VERSION "June 2, 2025"

NS_ :

BS_:

BU_: VEH CH Receiver Receiver ChassisBus VehicleBus PartyBus

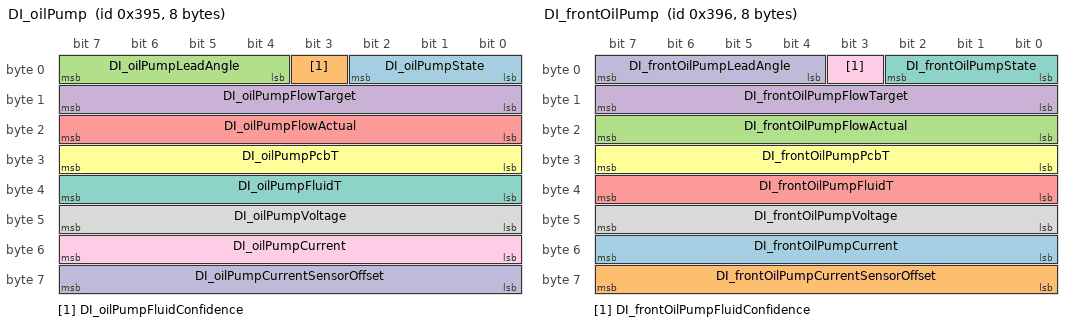
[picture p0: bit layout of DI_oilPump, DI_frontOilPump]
BO_ 917 DI_oilPump: 8 VEH
 SG_ DI_oilPumpState : 0|3@1+ (1,0) [0|0] "" Vector__XXX
 SG_ DI_oilPumpFluidConfidence : 3|1@1+ (1,0) [0|0] "" Vector__XXX
 SG_ DI_oilPumpLeadAngle : 4|4@1+ (1.875,0) [0|28.125] "deg" Vector__XXX
 SG_ DI_oilPumpFlowTarget : 8|8@1+ (0.06,0) [0|0] "LPM" Vector__XXX
 SG_ DI_oilPumpFlowActual : 16|8@1+ (0.06,0) [0|0] "LPM" Vector__XXX
 SG_ DI_oilPumpPcbT : 24|8@1+ (1,-40) [0|0] "DegC" Vector__XXX
 SG_ DI_oilPumpFluidT : 32|8@1+ (1,-40) [0|0] "DegC" Vector__XXX
 SG_ DI_oilPumpVoltage : 40|8@1+ (0.1,0) [0|0] "V" Vector__XXX
 SG_ DI_oilPumpCurrent : 48|8@1+ (0.1,0) [0|0] "A" Vector__XXX
 SG_ DI_oilPumpCurrentSensorOffset : 56|8@1+ (0.005,0) [0|0] "A" Vector__XXX

BO_ 918 DI_frontOilPump: 8 VEH
 SG_ DI_frontOilPumpCurrent : 48|8@1+ (0.1,0) [0|0] "A" Vector__XXX
 SG_ DI_frontOilPumpCurrentSensorOffset : 56|8@1+ (0.005,0) [0|0] "A" Vector__XXX
 SG_ DI_frontOilPumpFlowActual : 16|8@1+ (0.06,0) [0|0] "LPM" Vector__XXX
 SG_ DI_frontOilPumpFlowTarget : 8|8@1+ (0.06,0) [0|0] "LPM" Vector__XXX
 SG_ DI_frontOilPumpFluidT : 32|8@1+ (1,-40) [0|0] "DegC" Vector__XXX
 SG_ DI_frontOilPumpPcbT : 24|8@1+ (1,-40) [0|0] "DegC" Vector__XXX
 SG_ DI_frontOilPumpState : 0|3@1+ (1,0) [0|0] "" Vector__XXX
 SG_ DI_frontOilPumpVoltage : 40|8@1+ (0.1,0) [0|0] "V" Vector__XXX
 SG_ DI_frontOilPumpFluidConfidence : 3|1@1+ (1,0) [0|0] "" Vector__XXX
 SG_ DI_frontOilPumpLeadAngle : 4|4@1+ (1.875,0) [0|28.125] "deg" Vector__XXX

BO_ 921 DAS_status: 8 CH
 SG_ DAS_autoLaneChangeState : 46|5@1+ (1,0) [0|0] "" Vector__XXX
 SG_ DAS_autoParked : 25|1@1+ (1,0) [0|0] "" Vector__XXX
 SG_ DAS_autoparkReady : 24|1@1+ (1,0) [0|0] "" Vector__XXX
 SG_ DAS_autoparkWaitingForBrake : 26|1@1+ (1,0) [0|0] "" Vector__XXX
 SG_ DAS_autopilotHandsOnState : 42|4@1+ (1,0) [0|0] "" Vector__XXX
 SG_ DAS_autopilotState : 0|4@1+ (1,0) [0|0] "" Vector__XXX
 SG_ DAS_blindSpotRearLeft : 4|2@1+ (1,0) [0|0] "" Vector__XXX
 SG_ DAS_blindSpotRearRight : 6|2@1+ (1,0) [0|0] "" Vector__XXX
 SG_ DAS_csaState : 35|2@1+ (1,0) [0|0] "" Vector__XXX
 SG_ DAS_fleetSpeedState : 40|2@1+ (1,0) [0|0] "" Vector__XXX
 SG_ DAS_forwardCollisionWarning : 22|2@1+ (1,0) [0|0] "" Vector__XXX
 SG_ DAS_fusedSpeedLimit : 8|5@1+ (5,0) [0|0] "kph/mph" Vector__XXX
 SG_ DAS_heaterState : 21|1@1+ (1,0) [0|0] "" Vector__XXX
 SG_ DAS_laneDepartureWarning : 37|3@1+ (1,0) [0|0] "" Vector__XXX
 SG_ DAS_sideCollisionAvoid : 30|2@1+ (1,0) [0|0] "" Vector__XXX
 SG_ DAS_sideCollisionInhibit : 34|1@1+ (1,0) [0|0] "" Vector__XXX
 SG_ DAS_sideCollisionWarning : 32|2@1+ (1,0) [0|0] "" Vector__XXX
 SG_ DAS_statusChecksum : 56|8@1+ (1,0) [0|0] "" Vector__XXX
 SG_ DAS_statusCounter : 52|4@1+ (1,0) [0|0] "" Vector__XXX
 SG_ DAS_summonAvailable : 51|1@1+ (1,0) [0|0] "" Vector__XXX
 SG_ DAS_summonClearedGate : 15|1@1+ (1,0) [0|0] "" Vector__XXX
 SG_ DAS_summonFwdLeashReached : 28|1@1+ (1,0) [0|0] "" Vector__XXX
 SG_ DAS_summonObstacle : 14|1@1+ (1,0) [0|0] "" Vector__XXX
 SG_ DAS_summonRvsLeashReached : 29|1@1+ (1,0) [0|0] "" Vector__XXX
 SG_ DAS_suppressSpeedWarning : 13|1@1+ (1,0) [0|0] "" Vector__XXX
 SG_ DAS_visionOnlySpeedLimit : 16|5@1+ (5,0) [0|0] "kph/mph" Vector__XXX

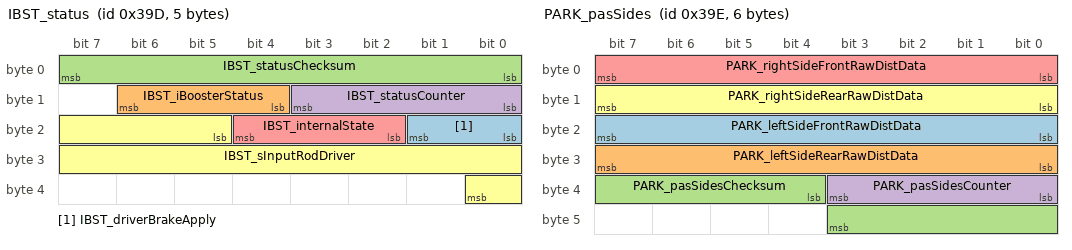
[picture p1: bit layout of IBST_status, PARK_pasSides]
BO_ 925 IBST_status: 5 CH
 SG_ IBST_driverBrakeApply : 16|2@1+ (1,0) [0|0] "" Vector__XXX
 SG_ IBST_iBoosterStatus : 12|3@1+ (1,0) [0|0] "" Vector__XXX
 SG_ IBST_statusChecksum : 0|8@1+ (1,0) [0|0] "" Vector__XXX
 SG_ IBST_statusCounter : 8|4@1+ (1,0) [0|0] "" Vector__XXX
 SG_ IBST_internalState : 18|3@1+ (1,0) [0|6] ""   X
 SG_ IBST_sInputRodDriver : 21|12@1+ (0.015625,-5) [-5|47] "mm"   X

BO_ 926 PARK_pasSides: 6 CH
 SG_ PARK_leftSideFrontRawDistData : 16|8@1+ (1,0) [0|0] "cm" Vector__XXX
 SG_ PARK_leftSideRearRawDistData : 24|8@1+ (1,0) [0|0] "cm" Vector__XXX
 SG_ PARK_pasSidesChecksum : 36|8@1+ (1,0) [0|0] "" Vector__XXX
 SG_ PARK_pasSidesCounter : 32|4@1+ (1,0) [0|0] "" Vector__XXX
 SG_ PARK_rightSideFrontRawDistData : 0|8@1+ (1,0) [0|0] "cm" Vector__XXX
 SG_ PARK_rightSideRearRawDistData : 8|8@1+ (1,0) [0|0] "cm" Vector__XXX

BO_ 927 FC_alertMatrix4: 8 VEH
 SG_ FC_a193_FCAlertPlaceholder : 0|1@1+ (1,0) [0|0] "" Vector__XXX

BO_ 929 VCFRONT_vehicleStatus: 8 VEH
 SG_ VCFRONT_12vStatusForDrive : 14|2@1+ (1,0) [0|0] "" Vector__XXX
 SG_ VCFRONT_2RowCenterUnbuckled : 38|2@1+ (1,0) [0|0] "" Vector__XXX
 SG_ VCFRONT_2RowLeftUnbuckled : 36|2@1+ (1,0) [0|0] "" Vector__XXX
 SG_ VCFRONT_2RowRightUnbuckled : 40|2@1+ (1,0) [0|0] "" Vector__XXX
 SG_ VCFRONT_APGlassHeaterState : 2|3@1+ (1,0) [0|0] "" Vector__XXX
 SG_ VCFRONT_LVLoadRequest : 9|1@1+ (1,0) [0|0] "" Vector__XXX
 SG_ VCFRONT_batterySupportRequest : 27|1@1+ (1,0) [0|0] "" Vector__XXX
 SG_ VCFRONT_bmsHvChargeEnable : 0|1@1+ (1,0) [0|0] "" Vector__XXX
 SG_ VCFRONT_diPowerOnState : 10|3@1+ (1,0) [0|0] "" Vector__XXX
 SG_ VCFRONT_driverBuckleStatus : 30|1@1+ (1,0) [0|0] "" Vector__XXX
 SG_ VCFRONT_driverDoorStatus : 31|1@1+ (1,0) [0|0] "" Vector__XXX
 SG_ VCFRONT_driverIsLeaving : 28|1@1+ (1,0) [0|0] "" Vector__XXX
 SG_ VCFRONT_driverIsLeavingAnySpeed : 13|1@1+ (1,0) [0|0] "" Vector__XXX
 SG_ VCFRONT_driverUnbuckled : 32|2@1+ (1,0) [0|0] "" Vector__XXX
 SG_ VCFRONT_is12VBatterySupported : 5|1@1+ (1,0) [0|0] "" Vector__XXX
 SG_ VCFRONT_ota12VSupportRequest : 29|1@1+ (1,0) [0|0] "" Vector__XXX
 SG_ VCFRONT_passengerUnbuckled : 34|2@1+ (1,0) [0|0] "" Vector__XXX
 SG_ VCFRONT_pcs12vVoltageTarget : 16|11@1+ (0.01,0) [0|0] "V" Vector__XXX
 SG_ VCFRONT_pcsEFuseVoltage : 42|10@1+ (0.1,0) [0|0] "V" Vector__XXX
 SG_ VCFRONT_preconditionRequest : 1|1@1+ (1,0) [0|0] "" Vector__XXX
 SG_ VCFRONT_standbySupplySupported : 6|1@1+ (1,0) [0|1] "" Vector__XXX
 SG_ VCFRONT_thermalSystemType : 5|1@1+ (1,0) [0|1] "" Vector__XXX
 SG_ VCFRONT_vehicleStatusChecksum : 56|8@1+ (1,0) [0|0] "" Vector__XXX
 SG_ VCFRONT_vehicleStatusCounter : 52|4@1+ (1,0) [0|0] "" Vector__XXX

BO_ 930 VCLEFT_status: 8 VEH
 SG_ VCLEFT_statusIndex M : 0|1@1+ (1,0) [0|0] "" Vector__XXX
 SG_ VCLEFT_loadShedPriority m0 : 1|8@1+ (1,0) [0|0] "" Vector__XXX
 SG_ VCLEFT_vehiclePowerStateDBG m0 : 9|2@1+ (1,0) [0|0] "" Vector__XXX
 SG_ VCLEFT_consoleDoorAssist m0 : 11|1@1+ (1,0) [0|0] "" Vector__XXX
 SG_ VCLEFT_OTAState m0 : 12|1@1+ (1,0) [0|0] "" Vector__XXX
 SG_ VCLEFT_5AVoltage m0 : 13|10@1+ (0.00544368,0) [0|0] "V" Vector__XXX
 SG_ VCLEFT_vbatProt m0 : 23|12@1+ (0.00544368,0) [0|0] "V" Vector__XXX
 SG_ VCLEFT_footwellLightCurrent m0 : 35|12@1- (0.1,0) [0|0] "mA" Vector__XXX
 SG_ VCLEFT_swcInputVoltage m0 : 47|8@1+ (0.1,0) [0|0] "V" Vector__XXX
 SG_ VCLEFT_swcPCBATemperature m0 : 55|8@1- (1,-40) [0|0] "degC" Vector__XXX
 SG_ VCLEFT_pcbaTemperature m1 : 1|11@1+ (0.125,-40) [0|0] "degC" Vector__XXX
 SG_ VCLEFT_DIeFuseCurrent m1 : 12|12@1- (0.1,0) [0|0] "A" Vector__XXX
 SG_ VCLEFT_DIeFuseFault m1 : 24|1@1+ (1,0) [0|0] "" Vector__XXX
 SG_ VCLEFT_tlcPCBATemperature m1 : 32|8@1- (1,-40) [0|0] "degC" Vector__XXX

BO_ 932 PCS_alertMatrix: 8 VEH
 SG_ PCS_matrixIndex M : 0|4@1+ (1,0) [0|0] "" Vector__XXX
 SG_ PCS_a001_chgHwInputOc m0 : 4|1@1+ (1,0) [0|0] "" Vector__XXX
 SG_ PCS_a002_chgHwOutputOc m0 : 5|1@1+ (1,0) [0|0] "" Vector__XXX
 SG_ PCS_a003_chgHwInputOv m0 : 6|1@1+ (1,0) [0|0] "" Vector__XXX
 SG_ PCS_a004_chgHwIntBusOv m0 : 7|1@1+ (1,0) [0|0] "" Vector__XXX
 SG_ PCS_a005_chgOutputOv m0 : 8|1@1+ (1,0) [0|0] "" Vector__XXX
 SG_ PCS_a006_chgPrechargeFailedScr m0 : 9|1@1+ (1,0) [0|0] "" Vector__XXX
 SG_ PCS_a007_chgPhaseTempHot m0 : 10|1@1+ (1,0) [0|0] "" Vector__XXX
 SG_ PCS_a008_chgPhaseOverTemp m0 : 11|1@1+ (1,0) [0|0] "" Vector__XXX
 SG_ PCS_a009_chgPfcCurrentRegulation m0 : 12|1@1+ (1,0) [0|0] "" Vector__XXX
 SG_ PCS_a010_chgIntBusVRegulation m0 : 13|1@1+ (1,0) [0|0] "" Vector__XXX
 SG_ PCS_a011_chgLlcCurrentRegulation m0 : 14|1@1+ (1,0) [0|0] "" Vector__XXX
 SG_ PCS_a012_chgPfcIBandTracerFault m0 : 15|1@1+ (1,0) [0|0] "" Vector__XXX
 SG_ PCS_a013_chgPrechargeFailedBoost m0 : 16|1@1+ (1,0) [0|0] "" Vector__XXX
 SG_ PCS_a014_chgTempRationality m0 : 17|1@1+ (1,0) [0|0] "" Vector__XXX
 SG_ PCS_a015_chg12vUv m0 : 18|1@1+ (1,0) [0|0] "" Vector__XXX
 SG_ PCS_a016_chgAllPhasesFaulted m0 : 19|1@1+ (1,0) [0|0] "" Vector__XXX
 SG_ PCS_a017_chgWallPowerRemoval m0 : 20|1@1+ (1,0) [0|0] "" Vector__XXX
 SG_ PCS_a018_chgUnknownGridConfig m0 : 21|1@1+ (1,0) [0|0] "" Vector__XXX
 SG_ PCS_a019_acChargePowerLimited m0 : 22|1@1+ (1,0) [0|0] "" Vector__XXX
 SG_ PCS_a020_chgEnableLineMismatch m0 : 23|1@1+ (1,0) [0|0] "" Vector__XXX
 SG_ PCS_a021_hvpMia m0 : 24|1@1+ (1,0) [0|0] "" Vector__XXX
 SG_ PCS_a022_bmsMia m0 : 25|1@1+ (1,0) [0|0] "" Vector__XXX
 SG_ PCS_a023_cpMia m0 : 26|1@1+ (1,0) [0|0] "" Vector__XXX
 SG_ PCS_a024_vcfrontMia m0 : 27|1@1+ (1,0) [0|0] "" Vector__XXX
 SG_ PCS_a025_cpu2Malfunction m0 : 28|1@1+ (1,0) [0|0] "" Vector__XXX
 SG_ PCS_a026_watchdogAlarmed m0 : 29|1@1+ (1,0) [0|0] "" Vector__XXX
 SG_ PCS_a027_chgInsufficientCooling m0 : 30|1@1+ (1,0) [0|0] "" Vector__XXX
 SG_ PCS_a028_chgOutputUv m0 : 31|1@1+ (1,0) [0|0] "" Vector__XXX
 SG_ PCS_a029_chgPowerRationality m0 : 32|1@1+ (1,0) [0|0] "" Vector__XXX
 SG_ PCS_a030_canRationality m0 : 33|1@1+ (1,0) [0|0] "" Vector__XXX
 SG_ PCS_a031_uiMia m0 : 34|1@1+ (1,0) [0|0] "" Vector__XXX
 SG_ PCS_a032_gtwMia m0 : 35|1@1+ (1,0) [0|0] "" Vector__XXX
 SG_ PCS_a033_hvBusUv m0 : 36|1@1+ (1,0) [0|0] "" Vector__XXX
 SG_ PCS_a034_hvBusOv m0 : 37|1@1+ (1,0) [0|0] "" Vector__XXX
 SG_ PCS_a035_lvBusUv m0 : 38|1@1+ (1,0) [0|0] "" Vector__XXX
 SG_ PCS_a036_lvBusOv m0 : 39|1@1+ (1,0) [0|0] "" Vector__XXX
 SG_ PCS_a037_resonantTankOc m0 : 40|1@1+ (1,0) [0|0] "" Vector__XXX
 SG_ PCS_a038_claFaulted m0 : 41|1@1+ (1,0) [0|0] "" Vector__XXX
 SG_ PCS_a039_sdModuleClkFault m0 : 42|1@1+ (1,0) [0|0] "" Vector__XXX
 SG_ PCS_a040_dcdcMaxPowerReached m0 : 43|1@1+ (1,0) [0|0] "" Vector__XXX
 SG_ PCS_a041_dcdcOverTemp m0 : 44|1@1+ (1,0) [0|0] "" Vector__XXX
 SG_ PCS_a042_dcdcEnableLineMismatch m0 : 45|1@1+ (1,0) [0|0] "" Vector__XXX
 SG_ PCS_a043_hvBusPrechargeFailure m0 : 46|1@1+ (1,0) [0|0] "" Vector__XXX
 SG_ PCS_a044_12vSupportRegulation m0 : 47|1@1+ (1,0) [0|0] "" Vector__XXX
 SG_ PCS_a045_hvBusLowImpedance m0 : 48|1@1+ (1,0) [0|0] "" Vector__XXX
 SG_ PCS_a046_hvBusHighImpedence m0 : 49|1@1+ (1,0) [0|0] "" Vector__XXX
 SG_ PCS_a047_lvBusLowImpedance m0 : 50|1@1+ (1,0) [0|0] "" Vector__XXX
 SG_ PCS_a048_lvBusHighImpedance m0 : 51|1@1+ (1,0) [0|0] "" Vector__XXX
 SG_ PCS_a049_dcdcTempRationality m0 : 52|1@1+ (1,0) [0|0] "" Vector__XXX
 SG_ PCS_a050_dcdc12VsupportFaulted m0 : 53|1@1+ (1,0) [0|0] "" Vector__XXX
 SG_ PCS_a051_chgIntBusUv m0 : 54|1@1+ (1,0) [0|0] "" Vector__XXX
 SG_ PCS_a052_acVoltageNotPresent m0 : 55|1@1+ (1,0) [0|0] "" Vector__XXX
 SG_ PCS_a053_chgInputVDropHigh m0 : 56|1@1+ (1,0) [0|0] "" Vector__XXX
 SG_ PCS_a054_chgInputVDropTooHigh m0 : 57|1@1+ (1,0) [0|0] "" Vector__XXX
 SG_ PCS_a055_chgLineImedanceHigh m0 : 58|1@1+ (1,0) [0|0] "" Vector__XXX
 SG_ PCS_a056_chgLineImedanceTooHigh m0 : 59|1@1+ (1,0) [0|0] "" Vector__XXX
 SG_ PCS_a057_chgInputOverFreq m0 : 60|1@1+ (1,0) [0|0] "" Vector__XXX
 SG_ PCS_a058_chgInputUnderFreq m0 : 61|1@1+ (1,0) [0|0] "" Vector__XXX
 SG_ PCS_a059_chgInputOvRms m0 : 62|1@1+ (1,0) [0|0] "" Vector__XXX
 SG_ PCS_a060_chgInputOvPeak m0 : 63|1@1+ (1,0) [0|0] "" Vector__XXX
 SG_ PCS_a061_chgVLineRationality m1 : 4|1@1+ (1,0) [0|0] "" Vector__XXX
 SG_ PCS_a062_chgILineRationality m1 : 5|1@1+ (1,0) [0|0] "" Vector__XXX
 SG_ PCS_a063_chgVOutRationality m1 : 6|1@1+ (1,0) [0|0] "" Vector__XXX
 SG_ PCS_a064_chgIOutRationality m1 : 7|1@1+ (1,0) [0|0] "" Vector__XXX
 SG_ PCS_a065_chgPllNotLocked m1 : 8|1@1+ (1,0) [0|0] "" Vector__XXX
 SG_ PCS_a066_dcdcHvRationality m1 : 9|1@1+ (1,0) [0|0] "" Vector__XXX
 SG_ PCS_a067_dcdcLvRationality m1 : 10|1@1+ (1,0) [0|0] "" Vector__XXX
 SG_ PCS_a068_dcdcTankvRationality m1 : 11|1@1+ (1,0) [0|0] "" Vector__XXX
 SG_ PCS_a069_chgPfcLineDidt m1 : 12|1@1+ (1,0) [0|0] "" Vector__XXX
 SG_ PCS_a070_chgPfcLineDvdt m1 : 13|1@1+ (1,0) [0|0] "" Vector__XXX
 SG_ PCS_a071_chgPfcILoopRationality m1 : 14|1@1+ (1,0) [0|0] "" Vector__XXX
 SG_ PCS_a072_cpu2ClaStopped m1 : 15|1@1+ (1,0) [0|0] "" Vector__XXX
 SG_ PCS_a073_unexpectedAcInputVoltage m1 : 16|1@1+ (1,0) [0|0] "" Vector__XXX
 SG_ PCS_a074_hvBusDischargeFailure m1 : 17|1@1+ (1,0) [0|0] "" Vector__XXX
 SG_ PCS_a075_hvBusDischargeTimeout m1 : 18|1@1+ (1,0) [0|0] "" Vector__XXX
 SG_ PCS_a076_dcdcEnDeassertedErr m1 : 19|1@1+ (1,0) [0|0] "" Vector__XXX
 SG_ PCS_a077_microGridEnergyLow m1 : 20|1@1+ (1,0) [0|0] "" Vector__XXX
 SG_ PCS_a078_chgStopDcdcTooHot m1 : 21|1@1+ (1,0) [0|0] "" Vector__XXX
 SG_ PCS_a079_eepromOperationError m1 : 22|1@1+ (1,0) [0|0] "" Vector__XXX
 SG_ PCS_a080_damagedPhaseDetected m1 : 23|1@1+ (1,0) [0|0] "" Vector__XXX
 SG_ PCS_a081_dcdcPchgTimeout m1 : 24|1@1+ (1,0) [0|0] "" Vector__XXX
 SG_ PCS_a082_dcdcPchgUnsafeDiVoltage m1 : 25|1@1+ (1,0) [0|0] "" Vector__XXX
 SG_ PCS_a083_triggerOdin m1 : 26|1@1+ (1,0) [0|0] "" Vector__XXX
 SG_ PCS_a084_dcdcPchgStartVoltages m1 : 27|1@1+ (1,0) [0|0] "" Vector__XXX
 SG_ PCS_a085_dcdcFetsNotSwitching m1 : 28|1@1+ (1,0) [0|0] "" Vector__XXX
 SG_ PCS_a086_dcdcInsufficientCooling m1 : 29|1@1+ (1,0) [0|0] "" Vector__XXX
 SG_ PCS_a087_nvramRecordStatusError m1 : 30|1@1+ (1,0) [0|0] "" Vector__XXX
 SG_ PCS_a088_pchgParameters m1 : 31|1@1+ (1,0) [0|0] "" Vector__XXX
 SG_ PCS_a089_hvBusDischargeIrrational m1 : 32|1@1+ (1,0) [0|0] "" Vector__XXX

BO_ 933 DIS_alertMatrix1: 8 VEH
 SG_ DIS_a001_hwPhaseAgateDrive : 0|1@1+ (1,0) [0|0] "" Vector__XXX
 SG_ DIS_a002_hwPhaseBgateDrive : 1|1@1+ (1,0) [0|0] "" Vector__XXX
 SG_ DIS_a003_hwPhaseCgateDrive : 2|1@1+ (1,0) [0|0] "" Vector__XXX
 SG_ DIS_a004_hwPhaseApeak : 3|1@1+ (1,0) [0|0] "" Vector__XXX
 SG_ DIS_a005_hwPhaseBpeak : 4|1@1+ (1,0) [0|0] "" Vector__XXX
 SG_ DIS_a006_hwPhaseCpeak : 5|1@1+ (1,0) [0|0] "" Vector__XXX
 SG_ DIS_a007_hwHvilNotPresent : 6|1@1+ (1,0) [0|0] "" Vector__XXX
 SG_ DIS_a008_hwEncoderA : 7|1@1+ (1,0) [0|0] "" Vector__XXX
 SG_ DIS_a009_hwEncoderB : 8|1@1+ (1,0) [0|0] "" Vector__XXX
 SG_ DIS_a011_swPowerStageNotReady : 10|1@1+ (1,0) [0|0] "" Vector__XXX
 SG_ DIS_a014_activeDamping : 13|1@1+ (1,0) [0|0] "" Vector__XXX
 SG_ DIS_a016_safeStateApplied : 15|1@1+ (1,0) [0|0] "" Vector__XXX
 SG_ DIS_a017_hwPedalMonitor : 16|1@1+ (1,0) [0|0] "" Vector__XXX
 SG_ DIS_a018_hw12vSupplyUV : 17|1@1+ (1,0) [0|0] "" Vector__XXX
 SG_ DIS_a019_hwAccelPedalPower : 18|1@1+ (1,0) [0|0] "" Vector__XXX
 SG_ DIS_a020_hwMotorEncoder : 19|1@1+ (1,0) [0|0] "" Vector__XXX
 SG_ DIS_a021_hwBusOV : 20|1@1+ (1,0) [0|0] "" Vector__XXX
 SG_ DIS_a022_hw5vSupplyUV : 21|1@1+ (1,0) [0|0] "" Vector__XXX
 SG_ DIS_a024_selfTest : 23|1@1+ (1,0) [0|0] "" Vector__XXX
 SG_ DIS_a025_phaseApeak : 24|1@1+ (1,0) [0|0] "" Vector__XXX
 SG_ DIS_a026_phaseBpeak : 25|1@1+ (1,0) [0|0] "" Vector__XXX
 SG_ DIS_a027_phaseCpeak : 26|1@1+ (1,0) [0|0] "" Vector__XXX
 SG_ DIS_a028_phaseArms : 27|1@1+ (1,0) [0|0] "" Vector__XXX
 SG_ DIS_a029_phaseBrms : 28|1@1+ (1,0) [0|0] "" Vector__XXX
 SG_ DIS_a030_phaseCrms : 29|1@1+ (1,0) [0|0] "" Vector__XXX
 SG_ DIS_a031_phaseAcurrentOffset : 30|1@1+ (1,0) [0|0] "" Vector__XXX
 SG_ DIS_a032_phaseBcurrentOffset : 31|1@1+ (1,0) [0|0] "" Vector__XXX
 SG_ DIS_a033_phaseAcurrentSensor : 32|1@1+ (1,0) [0|0] "" Vector__XXX
 SG_ DIS_a034_phaseBcurrentSensor : 33|1@1+ (1,0) [0|0] "" Vector__XXX
 SG_ DIS_a035_phaseCurrentBalance : 34|1@1+ (1,0) [0|0] "" Vector__XXX
 SG_ DIS_a036_busOV : 35|1@1+ (1,0) [0|0] "" Vector__XXX
 SG_ DIS_a037_busUV : 36|1@1+ (1,0) [0|0] "" Vector__XXX
 SG_ DIS_a038_busVsensor : 37|1@1+ (1,0) [0|0] "" Vector__XXX
 SG_ DIS_a040_disMIA : 39|1@1+ (1,0) [0|0] "" Vector__XXX
 SG_ DIS_a042_inletSensor : 41|1@1+ (1,0) [0|0] "" Vector__XXX
 SG_ DIS_a043_outletOT : 42|1@1+ (1,0) [0|0] "" Vector__XXX
 SG_ DIS_a044_outletUT : 43|1@1+ (1,0) [0|0] "" Vector__XXX
 SG_ DIS_a045_outletSensor : 44|1@1+ (1,0) [0|0] "" Vector__XXX
 SG_ DIS_a046_statorOT : 45|1@1+ (1,0) [0|0] "" Vector__XXX
 SG_ DIS_a047_statorSensor1 : 46|1@1+ (1,0) [0|0] "" Vector__XXX
 SG_ DIS_a050_noStatorSensor : 49|1@1+ (1,0) [0|0] "" Vector__XXX
 SG_ DIS_a054_driveInverterOT : 53|1@1+ (1,0) [0|0] "" Vector__XXX
 SG_ DIS_a055_trqCrossCheck : 54|1@1+ (1,0) [0|0] "" Vector__XXX
 SG_ DIS_a056_ambientOT : 55|1@1+ (1,0) [0|0] "" Vector__XXX
 SG_ DIS_a057_ambientUT : 56|1@1+ (1,0) [0|0] "" Vector__XXX
 SG_ DIS_a058_ambientSensor : 57|1@1+ (1,0) [0|0] "" Vector__XXX
 SG_ DIS_a059_heatsinkOT : 58|1@1+ (1,0) [0|0] "" Vector__XXX
 SG_ DIS_a060_heatsinkUT : 59|1@1+ (1,0) [0|0] "" Vector__XXX
 SG_ DIS_a061_heatsinkSensor : 60|1@1+ (1,0) [0|0] "" Vector__XXX
 SG_ DIS_a062_systemLimpMode : 61|1@1+ (1,0) [0|0] "" Vector__XXX
 SG_ DIS_a064_torqueIntervention : 63|1@1+ (1,0) [0|0] "" Vector__XXX

BO_ 937 DAS_telemetry: 8 VEH
 SG_ DAS_telemetryMultiplexer M : 0|8@1+ (1,0) [0|0] "" Vector__XXX
 SG_ DAS_telLeftLaneType m0 : 8|3@1+ (1,0) [0|0] "" Vector__XXX
 SG_ DAS_telRightLaneType m0 : 11|3@1+ (1,0) [0|0] "" Vector__XXX
 SG_ DAS_telLeftMarkerQuality m0 : 14|2@1+ (1,0) [0|0] "" Vector__XXX
 SG_ DAS_telRightMarkerQuality m0 : 16|2@1+ (1,0) [0|0] "" Vector__XXX
 SG_ DAS_telLeftMarkerColor m0 : 18|2@1+ (1,0) [0|0] "" Vector__XXX
 SG_ DAS_telRightMarkerColor m0 : 20|2@1+ (1,0) [0|0] "" Vector__XXX
 SG_ DAS_telLeftLaneCrossing m0 : 22|1@1+ (1,0) [0|0] "" Vector__XXX
 SG_ DAS_telRightLaneCrossing m0 : 23|1@1+ (1,0) [0|0] "" Vector__XXX
 SG_ DAS_MCPObserved m1 : 8|1@1+ (1,0) [0|0] "" Vector__XXX
 SG_ DAS_accReengaged m1 : 9|1@1+ (1,0) [0|0] "" Vector__XXX
 SG_ DAS_pedestrianInFOVBeforeIntr m1 : 10|1@1+ (1,0) [0|0] "" Vector__XXX
 SG_ DAS_pedestrianInFOVAfterIntr m1 : 11|1@1+ (1,0) [0|0] "" Vector__XXX
 SG_ DAS_camFreeSpaceBeforeIntr m1 : 12|1@1+ (1,0) [0|0] "" Vector__XXX
 SG_ DAS_camFreeSpaceAfterIntr m1 : 13|1@1+ (1,0) [0|0] "" Vector__XXX
 SG_ DAS_timeOfIntervention m1 : 14|6@1+ (0.25,0) [0|0] "s" Vector__XXX
 SG_ DAS_timeOfFirstPedestrian m1 : 20|6@1+ (0.25,0) [0|0] "s" Vector__XXX
 SG_ DAS_timeOfACCReengaging m1 : 26|6@1+ (0.25,0) [0|0] "s" Vector__XXX
 SG_ DAS_durationOfPrevACCStandstill m1 : 32|6@1+ (0.5,0) [0|0] "s" Vector__XXX
 SG_ DAS_maxAbsSteeringWheelAngle m1 : 38|7@1+ (2,0) [0|0] "degrees" Vector__XXX
 SG_ DAS_targetRelvelAtIntervention m1 : 45|6@1+ (0.25,-2) [0|0] "m/s" Vector__XXX
 SG_ DAS_targetDistAtIntervention m1 : 51|6@1+ (0.5,0) [0|0] "m" Vector__XXX
 SG_ DAS_egoSpeedAtIntervention m1 : 57|6@1+ (0.5,0) [0|0] "m/s" Vector__XXX
 SG_ DAS_stopSignLongitudinalDist m2 : 8|10@1+ (0.1,0) [0|0] "m" Vector__XXX
 SG_ DAS_stopSignLateralDist m2 : 18|8@1+ (0.25,-32) [0|0] "m" Vector__XXX
 SG_ DAS_stopSignHeight m2 : 26|6@1+ (0.1,0) [0|0] "m" Vector__XXX
 SG_ DAS_stopSignStopLineDistance m2 : 32|10@1+ (0.1,-20) [0|0] "m" Vector__XXX
 SG_ DAS_stopSignCIPVDistance m2 : 42|6@1+ (0.5,0) [0|0] "m" Vector__XXX
 SG_ DAS_stopSignHostAccel m2 : 48|10@1+ (0.01,-5) [0|0] "m/s^2" Vector__XXX
 SG_ DAS_stopSignCrossingWarning m2 : 58|1@1+ (1,0) [0|0] "" Vector__XXX
 SG_ DAS_stopSignIndex m2 : 59|4@1+ (1,0) [0|0] "" Vector__XXX
 SG_ DAS_csaOverride m7 : 10|1@1+ (1,0) [0|0] "" Vector__XXX
 SG_ DAS_csaIntState m7 : 11|3@1+ (1,0) [0|0] "" Vector__XXX
 SG_ DAS_csaEnableSpeed m7 : 14|12@1+ (0.05,-25) [0|0] "MPH" Vector__XXX
 SG_ DAS_csaDisableSpeed m7 : 26|12@1+ (0.05,-25) [0|0] "MPH" Vector__XXX
 SG_ DAS_csaFiltCurv m7 : 40|16@1- (1e-06,0) [0|0] "1/m" Vector__XXX
 SG_ DAS_csaMeasLatAccel m7 : 56|8@1+ (0.08,-10.24) [0|0] "m/s^2" Vector__XXX
 SG_ DAS_soCamCipvStatus m8 : 8|2@1+ (1,0) [0|0] "" Vector__XXX
 SG_ DAS_soRad5Status m8 : 10|2@1+ (1,0) [0|0] "" Vector__XXX
 SG_ DAS_soRad1Status m8 : 12|2@1+ (1,0) [0|0] "" Vector__XXX
 SG_ DAS_soCamCipvDx m8 : 14|6@1+ (2,0) [0|0] "m" Vector__XXX
 SG_ DAS_soRad1Dx m8 : 20|6@1+ (2,0) [0|0] "m" Vector__XXX
 SG_ DAS_soRad5Dx m8 : 26|6@1+ (2,0) [0|0] "m" Vector__XXX
 SG_ DAS_soCamCipvDy m8 : 32|5@1+ (0.4,-6.4) [0|0] "m" Vector__XXX
 SG_ DAS_soRad5Dy m8 : 37|5@1+ (0.4,-6.4) [0|0] "m" Vector__XXX
 SG_ DAS_soCamCipvVx m8 : 42|5@1+ (1,0) [0|0] "m/s" Vector__XXX
 SG_ DAS_soRad5ObstProb m8 : 47|4@1+ (0.0625,0) [0|0] "probability" Vector__XXX
 SG_ DAS_soRad5Dz m8 : 51|6@1+ (0.25,-5) [0|0] "m" Vector__XXX
 SG_ DAS_soRad5powerdB m8 : 57|7@1+ (2,0) [0|0] "dB" Vector__XXX
 SG_ DAS_assPrevSetSpeed m9 : 8|8@1+ (0.25,0) [0|0] "m/s" Vector__XXX
 SG_ DAS_assNewSetSpeed m9 : 16|8@1+ (0.25,0) [0|0] "m/s" Vector__XXX
 SG_ DAS_assFusedSpeedLimit m9 : 24|6@1+ (1,0) [0|0] "m/s" Vector__XXX
 SG_ DAS_assAutosteerActive m9 : 30|1@1+ (1,0) [0|0] "" Vector__XXX
 SG_ DAS_assSmartSpeedActive m9 : 31|1@1+ (1,0) [0|0] "" Vector__XXX

BO_ 938 HVP_alertMatrix1: 8 VEH
 SG_ HVP_w001_WatchdogReset : 0|1@1+ (1,0) [0|0] "" Vector__XXX
 SG_ HVP_w002_UnusedAlert2 : 1|1@1+ (1,0) [0|0] "" Vector__XXX
 SG_ HVP_w003_SwAssertion : 2|1@1+ (1,0) [0|0] "" Vector__XXX
 SG_ HVP_w004_CrashEvent : 3|1@1+ (1,0) [0|0] "" Vector__XXX
 SG_ HVP_w005_OverDchgCurrentFault : 4|1@1+ (1,0) [0|0] "" Vector__XXX
 SG_ HVP_w006_OverChargeCurrentFault : 5|1@1+ (1,0) [0|0] "" Vector__XXX
 SG_ HVP_w007_OverCurrentFault : 6|1@1+ (1,0) [0|0] "" Vector__XXX
 SG_ HVP_w008_OverTemperatureFault : 7|1@1+ (1,0) [0|0] "" Vector__XXX
 SG_ HVP_w009_OverVoltageFault : 8|1@1+ (1,0) [0|0] "" Vector__XXX
 SG_ HVP_w010_UnderVoltageFault : 9|1@1+ (1,0) [0|0] "" Vector__XXX
 SG_ HVP_w011_PrimaryBmbMiaFault : 10|1@1+ (1,0) [0|0] "" Vector__XXX
 SG_ HVP_w012_SecondaryBmbMiaFault : 11|1@1+ (1,0) [0|0] "" Vector__XXX
 SG_ HVP_w013_BmbMismatchFault : 12|1@1+ (1,0) [0|0] "" Vector__XXX
 SG_ HVP_w014_BmsHviMiaFault : 13|1@1+ (1,0) [0|0] "" Vector__XXX
 SG_ HVP_w015_CpMiaFault : 14|1@1+ (1,0) [0|0] "" Vector__XXX
 SG_ HVP_w016_PcsMiaFault : 15|1@1+ (1,0) [0|0] "" Vector__XXX
 SG_ HVP_w017_BmsFault : 16|1@1+ (1,0) [0|0] "" Vector__XXX
 SG_ HVP_w018_PcsFault : 17|1@1+ (1,0) [0|0] "" Vector__XXX
 SG_ HVP_w019_CpFault : 18|1@1+ (1,0) [0|0] "" Vector__XXX
 SG_ HVP_w020_ShuntHwMiaFault : 19|1@1+ (1,0) [0|0] "" Vector__XXX
 SG_ HVP_w021_PyroMiaFault : 20|1@1+ (1,0) [0|0] "" Vector__XXX
 SG_ HVP_w022_hvsMiaFault : 21|1@1+ (1,0) [0|0] "" Vector__XXX
 SG_ HVP_w024_Supply12vFault : 23|1@1+ (1,0) [0|0] "" Vector__XXX
 SG_ HVP_w025_VerSupplyFault : 24|1@1+ (1,0) [0|0] "" Vector__XXX
 SG_ HVP_w026_HvilFault : 25|1@1+ (1,0) [0|0] "" Vector__XXX
 SG_ HVP_w027_BmsHvsMiaFault : 26|1@1+ (1,0) [0|0] "" Vector__XXX
 SG_ HVP_w028_PackVoltMismatchFault : 27|1@1+ (1,0) [0|0] "" Vector__XXX
 SG_ HVP_w029_EnsMiaFault : 28|1@1+ (1,0) [0|0] "" Vector__XXX
 SG_ HVP_w030_PackPosCtrArcFault : 29|1@1+ (1,0) [0|0] "" Vector__XXX
 SG_ HVP_w031_packNegCtrArcFault : 30|1@1+ (1,0) [0|0] "" Vector__XXX
 SG_ HVP_w032_ShuntHwAndBmsMiaFault : 31|1@1+ (1,0) [0|0] "" Vector__XXX
 SG_ HVP_w033_fcContHwFault : 32|1@1+ (1,0) [0|0] "" Vector__XXX
 SG_ HVP_w034_robinOverVoltageFault : 33|1@1+ (1,0) [0|0] "" Vector__XXX
 SG_ HVP_w035_packContHwFault : 34|1@1+ (1,0) [0|0] "" Vector__XXX
 SG_ HVP_w036_pyroFuseBlown : 35|1@1+ (1,0) [0|0] "" Vector__XXX
 SG_ HVP_w037_pyroFuseFailedToBlow : 36|1@1+ (1,0) [0|0] "" Vector__XXX
 SG_ HVP_w038_CpilFault : 37|1@1+ (1,0) [0|0] "" Vector__XXX
 SG_ HVP_w039_PackContactorFellOpen : 38|1@1+ (1,0) [0|0] "" Vector__XXX
 SG_ HVP_w040_FcContactorFellOpen : 39|1@1+ (1,0) [0|0] "" Vector__XXX
 SG_ HVP_w041_packCtrCloseBlocked : 40|1@1+ (1,0) [0|0] "" Vector__XXX
 SG_ HVP_w042_fcCtrCloseBlocked : 41|1@1+ (1,0) [0|0] "" Vector__XXX
 SG_ HVP_w043_packContactorForceOpen : 42|1@1+ (1,0) [0|0] "" Vector__XXX
 SG_ HVP_w044_fcContactorForceOpen : 43|1@1+ (1,0) [0|0] "" Vector__XXX
 SG_ HVP_w045_dcLinkOverVoltage : 44|1@1+ (1,0) [0|0] "" Vector__XXX
 SG_ HVP_w046_shuntOverTemperature : 45|1@1+ (1,0) [0|0] "" Vector__XXX
 SG_ HVP_w047_passivePyroDeploy : 46|1@1+ (1,0) [0|0] "" Vector__XXX
 SG_ HVP_w048_logUploadRequest : 47|1@1+ (1,0) [0|0] "" Vector__XXX
 SG_ HVP_w049_packCtrCloseFailed : 48|1@1+ (1,0) [0|0] "" Vector__XXX
 SG_ HVP_w050_fcCtrCloseFailed : 49|1@1+ (1,0) [0|0] "" Vector__XXX
 SG_ HVP_w051_shuntThermistorMia : 50|1@1+ (1,0) [0|0] "" Vector__XXX

BO_ 941 TAS_warningMatrix4: 8 VEH
 SG_ TAS_w200_jackModeActive : 7|1@1+ (1,0) [0|0] "" Vector__XXX
 SG_ TAS_w201_lowHVBattery : 8|1@1+ (1,0) [0|0] "" Vector__XXX
 SG_ TAS_w210_outOfRangeCalibration : 17|1@1+ (1,0) [0|0] "" Vector__XXX
 SG_ TAS_w211_noRideHeightCalib : 18|1@1+ (1,0) [0|0] "" Vector__XXX
 SG_ TAS_w212_noCurrentSenseCalib : 19|1@1+ (1,0) [0|0] "" Vector__XXX
 SG_ TAS_w213_yellowWarningLamp : 20|1@1+ (1,0) [0|0] "" Vector__XXX
 SG_ TAS_w214_redWarningLamp : 21|1@1+ (1,0) [0|0] "" Vector__XXX
 SG_ TAS_w215_limpHomeMode10 : 22|1@1+ (1,0) [0|0] "" Vector__XXX
 SG_ TAS_w216_limpHomeMode20 : 23|1@1+ (1,0) [0|0] "" Vector__XXX
 SG_ TAS_w217_limpHomeMode30 : 24|1@1+ (1,0) [0|0] "" Vector__XXX
 SG_ TAS_w218_limpHomeMode40 : 25|1@1+ (1,0) [0|0] "" Vector__XXX
 SG_ TAS_w220_exhaustGalleryFault : 27|1@1+ (1,0) [0|0] "" Vector__XXX
 SG_ TAS_w221_valveLeakDetected : 28|1@1+ (1,0) [0|0] "" Vector__XXX
 SG_ TAS_w222_compressorPrefillFault : 29|1@1+ (1,0) [0|0] "" Vector__XXX
 SG_ TAS_w223_blockedAirline : 30|1@1+ (1,0) [0|0] "" Vector__XXX
 SG_ TAS_w224_openAirline : 31|1@1+ (1,0) [0|0] "" Vector__XXX
 SG_ TAS_w225_galleryPressureTooHigh : 32|1@1+ (1,0) [0|0] "" Vector__XXX
 SG_ TAS_w226_PWMfastDetectFL : 33|1@1+ (1,0) [0|0] "" Vector__XXX
 SG_ TAS_w227_PWMfastDetectFR : 34|1@1+ (1,0) [0|0] "" Vector__XXX
 SG_ TAS_w228_PWMfastDetectRL : 35|1@1+ (1,0) [0|0] "" Vector__XXX
 SG_ TAS_w229_PWMfastDetectRR : 36|1@1+ (1,0) [0|0] "" Vector__XXX

BO_ 945 DAS_telemetryFurniture: 8 VEH
 SG_ DAS_TF_multiplexer M : 0|5@1+ (1,0) [0|0] "" Vector__XXX
 SG_ DAS_TF_furnitureIndex0 m0 : 5|8@1+ (1,0) [0|0] "" Vector__XXX
 SG_ DAS_TF_distTraveled m0 : 13|11@1+ (0.1,0) [0|0] "m" Vector__XXX
 SG_ DAS_TF_llType m0 : 24|3@1+ (1,0) [0|0] "" Vector__XXX
 SG_ DAS_TF_rlType m0 : 27|3@1+ (1,0) [0|0] "" Vector__XXX
 SG_ DAS_TF_cipvDist m0 : 30|9@1+ (0.1,0) [0|0] "m" Vector__XXX
 SG_ DAS_TF_timeOfDay m0 : 39|3@1+ (1,0) [0|0] "" Vector__XXX
 SG_ DAS_TF_furnitureType m0 : 42|3@1+ (1,0) [0|0] "" Vector__XXX
 SG_ DAS_TF_furnitureIndex1 m1 : 5|8@1+ (1,0) [0|0] "" Vector__XXX
 SG_ DAS_TF_longitudinalDist m1 : 13|12@1+ (0.1,0) [0|0] "m" Vector__XXX
 SG_ DAS_TF_lateralDist m1 : 25|12@1+ (0.1,-204.8) [0|0] "m" Vector__XXX
 SG_ DAS_TF_height m1 : 37|12@1+ (0.05,0) [0|0] "m" Vector__XXX
 SG_ DAS_TF_color m1 : 49|3@1+ (1,0) [0|0] "" Vector__XXX
 SG_ DAS_TF_shape m1 : 52|3@1+ (1,0) [0|0] "" Vector__XXX
 SG_ DAS_TF_orientation m1 : 55|2@1+ (1,0) [0|0] "" Vector__XXX
 SG_ DAS_TF_transmissionStatus m1 : 57|2@1+ (1,0) [0|0] "" Vector__XXX
 SG_ DAS_TF_isMain m1 : 59|1@1+ (1,0) [0|0] "" Vector__XXX
 SG_ DAS_TF_isTeslaMain m1 : 60|1@1+ (1,0) [0|0] "" Vector__XXX
 SG_ DAS_TF_furnitureIndex2 m2 : 5|8@1+ (1,0) [0|0] "" Vector__XXX
 SG_ DAS_TF_juncStatus m2 : 13|4@1+ (1,0) [0|0] "" Vector__XXX
 SG_ DAS_TF_juncDist m2 : 17|11@1+ (0.2,-20) [0|0] "m" Vector__XXX
 SG_ DAS_TF_stopLineDist m2 : 28|11@1+ (0.1,-10) [0|0] "m" Vector__XXX
 SG_ DAS_TF_ttc m2 : 39|7@1+ (0.1,0) [0|0] "s" Vector__XXX

BO_ 947 UI_vehicleControl2: 4 VEH
 SG_ UI_PINToDriveEnabled : 6|1@1+ (1,0) [0|1] "" Vector__XXX
 SG_ UI_PINToDrivePassed : 7|1@1+ (1,0) [0|1] "" Vector__XXX
 SG_ UI_UMCUpdateInhibit : 2|1@1+ (1,0) [0|1] "" Vector__XXX
 SG_ UI_VCLEFTFeature1 : 15|1@1+ (1,0) [0|1] "" Vector__XXX
 SG_ UI_VCSECFeature1 : 14|1@1+ (1,0) [0|1] "" Vector__XXX
 SG_ UI_WCUpdateInhibit : 3|1@1+ (1,0) [0|1] "" Vector__XXX
 SG_ UI_alarmTriggerRequest : 13|1@1+ (1,0) [0|1] "" Vector__XXX
 SG_ UI_autoRollWindowsOnLockEnable : 29|1@1+ (1,0) [0|1] "" Vector__XXX
 SG_ UI_autopilotPowerStateRequest : 25|2@1+ (1,0) [0|2] "" Vector__XXX
 SG_ UI_batteryPreconditioningRequest : 23|1@1+ (1,0) [0|1] "" Vector__XXX
 SG_ UI_coastDownMode : 24|1@1+ (1,0) [0|1] "" Vector__XXX
 SG_ UI_efuseMXResistanceEstArmed : 30|1@1+ (1,0) [0|1] "" Vector__XXX
 SG_ UI_freeRollModeRequest : 19|1@1+ (1,0) [0|1] "" Vector__XXX
 SG_ UI_gloveboxRequest : 0|1@1+ (1,0) [0|1] "" Vector__XXX
 SG_ UI_lightSwitch : 9|3@1+ (1,0) [0|4] "" Vector__XXX
 SG_ UI_locksPanelActive : 5|1@1+ (1,0) [0|1] "" Vector__XXX
 SG_ UI_readyToAddKey : 12|1@1+ (1,0) [0|1] "" Vector__XXX
 SG_ UI_shorted12VCellTestMode : 27|2@1+ (1,0) [0|2] "" Vector__XXX
 SG_ UI_soundHornOnLock : 4|1@1+ (1,0) [0|1] "" Vector__XXX
 SG_ UI_summonState : 16|2@1+ (1,0) [0|3] "" Vector__XXX
 SG_ UI_trunkRequest : 1|1@1+ (1,0) [0|1] "" Vector__XXX
 SG_ UI_userPresent : 18|1@1+ (1,0) [0|1] "" Vector__XXX
 SG_ UI_windowRequest : 20|3@1+ (1,0) [0|4] "" Vector__XXX

BO_ 949 DIS_alertMatrix2: 8 VEH
 SG_ DIS_a065_canHardwareBusB : 0|1@1+ (1,0) [0|0] "" Vector__XXX
 SG_ DIS_a066_canDataBusB : 1|1@1+ (1,0) [0|0] "" Vector__XXX
 SG_ DIS_a067_canOverrunBusB : 2|1@1+ (1,0) [0|0] "" Vector__XXX
 SG_ DIS_a070_12vSupplySensor : 5|1@1+ (1,0) [0|0] "" Vector__XXX
 SG_ DIS_a071_busDisconnected : 6|1@1+ (1,0) [0|0] "" Vector__XXX
 SG_ DIS_a072_gateDriveFaultCounter : 7|1@1+ (1,0) [0|0] "" Vector__XXX
 SG_ DIS_a073_motorSpeed : 8|1@1+ (1,0) [0|0] "" Vector__XXX
 SG_ DIS_a074_motorEncoder : 9|1@1+ (1,0) [0|0] "" Vector__XXX
 SG_ DIS_a075_motorSpeedMismatch : 10|1@1+ (1,0) [0|0] "" Vector__XXX
 SG_ DIS_a076_12vSupplyOV : 11|1@1+ (1,0) [0|0] "" Vector__XXX
 SG_ DIS_a077_12vSupplyUV : 12|1@1+ (1,0) [0|0] "" Vector__XXX
 SG_ DIS_a078_adcRefLow : 13|1@1+ (1,0) [0|0] "" Vector__XXX
 SG_ DIS_a079_adcRefHigh : 14|1@1+ (1,0) [0|0] "" Vector__XXX
 SG_ DIS_a086_hvilNotPresent : 21|1@1+ (1,0) [0|0] "" Vector__XXX
 SG_ DIS_a087_gtwMIA : 22|1@1+ (1,0) [0|0] "" Vector__XXX
 SG_ DIS_a088_uiMIA : 23|1@1+ (1,0) [0|0] "" Vector__XXX
 SG_ DIS_a090_pmMIA : 25|1@1+ (1,0) [0|0] "" Vector__XXX
 SG_ DIS_a091_espMIA : 26|1@1+ (1,0) [0|0] "" Vector__XXX
 SG_ DIS_a092_bmsMIA : 27|1@1+ (1,0) [0|0] "" Vector__XXX
 SG_ DIS_a093_canHardwareBusA : 28|1@1+ (1,0) [0|0] "" Vector__XXX
 SG_ DIS_a094_canDataBusA : 29|1@1+ (1,0) [0|0] "" Vector__XXX
 SG_ DIS_a095_canOverrunBusA : 30|1@1+ (1,0) [0|0] "" Vector__XXX
 SG_ DIS_a096_memoryError : 31|1@1+ (1,0) [0|0] "" Vector__XXX
 SG_ DIS_a097_eepromError : 32|1@1+ (1,0) [0|0] "" Vector__XXX
 SG_ DIS_a098_intTimeTooLong : 33|1@1+ (1,0) [0|0] "" Vector__XXX
 SG_ DIS_a099_threadOverrun : 34|1@1+ (1,0) [0|0] "" Vector__XXX
 SG_ DIS_a100_assertion : 35|1@1+ (1,0) [0|0] "" Vector__XXX
 SG_ DIS_a103_lowFlow : 38|1@1+ (1,0) [0|0] "" Vector__XXX
 SG_ DIS_a106_absMIA : 41|1@1+ (1,0) [0|0] "" Vector__XXX
 SG_ DIS_a108_stateTrans : 43|1@1+ (1,0) [0|0] "" Vector__XXX
 SG_ DIS_a110_brakeMIA : 45|1@1+ (1,0) [0|0] "" Vector__XXX
 SG_ DIS_a112_noPhaseCurrent : 47|1@1+ (1,0) [0|0] "" Vector__XXX
 SG_ DIS_a113_noFuncHeatsinkSensor : 48|1@1+ (1,0) [0|0] "" Vector__XXX
 SG_ DIS_a114_noMotorSpeed : 49|1@1+ (1,0) [0|0] "" Vector__XXX
 SG_ DIS_a115_heatsinkTempImbalance : 50|1@1+ (1,0) [0|0] "" Vector__XXX
 SG_ DIS_a116_powerConvIrrational : 51|1@1+ (1,0) [0|0] "" Vector__XXX
 SG_ DIS_a117_diMIA : 52|1@1+ (1,0) [0|0] "" Vector__XXX
 SG_ DIS_a121_motorControlRegulation : 56|1@1+ (1,0) [0|0] "" Vector__XXX
 SG_ DIS_a122_highStackUsage : 57|1@1+ (1,0) [0|0] "" Vector__XXX
 SG_ DIS_a123_lossMotorControl : 58|1@1+ (1,0) [0|0] "" Vector__XXX
 SG_ DIS_a126_limpMode : 61|1@1+ (1,0) [0|0] "" Vector__XXX
 SG_ DIS_a127_gracefulPowerOff : 62|1@1+ (1,0) [0|0] "" Vector__XXX

BO_ 950 DI_odometerStatus: 4 VEH
 SG_ DI_odometer : 0|32@1+ (0.001,0) [0|0] "km" Vector__XXX

BO_ 952 UI_tpmsRCPsetting: 8 CH
 SG_ UI_setRCPFront : 16|8@1+ (0.025,0) [0|0] "bar" Vector__XXX
 SG_ UI_setRCPRear : 24|8@1+ (0.025,0) [0|0] "bar" Vector__XXX

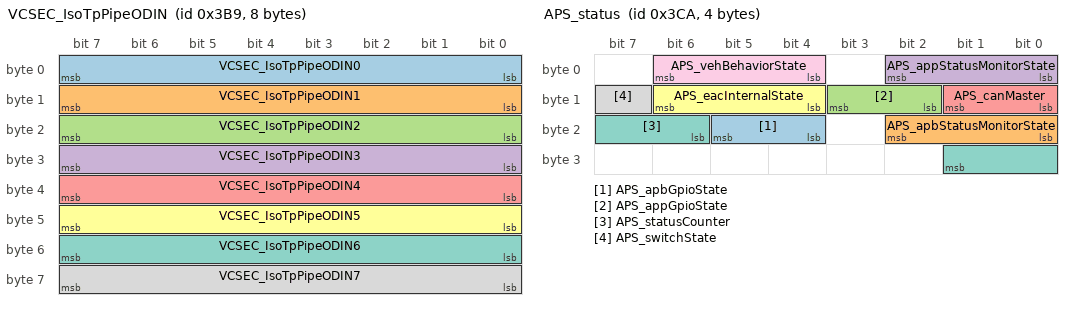
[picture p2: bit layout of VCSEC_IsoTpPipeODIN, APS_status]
BO_ 953 VCSEC_IsoTpPipeODIN: 8 VEH
 SG_ VCSEC_IsoTpPipeODIN0 : 0|8@1+ (1,0) [0|0] "" Vector__XXX
 SG_ VCSEC_IsoTpPipeODIN1 : 8|8@1+ (1,0) [0|0] "" Vector__XXX
 SG_ VCSEC_IsoTpPipeODIN2 : 16|8@1+ (1,0) [0|0] "" Vector__XXX
 SG_ VCSEC_IsoTpPipeODIN3 : 24|8@1+ (1,0) [0|0] "" Vector__XXX
 SG_ VCSEC_IsoTpPipeODIN4 : 32|8@1+ (1,0) [0|0] "" Vector__XXX
 SG_ VCSEC_IsoTpPipeODIN5 : 40|8@1+ (1,0) [0|0] "" Vector__XXX
 SG_ VCSEC_IsoTpPipeODIN6 : 48|8@1+ (1,0) [0|0] "" Vector__XXX
 SG_ VCSEC_IsoTpPipeODIN7 : 56|8@1+ (1,0) [0|0] "" Vector__XXX

BO_ 955 ID3BBUI_power: 2 VehicleBus
 SG_ UI_powerExpected : 0|8@1+ (1,0) [0|100] "kW"   X
 SG_ UI_powerIdeal : 8|8@1+ (1,0) [0|100] "kW"   X

BO_ 958 FC_alertMatrix5: 8 VEH
 SG_ FC_a257_GB_bmsMia : 0|1@1+ (1,0) [0|0] "" Vector__XXX
 SG_ FC_a258_GB_evseMia : 1|1@1+ (1,0) [0|0] "" Vector__XXX
 SG_ FC_a259_GB_vehTxBufOvf : 2|1@1+ (1,0) [0|0] "" Vector__XXX
 SG_ FC_a260_GB_vehRxBufOvf : 3|1@1+ (1,0) [0|0] "" Vector__XXX
 SG_ FC_a261_GB_evseTxBufOvf : 4|1@1+ (1,0) [0|0] "" Vector__XXX
 SG_ FC_a262_GB_evseRxBufOvf : 5|1@1+ (1,0) [0|0] "" Vector__XXX
 SG_ FC_a263_GB_hwProxTrip : 6|1@1+ (1,0) [0|0] "" Vector__XXX
 SG_ FC_a264_GB_ss2NotLow : 7|1@1+ (1,0) [0|0] "" Vector__XXX
 SG_ FC_a265_GB_bmsIncompatible : 8|1@1+ (1,0) [0|0] "" Vector__XXX
 SG_ FC_a266_GB_negPin_OT : 9|1@1+ (1,0) [0|0] "" Vector__XXX
 SG_ FC_a267_GB_posPin_OT : 10|1@1+ (1,0) [0|0] "" Vector__XXX
 SG_ FC_a268_GB_pcb_OT : 11|1@1+ (1,0) [0|0] "" Vector__XXX
 SG_ FC_a269_GB_unused : 12|1@1+ (1,0) [0|0] "" Vector__XXX
 SG_ FC_a270_GB_unused : 13|1@1+ (1,0) [0|0] "" Vector__XXX
 SG_ FC_a271_GB_unused : 14|1@1+ (1,0) [0|0] "" Vector__XXX
 SG_ FC_a272_GB_negToPosDeltaHi : 15|1@1+ (1,0) [0|0] "" Vector__XXX
 SG_ FC_a273_GB_negToPosDeltaLo : 16|1@1+ (1,0) [0|0] "" Vector__XXX
 SG_ FC_a274_GB_negToPcbDeltaHi : 17|1@1+ (1,0) [0|0] "" Vector__XXX
 SG_ FC_a275_GB_posToPcbDeltaHi : 18|1@1+ (1,0) [0|0] "" Vector__XXX
 SG_ FC_a276_GB_negToPcbDeltaLo : 19|1@1+ (1,0) [0|0] "" Vector__XXX
 SG_ FC_a277_GB_posToPcbDeltaLo : 20|1@1+ (1,0) [0|0] "" Vector__XXX
 SG_ FC_a278_GB_unused : 21|1@1+ (1,0) [0|0] "" Vector__XXX
 SG_ FC_a279_GB_evseOverCurrent : 22|1@1+ (1,0) [0|0] "" Vector__XXX
 SG_ FC_a280_GB_unused : 23|1@1+ (1,0) [0|0] "" Vector__XXX
 SG_ FC_a281_GB_ss2Deasserted : 24|1@1+ (1,0) [0|0] "" Vector__XXX
 SG_ FC_a282_GB_negTempHiFoldBk : 25|1@1+ (1,0) [0|0] "" Vector__XXX
 SG_ FC_a283_GB_posTempHiFoldBk : 26|1@1+ (1,0) [0|0] "" Vector__XXX
 SG_ FC_a284_GB_pcbTempHiFoldBk : 27|1@1+ (1,0) [0|0] "" Vector__XXX
 SG_ FC_a285_GB_proxDisconnected : 28|1@1+ (1,0) [0|0] "" Vector__XXX
 SG_ FC_a286_GB_evseConnUnlocked : 29|1@1+ (1,0) [0|0] "" Vector__XXX
 SG_ FC_a287_GB_vehConnUnlocked : 30|1@1+ (1,0) [0|0] "" Vector__XXX
 SG_ FC_a288_GB_isoVoltageLow : 31|1@1+ (1,0) [0|0] "" Vector__XXX
 SG_ FC_a289_GB_proxTimeout : 32|1@1+ (1,0) [0|0] "" Vector__XXX
 SG_ FC_a290_GB_pilotAcceptTimeout : 33|1@1+ (1,0) [0|0] "" Vector__XXX
 SG_ FC_a291_GB_vehDataTimeout : 34|1@1+ (1,0) [0|0] "" Vector__XXX
 SG_ FC_a292_GB_vehConLockTimeout : 35|1@1+ (1,0) [0|0] "" Vector__XXX
 SG_ FC_a293_GB_ss2LowTimeout : 36|1@1+ (1,0) [0|0] "" Vector__XXX
 SG_ FC_a294_GB_evseDataTimeout : 37|1@1+ (1,0) [0|0] "" Vector__XXX
 SG_ FC_a295_GB_vehReadyTimeout : 38|1@1+ (1,0) [0|0] "" Vector__XXX
 SG_ FC_a296_GB_evseIsoTestTimeout : 39|1@1+ (1,0) [0|0] "" Vector__XXX
 SG_ FC_a297_GB_chargingBusTimeout : 40|1@1+ (1,0) [0|0] "" Vector__XXX
 SG_ FC_a298_GB_bmsCtrCloseTimeout : 41|1@1+ (1,0) [0|0] "" Vector__XXX
 SG_ FC_a299_GB_evseReadyTimeout : 42|1@1+ (1,0) [0|0] "" Vector__XXX
 SG_ FC_a300_GB_startupProblem : 43|1@1+ (1,0) [0|0] "" Vector__XXX
 SG_ FC_a301_GB_chargingProblem : 44|1@1+ (1,0) [0|0] "" Vector__XXX
 SG_ FC_a302_GB_vRegBrownout : 45|1@1+ (1,0) [0|0] "" Vector__XXX
 SG_ FC_a303_GB_negRecogTimeout : 46|1@1+ (1,0) [0|0] "" Vector__XXX
 SG_ FC_a304_GB_evseIncompatible : 47|1@1+ (1,0) [0|0] "" Vector__XXX
 SG_ FC_a305_GB_posRecogTimeout : 48|1@1+ (1,0) [0|0] "" Vector__XXX
 SG_ FC_a306_GB_vehReadyDeasserted : 49|1@1+ (1,0) [0|0] "" Vector__XXX
 SG_ FC_a307_GB_fcContOpenTimeout : 50|1@1+ (1,0) [0|0] "" Vector__XXX
 SG_ FC_a308_GB_evseConLockTimeout : 51|1@1+ (1,0) [0|0] "" Vector__XXX
 SG_ FC_a309_GB_unused : 52|1@1+ (1,0) [0|0] "" Vector__XXX
 SG_ FC_a310_GB_vehicleIdTimeout : 53|1@1+ (1,0) [0|0] "" Vector__XXX
 SG_ FC_a311_GB_battParamsTimeout : 54|1@1+ (1,0) [0|0] "" Vector__XXX
 SG_ FC_a312_GB_evseLimitsTimeout : 55|1@1+ (1,0) [0|0] "" Vector__XXX

BO_ 960 VCRIGHT_alertMatrix: 8 VEH
 SG_ VCRIGHT_matrixIndex M : 0|4@1+ (1,0) [0|0] "" Vector__XXX
 SG_ VCRIGHT_a001_WatchdogReset m0 : 4|1@1+ (1,0) [0|0] "" Vector__XXX
 SG_ VCRIGHT_a002_PowerLossReset m0 : 5|1@1+ (1,0) [0|0] "" Vector__XXX
 SG_ VCRIGHT_a003_SWAssertion m0 : 6|1@1+ (1,0) [0|0] "" Vector__XXX
 SG_ VCRIGHT_a010_ExtSupplyVoltError m0 : 13|1@1+ (1,0) [0|0] "" Vector__XXX
 SG_ VCRIGHT_a012_CPUReset m0 : 15|1@1+ (1,0) [0|0] "" Vector__XXX
 SG_ VCRIGHT_a013_AlertManagerFault m0 : 16|1@1+ (1,0) [0|0] "" Vector__XXX
 SG_ VCRIGHT_a015_NVMMAlert m0 : 18|1@1+ (1,0) [0|0] "" Vector__XXX
 SG_ VCRIGHT_a021_TaskSchedulerError m0 : 24|1@1+ (1,0) [0|0] "" Vector__XXX
 SG_ VCRIGHT_a022_TaskInitError m0 : 25|1@1+ (1,0) [0|0] "" Vector__XXX
 SG_ VCRIGHT_a031_UDSActive m0 : 34|1@1+ (1,0) [0|0] "" Vector__XXX
 SG_ VCRIGHT_a041_HighCPULoad m0 : 44|1@1+ (1,0) [0|0] "" Vector__XXX
 SG_ VCRIGHT_a042_HighStackUsage m0 : 45|1@1+ (1,0) [0|0] "" Vector__XXX
 SG_ VCRIGHT_a043_Task1msError m0 : 46|1@1+ (1,0) [0|0] "" Vector__XXX
 SG_ VCRIGHT_a044_Task10msError m0 : 47|1@1+ (1,0) [0|0] "" Vector__XXX
 SG_ VCRIGHT_a045_Task100msError m0 : 48|1@1+ (1,0) [0|0] "" Vector__XXX
 SG_ VCRIGHT_a046_Task1000msError m0 : 49|1@1+ (1,0) [0|0] "" Vector__XXX
 SG_ VCRIGHT_a059_inputResistanceHigh m0 : 62|1@1+ (1,0) [0|0] "" Vector__XXX
 SG_ VCRIGHT_a060_engineeringBuild m0 : 63|1@1+ (1,0) [0|0] "" Vector__XXX
 SG_ VCRIGHT_a061_XCPConnected m1 : 4|1@1+ (1,0) [0|0] "" Vector__XXX
 SG_ VCRIGHT_a062_XCPWasConnected m1 : 5|1@1+ (1,0) [0|0] "" Vector__XXX
 SG_ VCRIGHT_a063_SwitchFault m1 : 6|1@1+ (1,0) [0|0] "" Vector__XXX
 SG_ VCRIGHT_a064_busSleepReqTimeout m1 : 7|1@1+ (1,0) [0|0] "" Vector__XXX
 SG_ VCRIGHT_a097_CMP_MIA m1 : 40|1@1+ (1,0) [0|0] "" Vector__XXX
 SG_ VCRIGHT_a098_DI_THERMAL_MIA m1 : 41|1@1+ (1,0) [0|0] "" Vector__XXX
 SG_ VCRIGHT_a099_PARK_MIA m1 : 42|1@1+ (1,0) [0|0] "" Vector__XXX
 SG_ VCRIGHT_a100_CANbus_MIA m1 : 43|1@1+ (1,0) [0|0] "" Vector__XXX
 SG_ VCRIGHT_a101_PM_MIA m1 : 44|1@1+ (1,0) [0|0] "" Vector__XXX
 SG_ VCRIGHT_a102_PTC_MIA m1 : 45|1@1+ (1,0) [0|0] "" Vector__XXX
 SG_ VCRIGHT_a103_CP_MIA m1 : 46|1@1+ (1,0) [0|0] "" Vector__XXX
 SG_ VCRIGHT_a104_DAS_MIA m1 : 47|1@1+ (1,0) [0|0] "" Vector__XXX
 SG_ VCRIGHT_a105_TAS_MIA m1 : 48|1@1+ (1,0) [0|0] "" Vector__XXX
 SG_ VCRIGHT_a106_PCS_MIA m1 : 49|1@1+ (1,0) [0|0] "" Vector__XXX
 SG_ VCRIGHT_a107_BMS_MIA m1 : 50|1@1+ (1,0) [0|0] "" Vector__XXX
 SG_ VCRIGHT_a108_DIS_MIA m1 : 51|1@1+ (1,0) [0|0] "" Vector__XXX
 SG_ VCRIGHT_a109_RCM_MIA m1 : 52|1@1+ (1,0) [0|0] "" Vector__XXX
 SG_ VCRIGHT_a110_GTW_MIA m1 : 53|1@1+ (1,0) [0|0] "" Vector__XXX
 SG_ VCRIGHT_a111_EPBR_MIA m1 : 54|1@1+ (1,0) [0|0] "" Vector__XXX
 SG_ VCRIGHT_a112_EPBL_MIA m1 : 55|1@1+ (1,0) [0|0] "" Vector__XXX
 SG_ VCRIGHT_a113_UI_MIA m1 : 56|1@1+ (1,0) [0|0] "" Vector__XXX
 SG_ VCRIGHT_a114_ESP_MIA m1 : 57|1@1+ (1,0) [0|0] "" Vector__XXX
 SG_ VCRIGHT_a115_VCSEC_MIA m1 : 58|1@1+ (1,0) [0|0] "" Vector__XXX
 SG_ VCRIGHT_a116_VCRIGHT_MIA m1 : 59|1@1+ (1,0) [0|0] "" Vector__XXX
 SG_ VCRIGHT_a117_VCLEFT_MIA m1 : 60|1@1+ (1,0) [0|0] "" Vector__XXX
 SG_ VCRIGHT_a118_VCFRONT_MIA m1 : 61|1@1+ (1,0) [0|0] "" Vector__XXX
 SG_ VCRIGHT_a119_SCCM_MIA m1 : 62|1@1+ (1,0) [0|0] "" Vector__XXX
 SG_ VCRIGHT_a120_DI_DRIVE_MIA m1 : 63|1@1+ (1,0) [0|0] "" Vector__XXX
 SG_ VCRIGHT_a129_hvacIntakeUncalib m2 : 12|1@1+ (1,0) [0|0] "" Vector__XXX
 SG_ VCRIGHT_a130_hvacLHBleedUncalib m2 : 13|1@1+ (1,0) [0|0] "" Vector__XXX
 SG_ VCRIGHT_a131_hvacRHBleedUncalib m2 : 14|1@1+ (1,0) [0|0] "" Vector__XXX
 SG_ VCRIGHT_a132_hvacLHVaneUncalib m2 : 15|1@1+ (1,0) [0|0] "" Vector__XXX
 SG_ VCRIGHT_a133_hvacRHVaneUncalib m2 : 16|1@1+ (1,0) [0|0] "" Vector__XXX
 SG_ VCRIGHT_a134_hvacUpprModeUncalib m2 : 17|1@1+ (1,0) [0|0] "" Vector__XXX
 SG_ VCRIGHT_a135_hvacLowrModeUncalib m2 : 18|1@1+ (1,0) [0|0] "" Vector__XXX
 SG_ VCRIGHT_a136_hvacIntakeFault m2 : 19|1@1+ (1,0) [0|0] "" Vector__XXX
 SG_ VCRIGHT_a137_hvacLHBleedFault m2 : 20|1@1+ (1,0) [0|0] "" Vector__XXX
 SG_ VCRIGHT_a138_hvacRHBleedFault m2 : 21|1@1+ (1,0) [0|0] "" Vector__XXX
 SG_ VCRIGHT_a139_hvacLHVaneFault m2 : 22|1@1+ (1,0) [0|0] "" Vector__XXX
 SG_ VCRIGHT_a140_hvacRHVaneFault m2 : 23|1@1+ (1,0) [0|0] "" Vector__XXX
 SG_ VCRIGHT_a141_hvacUpperModeFault m2 : 24|1@1+ (1,0) [0|0] "" Vector__XXX
 SG_ VCRIGHT_a142_hvacLowerModeFault m2 : 25|1@1+ (1,0) [0|0] "" Vector__XXX
 SG_ VCRIGHT_a144_evaporatorTempSns m2 : 27|1@1+ (1,0) [0|0] "" Vector__XXX
 SG_ VCRIGHT_a145_ductLeftTempSns m2 : 28|1@1+ (1,0) [0|0] "" Vector__XXX
 SG_ VCRIGHT_a146_ductRightTempSns m2 : 29|1@1+ (1,0) [0|0] "" Vector__XXX
 SG_ VCRIGHT_a147_incarProbeTempSns m2 : 30|1@1+ (1,0) [0|0] "" Vector__XXX
 SG_ VCRIGHT_a148_incarMidTempSns m2 : 31|1@1+ (1,0) [0|0] "" Vector__XXX
 SG_ VCRIGHT_a149_incarDeepTempSns m2 : 32|1@1+ (1,0) [0|0] "" Vector__XXX
 SG_ VCRIGHT_a150_windowPinchFront m2 : 33|1@1+ (1,0) [0|0] "" Vector__XXX
 SG_ VCRIGHT_a151_windowPinchRear m2 : 34|1@1+ (1,0) [0|0] "" Vector__XXX
 SG_ VCRIGHT_a152_windowUncalFront m2 : 35|1@1+ (1,0) [0|0] "" Vector__XXX
 SG_ VCRIGHT_a153_windowUncalRear m2 : 36|1@1+ (1,0) [0|0] "" Vector__XXX
 SG_ VCRIGHT_a154_windowThermalFront m2 : 37|1@1+ (1,0) [0|0] "" Vector__XXX
 SG_ VCRIGHT_a155_windowThermalRear m2 : 38|1@1+ (1,0) [0|0] "" Vector__XXX
 SG_ VCRIGHT_a156_windowNoInputFront m2 : 39|1@1+ (1,0) [0|0] "" Vector__XXX
 SG_ VCRIGHT_a157_windowNoInputRear m2 : 40|1@1+ (1,0) [0|0] "" Vector__XXX
 SG_ VCRIGHT_a158_windowPinchOverideF m2 : 41|1@1+ (1,0) [0|0] "" Vector__XXX
 SG_ VCRIGHT_a159_windowPinchOverideR m2 : 42|1@1+ (1,0) [0|0] "" Vector__XXX
 SG_ VCRIGHT_a160_windowUndercurrentF m2 : 43|1@1+ (1,0) [0|0] "" Vector__XXX
 SG_ VCRIGHT_a161_windowUndercurrentR m2 : 44|1@1+ (1,0) [0|0] "" Vector__XXX
 SG_ VCRIGHT_a162_windowEncoderStallF m2 : 45|1@1+ (1,0) [0|0] "" Vector__XXX
 SG_ VCRIGHT_a163_windowEncoderStallR m2 : 46|1@1+ (1,0) [0|0] "" Vector__XXX
 SG_ VCRIGHT_a164_windowFactoryTest m2 : 47|1@1+ (1,0) [0|0] "" Vector__XXX
 SG_ VCRIGHT_a165_windowFactoryTest2 m2 : 48|1@1+ (1,0) [0|0] "" Vector__XXX
 SG_ VCRIGHT_a166_windowDebug m2 : 49|1@1+ (1,0) [0|0] "" Vector__XXX
 SG_ VCRIGHT_a167_windowDebugPinchF m2 : 50|1@1+ (1,0) [0|0] "" Vector__XXX
 SG_ VCRIGHT_a168_windowDebugPinchR m2 : 51|1@1+ (1,0) [0|0] "" Vector__XXX
 SG_ VCRIGHT_a169_windowCurrentPeakF m2 : 52|1@1+ (1,0) [0|0] "" Vector__XXX
 SG_ VCRIGHT_a170_windowCurrentPeakR m2 : 53|1@1+ (1,0) [0|0] "" Vector__XXX
 SG_ VCRIGHT_a172_SPI_MIA m2 : 55|1@1+ (1,0) [0|0] "" Vector__XXX
 SG_ VCRIGHT_a174_BLERightPowerCycled m2 : 57|1@1+ (1,0) [0|0] "" Vector__XXX
 SG_ VCRIGHT_a180_frontDoorLatchRehome m2 : 63|1@1+ (1,0) [0|0] "" Vector__XXX
 SG_ VCRIGHT_a181_rearDoorLatchRehome m3 : 4|1@1+ (1,0) [0|0] "" Vector__XXX
 SG_ VCRIGHT_a182_emergencyLatchRel m3 : 5|1@1+ (1,0) [0|0] "" Vector__XXX
 SG_ VCRIGHT_a183_doorStateFactoryTest m3 : 6|1@1+ (1,0) [0|0] "" Vector__XXX
 SG_ VCRIGHT_a184_trunkFailedOpening m3 : 7|1@1+ (1,0) [0|0] "" Vector__XXX
 SG_ VCRIGHT_a185_summonAborted m3 : 8|1@1+ (1,0) [0|0] "" Vector__XXX
 SG_ VCRIGHT_a186_latchReleaseFailedF m3 : 9|1@1+ (1,0) [0|0] "" Vector__XXX
 SG_ VCRIGHT_a187_latchReleaseFailedR m3 : 10|1@1+ (1,0) [0|0] "" Vector__XXX
 SG_ VCRIGHT_a188_latchUnableToRearmF m3 : 11|1@1+ (1,0) [0|0] "" Vector__XXX
 SG_ VCRIGHT_a189_latchUnableToRearmR m3 : 12|1@1+ (1,0) [0|0] "" Vector__XXX
 SG_ VCRIGHT_a190_eFuseMgmtVbatFused m3 : 13|1@1+ (1,0) [0|0] "" Vector__XXX
 SG_ VCRIGHT_a191_gloveboxPower m3 : 14|1@1+ (1,0) [0|0] "" Vector__XXX
 SG_ VCRIGHT_a192_gloveboxLatchRel m3 : 15|1@1+ (1,0) [0|0] "" Vector__XXX
 SG_ VCRIGHT_a193_amplifierEFuseFault m3 : 16|1@1+ (1,0) [0|0] "" Vector__XXX
 SG_ VCRIGHT_a194_cntctrPwrEFuseFault m3 : 17|1@1+ (1,0) [0|0] "" Vector__XXX
 SG_ VCRIGHT_a195_hvcEFuseFault m3 : 18|1@1+ (1,0) [0|0] "" Vector__XXX
 SG_ VCRIGHT_a196_VEHCANOverterminate m3 : 19|1@1+ (1,0) [0|0] "" Vector__XXX
 SG_ VCRIGHT_a197_VEHCANUndertrminate m3 : 20|1@1+ (1,0) [0|0] "" Vector__XXX
 SG_ VCRIGHT_a198_PRVCANOverterminate m3 : 21|1@1+ (1,0) [0|0] "" Vector__XXX
 SG_ VCRIGHT_a199_PRVCANUndertrminate m3 : 22|1@1+ (1,0) [0|0] "" Vector__XXX
 SG_ VCRIGHT_a200_motorPhantomEncoder m3 : 23|1@1+ (1,0) [0|0] "" Vector__XXX
 SG_ VCRIGHT_a201_motorDutyEncDisabl m3 : 24|1@1+ (1,0) [0|0] "" Vector__XXX
 SG_ VCRIGHT_a202_epbmUnderIStatic m3 : 25|1@1+ (1,0) [0|0] "" Vector__XXX
 SG_ VCRIGHT_a203_epbmOverIStatic m3 : 26|1@1+ (1,0) [0|0] "" Vector__XXX
 SG_ VCRIGHT_a204_epbmUnderIDyn m3 : 27|1@1+ (1,0) [0|0] "" Vector__XXX
 SG_ VCRIGHT_a205_epbmOverIDyn m3 : 28|1@1+ (1,0) [0|0] "" Vector__XXX
 SG_ VCRIGHT_a206_epbWrongDirection m3 : 29|1@1+ (1,0) [0|0] "" Vector__XXX
 SG_ VCRIGHT_a207_epbmEnableWrong m3 : 30|1@1+ (1,0) [0|0] "" Vector__XXX
 SG_ VCRIGHT_a208_epbFaulted m3 : 31|1@1+ (1,0) [0|0] "" Vector__XXX
 SG_ VCRIGHT_a209_epbStateMisTime m3 : 32|1@1+ (1,0) [0|0] "" Vector__XXX
 SG_ VCRIGHT_a210_epbStateTime m3 : 33|1@1+ (1,0) [0|0] "" Vector__XXX
 SG_ VCRIGHT_a211_epbmUnderIStaticNew m3 : 34|1@1+ (1,0) [0|0] "" Vector__XXX
 SG_ VCRIGHT_a212_epbmOverIStaticNew m3 : 35|1@1+ (1,0) [0|0] "" Vector__XXX
 SG_ VCRIGHT_a213_epbmUnderIDynNew m3 : 36|1@1+ (1,0) [0|0] "" Vector__XXX
 SG_ VCRIGHT_a214_epbmOverIDynNew m3 : 37|1@1+ (1,0) [0|0] "" Vector__XXX
 SG_ VCRIGHT_a215_currentDesyncWarning m3 : 38|1@1+ (1,0) [0|0] "" Vector__XXX
 SG_ VCRIGHT_a216_SPI_MIA_debugData1 m3 : 39|1@1+ (1,0) [0|0] "" Vector__XXX
 SG_ VCRIGHT_a217_SPI_MIA_debugData2 m3 : 40|1@1+ (1,0) [0|0] "" Vector__XXX
 SG_ VCRIGHT_a218_motorDriverFault m3 : 41|1@1+ (1,0) [0|0] "" Vector__XXX
 SG_ VCRIGHT_a219_motorCurrentDropout m3 : 42|1@1+ (1,0) [0|0] "" Vector__XXX
 SG_ VCRIGHT_a220_seatCurrStallTrack m3 : 43|1@1+ (1,0) [0|0] "" Vector__XXX
 SG_ VCRIGHT_a221_seatCurrStallBack m3 : 44|1@1+ (1,0) [0|0] "" Vector__XXX
 SG_ VCRIGHT_a222_seatCurrStallTilt m3 : 45|1@1+ (1,0) [0|0] "" Vector__XXX
 SG_ VCRIGHT_a223_seatCurrStallLift m3 : 46|1@1+ (1,0) [0|0] "" Vector__XXX
 SG_ VCRIGHT_a224_seatEncStallTrack m3 : 47|1@1+ (1,0) [0|0] "" Vector__XXX
 SG_ VCRIGHT_a225_seatEncStallBack m3 : 48|1@1+ (1,0) [0|0] "" Vector__XXX
 SG_ VCRIGHT_a226_seatEncStallTilt m3 : 49|1@1+ (1,0) [0|0] "" Vector__XXX
 SG_ VCRIGHT_a227_seatEncStallLift m3 : 50|1@1+ (1,0) [0|0] "" Vector__XXX
 SG_ VCRIGHT_a228_seatEncOverTrack m3 : 51|1@1+ (1,0) [0|0] "" Vector__XXX
 SG_ VCRIGHT_a229_seatEncOverBack m3 : 52|1@1+ (1,0) [0|0] "" Vector__XXX
 SG_ VCRIGHT_a230_seatEncOverTilt m3 : 53|1@1+ (1,0) [0|0] "" Vector__XXX
 SG_ VCRIGHT_a231_seatEncOverLift m3 : 54|1@1+ (1,0) [0|0] "" Vector__XXX
 SG_ VCRIGHT_a232_seatCurrUnderTrack m3 : 55|1@1+ (1,0) [0|0] "" Vector__XXX
 SG_ VCRIGHT_a233_seatCurrUnderBack m3 : 56|1@1+ (1,0) [0|0] "" Vector__XXX
 SG_ VCRIGHT_a234_seatCurrUnderTilt m3 : 57|1@1+ (1,0) [0|0] "" Vector__XXX
 SG_ VCRIGHT_a235_seatCurrUnderLift m3 : 58|1@1+ (1,0) [0|0] "" Vector__XXX
 SG_ VCRIGHT_a236_lumbarOverPresA m3 : 59|1@1+ (1,0) [0|0] "" Vector__XXX
 SG_ VCRIGHT_a237_lumbarOverPresB m3 : 60|1@1+ (1,0) [0|0] "" Vector__XXX
 SG_ VCRIGHT_a238_lumbarValveMIA m3 : 61|1@1+ (1,0) [0|0] "" Vector__XXX
 SG_ VCRIGHT_a239_seatHeatIFront m3 : 62|1@1+ (1,0) [0|0] "" Vector__XXX
 SG_ VCRIGHT_a240_seatHeatShortFront m3 : 63|1@1+ (1,0) [0|0] "" Vector__XXX
 SG_ VCRIGHT_a241_seatHeatMIAFront m4 : 4|1@1+ (1,0) [0|0] "" Vector__XXX
 SG_ VCRIGHT_a242_seatHeatIRearL m4 : 5|1@1+ (1,0) [0|0] "" Vector__XXX
 SG_ VCRIGHT_a243_seatHeatShortRearL m4 : 6|1@1+ (1,0) [0|0] "" Vector__XXX
 SG_ VCRIGHT_a244_seatHeatMIARearL m4 : 7|1@1+ (1,0) [0|0] "" Vector__XXX
 SG_ VCRIGHT_a245_seatHeatIRearC m4 : 8|1@1+ (1,0) [0|0] "" Vector__XXX
 SG_ VCRIGHT_a246_seatHeatShortRearC m4 : 9|1@1+ (1,0) [0|0] "" Vector__XXX
 SG_ VCRIGHT_a247_seatHeatMIARearC m4 : 10|1@1+ (1,0) [0|0] "" Vector__XXX
 SG_ VCRIGHT_a248_seatHeatIRearR m4 : 11|1@1+ (1,0) [0|0] "" Vector__XXX
 SG_ VCRIGHT_a249_seatHeatShortRearR m4 : 12|1@1+ (1,0) [0|0] "" Vector__XXX
 SG_ VCRIGHT_a250_seatHeatMIARearR m4 : 13|1@1+ (1,0) [0|0] "" Vector__XXX
 SG_ VCRIGHT_a251_seatUncalTrack m4 : 14|1@1+ (1,0) [0|0] "" Vector__XXX
 SG_ VCRIGHT_a252_seatUncalBack m4 : 15|1@1+ (1,0) [0|0] "" Vector__XXX
 SG_ VCRIGHT_a253_seatUncalTilt m4 : 16|1@1+ (1,0) [0|0] "" Vector__XXX
 SG_ VCRIGHT_a254_seatUncalLift m4 : 17|1@1+ (1,0) [0|0] "" Vector__XXX
 SG_ VCRIGHT_a255_PTCOverTemp m4 : 18|1@1+ (1,0) [0|0] "" Vector__XXX
 SG_ VCRIGHT_a256_PTCCurrentDrawNoReq m4 : 19|1@1+ (1,0) [0|0] "" Vector__XXX
 SG_ VCRIGHT_a257_THSMIA m4 : 20|1@1+ (1,0) [0|0] "" Vector__XXX
 SG_ VCRIGHT_a258_PTCStuckInBoot m4 : 21|1@1+ (1,0) [0|0] "" Vector__XXX
 SG_ VCRIGHT_a259_latchDisarmDelayF m4 : 22|1@1+ (1,0) [0|0] "" Vector__XXX
 SG_ VCRIGHT_a260_latchDisarmDelayR m4 : 23|1@1+ (1,0) [0|0] "" Vector__XXX
 SG_ VCRIGHT_a262_PTCFaulted m4 : 25|1@1+ (1,0) [0|0] "" Vector__XXX
 SG_ VCRIGHT_a263_seatTrackStallDebug m4 : 26|1@1+ (1,0) [0|0] "" Vector__XXX
 SG_ VCRIGHT_a264_seatBackStallDebug m4 : 27|1@1+ (1,0) [0|0] "" Vector__XXX
 SG_ VCRIGHT_a265_seatTiltStallDebug m4 : 28|1@1+ (1,0) [0|0] "" Vector__XXX
 SG_ VCRIGHT_a266_seatLiftStallDebug m4 : 29|1@1+ (1,0) [0|0] "" Vector__XXX
 SG_ VCRIGHT_a267_seatTrackHCEncStlDbg m4 : 30|1@1+ (1,0) [0|0] "" Vector__XXX
 SG_ VCRIGHT_a268_seatBackHCEncStlDbg m4 : 31|1@1+ (1,0) [0|0] "" Vector__XXX
 SG_ VCRIGHT_a269_seatTiltHCEncStlDbg m4 : 32|1@1+ (1,0) [0|0] "" Vector__XXX
 SG_ VCRIGHT_a270_seatLiftHCEncStlDbg m4 : 33|1@1+ (1,0) [0|0] "" Vector__XXX
 SG_ VCRIGHT_a271_THSSensorFault m4 : 34|1@1+ (1,0) [0|0] "" Vector__XXX
 SG_ VCRIGHT_a272_vhclPwrStateMsmtch m4 : 35|1@1+ (1,0) [0|0] "" Vector__XXX
 SG_ VCRIGHT_a273_handleStuckActiveF m4 : 36|1@1+ (1,0) [0|0] "" Vector__XXX
 SG_ VCRIGHT_a274_handleStuckActiveR m4 : 37|1@1+ (1,0) [0|0] "" Vector__XXX
 SG_ VCRIGHT_a275_rightTurnLightFault m4 : 38|1@1+ (1,0) [0|0] "" Vector__XXX
 SG_ VCRIGHT_a276_mirrorDebug m4 : 39|1@1+ (1,0) [0|0] "" Vector__XXX
 SG_ VCRIGHT_a277_BLERightUnderVoltage m4 : 40|1@1+ (1,0) [0|0] "" Vector__XXX
 SG_ VCRIGHT_a280_latchDidNotDisarmF m4 : 43|1@1+ (1,0) [0|0] "" Vector__XXX
 SG_ VCRIGHT_a281_latchDidNotDisarmR m4 : 44|1@1+ (1,0) [0|0] "" Vector__XXX
 SG_ VCRIGHT_a282_latchUnexpectedArmF m4 : 45|1@1+ (1,0) [0|0] "" Vector__XXX
 SG_ VCRIGHT_a283_latchUnexpectedArmR m4 : 46|1@1+ (1,0) [0|0] "" Vector__XXX
 SG_ VCRIGHT_a286_windowSpeedInvalidF m4 : 49|1@1+ (1,0) [0|0] "" Vector__XXX
 SG_ VCRIGHT_a287_windowSpeedInvalidR m4 : 50|1@1+ (1,0) [0|0] "" Vector__XXX
 SG_ VCRIGHT_a290_occupancyFaultedFront m4 : 53|1@1+ (1,0) [0|0] "" Vector__XXX
 SG_ VCRIGHT_a291_buckleFaultedFront m4 : 54|1@1+ (1,0) [0|0] "" Vector__XXX
 SG_ VCRIGHT_a292_buckleFaultedRearC m4 : 55|1@1+ (1,0) [0|0] "" Vector__XXX
 SG_ VCRIGHT_a293_buckleFaultedRearR m4 : 56|1@1+ (1,0) [0|0] "" Vector__XXX
 SG_ VCRIGHT_a304_frontIntHandleShorted m5 : 7|1@1+ (1,0) [0|0] "" Vector__XXX
 SG_ VCRIGHT_a305_rearIntHandleShorted m5 : 8|1@1+ (1,0) [0|0] "" Vector__XXX
 SG_ VCRIGHT_a306_handleDisconnectedF m5 : 9|1@1+ (1,0) [0|0] "" Vector__XXX
 SG_ VCRIGHT_a307_handleDisconnectedR m5 : 10|1@1+ (1,0) [0|0] "" Vector__XXX

BO_ 962 VCLEFT_switchStatus: 8 VEH
 SG_ VCLEFT_switchStatusIndex M : 0|2@1+ (1,0) [0|2] "" Vector__XXX
 SG_ VCLEFT_2RowSeatBothFoldFlatSwitc m1 : 40|1@1+ (1,0) [0|1] "" Vector__XXX
 SG_ VCLEFT_2RowSeatCenterSwitch m1 : 37|1@1+ (1,0) [0|1] "" Vector__XXX
 SG_ VCLEFT_2RowSeatLeftFoldFlatSwitc m1 : 38|1@1+ (1,0) [0|1] "" Vector__XXX
 SG_ VCLEFT_2RowSeatReclineSwitch m1 : 36|1@1+ (1,0) [0|1] "" Vector__XXX
 SG_ VCLEFT_2RowSeatRightFoldFlatSwit m1 : 39|1@1+ (1,0) [0|1] "" Vector__XXX
 SG_ VCLEFT_brakePressed m0 : 60|1@1+ (1,0) [0|1] "" Vector__XXX
 SG_ VCLEFT_brakeSwitchPressed m0 : 4|1@1+ (1,0) [0|1] "" Vector__XXX
 SG_ VCLEFT_btnWindowAutoDownLR m1 : 35|1@1+ (1,0) [0|1] "" Vector__XXX
 SG_ VCLEFT_btnWindowAutoUpLR m1 : 33|1@1+ (1,0) [0|1] "" Vector__XXX
 SG_ VCLEFT_btnWindowDownLR m1 : 34|1@1+ (1,0) [0|1] "" Vector__XXX
 SG_ VCLEFT_btnWindowSwPackAutoDownLF m0 : 35|1@1+ (1,0) [0|1] "" Vector__XXX
 SG_ VCLEFT_btnWindowSwPackAutoDownLR m0 : 39|1@1+ (1,0) [0|1] "" Vector__XXX
 SG_ VCLEFT_btnWindowSwPackAutoDownRF m0 : 43|1@1+ (1,0) [0|1] "" Vector__XXX
 SG_ VCLEFT_btnWindowSwPackAutoDownRR m0 : 47|1@1+ (1,0) [0|1] "" Vector__XXX
 SG_ VCLEFT_btnWindowSwPackAutoUpLF m0 : 33|1@1+ (1,0) [0|1] "" Vector__XXX
 SG_ VCLEFT_btnWindowSwPackAutoUpLR m0 : 37|1@1+ (1,0) [0|1] "" Vector__XXX
 SG_ VCLEFT_btnWindowSwPackAutoUpRF m0 : 41|1@1+ (1,0) [0|1] "" Vector__XXX
 SG_ VCLEFT_btnWindowSwPackAutoUpRR m0 : 45|1@1+ (1,0) [0|1] "" Vector__XXX
 SG_ VCLEFT_btnWindowSwPackDownLF m0 : 34|1@1+ (1,0) [0|1] "" Vector__XXX
 SG_ VCLEFT_btnWindowSwPackDownLR m0 : 38|1@1+ (1,0) [0|1] "" Vector__XXX
 SG_ VCLEFT_btnWindowSwPackDownRF m0 : 42|1@1+ (1,0) [0|1] "" Vector__XXX
 SG_ VCLEFT_btnWindowSwPackDownRR m0 : 46|1@1+ (1,0) [0|1] "" Vector__XXX
 SG_ VCLEFT_btnWindowSwPackUpLF m0 : 32|1@1+ (1,0) [0|1] "" Vector__XXX
 SG_ VCLEFT_btnWindowSwPackUpLR m0 : 36|1@1+ (1,0) [0|1] "" Vector__XXX
 SG_ VCLEFT_btnWindowSwPackUpRF m0 : 40|1@1+ (1,0) [0|1] "" Vector__XXX
 SG_ VCLEFT_btnWindowSwPackUpRR m0 : 44|1@1+ (1,0) [0|1] "" Vector__XXX
 SG_ VCLEFT_btnWindowUpLR m1 : 32|1@1+ (1,0) [0|1] "" Vector__XXX
 SG_ VCLEFT_frontBuckleSwitch m0 : 48|2@1+ (1,0) [0|3] "" Vector__XXX
 SG_ VCLEFT_frontOccupancySwitch m0 : 50|2@1+ (1,0) [0|3] "" Vector__XXX
 SG_ VCLEFT_frontSeatBackrestBack m0 : 20|2@1+ (1,0) [0|3] "" Vector__XXX
 SG_ VCLEFT_frontSeatBackrestForward m0 : 22|2@1+ (1,0) [0|3] "" Vector__XXX
 SG_ VCLEFT_frontSeatLiftDown m0 : 16|2@1+ (1,0) [0|3] "" Vector__XXX
 SG_ VCLEFT_frontSeatLiftUp m0 : 18|2@1+ (1,0) [0|3] "" Vector__XXX
 SG_ VCLEFT_frontSeatLumbarDown m0 : 24|2@1+ (1,0) [0|3] "" Vector__XXX
 SG_ VCLEFT_frontSeatLumbarIn m0 : 28|2@1+ (1,0) [0|3] "" Vector__XXX
 SG_ VCLEFT_frontSeatLumbarOut m0 : 30|2@1+ (1,0) [0|3] "" Vector__XXX
 SG_ VCLEFT_frontSeatLumbarUp m0 : 26|2@1+ (1,0) [0|3] "" Vector__XXX
 SG_ VCLEFT_frontSeatTiltDown m0 : 12|2@1+ (1,0) [0|3] "" Vector__XXX
 SG_ VCLEFT_frontSeatTiltUp m0 : 14|2@1+ (1,0) [0|3] "" Vector__XXX
 SG_ VCLEFT_frontSeatTrackBack m0 : 8|2@1+ (1,0) [0|3] "" Vector__XXX
 SG_ VCLEFT_frontSeatTrackForward m0 : 10|2@1+ (1,0) [0|3] "" Vector__XXX
 SG_ VCLEFT_hazardButtonPressed m0 : 3|1@1+ (1,0) [0|1] "" Vector__XXX
 SG_ VCLEFT_hornSwitchPressed m0 : 2|1@1+ (1,0) [0|1] "" Vector__XXX
 SG_ VCLEFT_rearCenterBuckleSwitch m0 : 62|2@1+ (1,0) [0|3] "" Vector__XXX
 SG_ VCLEFT_rearCenterOccupancySwitch m0 : 54|2@1+ (1,0) [0|3] "" Vector__XXX
 SG_ VCLEFT_rearHVACButtonPressed m0 : 61|1@1+ (1,0) [0|1] "" Vector__XXX
 SG_ VCLEFT_rearLeftBuckleSwitch m0 : 52|2@1+ (1,0) [0|3] "" Vector__XXX
 SG_ VCLEFT_rearLeftOccupancySwitch m0 : 56|2@1+ (1,0) [0|3] "" Vector__XXX
 SG_ VCLEFT_rearRightOccupancySwitch m0 : 58|2@1+ (1,0) [0|3] "" Vector__XXX
 SG_ VCLEFT_rightMirrorTilt m0 : 5|3@1+ (1,0) [0|4] "" Vector__XXX
 SG_ VCLEFT_swcLeftDoublePress m1 : 41|1@1+ (1,0) [0|1] "" Vector__XXX
 SG_ VCLEFT_swcLeftPressed m1 : 5|2@1+ (1,0) [0|3] "" Vector__XXX
 SG_ VCLEFT_swcLeftScrollTicks m1 : 16|6@1- (1,0) [-32|31] "" Vector__XXX
 SG_ VCLEFT_swcLeftTiltLeft m1 : 14|2@1+ (1,0) [0|3] "" Vector__XXX
 SG_ VCLEFT_swcLeftTiltRight m1 : 3|2@1+ (1,0) [0|3] "" Vector__XXX
 SG_ VCLEFT_swcRightDoublePress m1 : 42|1@1+ (1,0) [0|1] "" Vector__XXX
 SG_ VCLEFT_swcRightPressed m1 : 12|2@1+ (1,0) [0|3] "" Vector__XXX
 SG_ VCLEFT_swcRightScrollTicks m1 : 24|6@1- (1,0) [-32|31] "" Vector__XXX
 SG_ VCLEFT_swcRightTiltLeft m1 : 8|2@1+ (1,0) [0|3] "" Vector__XXX
 SG_ VCLEFT_swcRightTiltRight m1 : 10|2@1+ (1,0) [0|3] "" Vector__XXX

BO_ 963 ID3C3VCRIGHT_switchStatus: 7 VehicleBus
 SG_ VCRIGHT_2RowSeatReclineSwitch : 54|1@1+ (1,0) [0|1] ""   X
 SG_ VCRIGHT_btnWindowAutoDownRF : 27|1@1+ (1,0) [0|1] ""   X
 SG_ VCRIGHT_btnWindowAutoDownRR : 31|1@1+ (1,0) [0|1] ""   X
 SG_ VCRIGHT_btnWindowAutoUpRF : 25|1@1+ (1,0) [0|1] ""   X
 SG_ VCRIGHT_btnWindowAutoUpRR : 29|1@1+ (1,0) [0|1] ""   X
 SG_ VCRIGHT_btnWindowDownRF : 26|1@1+ (1,0) [0|1] ""   X
 SG_ VCRIGHT_btnWindowDownRR : 30|1@1+ (1,0) [0|1] ""   X
 SG_ VCRIGHT_btnWindowSwPackAutoDwnLF : 35|1@1+ (1,0) [0|1] ""   X
 SG_ VCRIGHT_btnWindowSwPackAutoDwnLR : 39|1@1+ (1,0) [0|1] ""   X
 SG_ VCRIGHT_btnWindowSwPackAutoDwnRR : 52|1@1+ (1,0) [0|1] ""   X
 SG_ VCRIGHT_btnWindowSwPackAutoUpLF : 33|1@1+ (1,0) [0|1] ""   X
 SG_ VCRIGHT_btnWindowSwPackAutoUpLR : 37|1@1+ (1,0) [0|1] ""   X
 SG_ VCRIGHT_btnWindowSwPackAutoUpRR : 50|1@1+ (1,0) [0|1] ""   X
 SG_ VCRIGHT_btnWindowSwPackDownLF : 34|1@1+ (1,0) [0|1] ""   X
 SG_ VCRIGHT_btnWindowSwPackDownLR : 38|1@1+ (1,0) [0|1] ""   X
 SG_ VCRIGHT_btnWindowSwPackDownRR : 51|1@1+ (1,0) [0|1] ""   X
 SG_ VCRIGHT_btnWindowSwPackUpLF : 32|1@1+ (1,0) [0|1] ""   X
 SG_ VCRIGHT_btnWindowSwPackUpLR : 36|1@1+ (1,0) [0|1] ""   X
 SG_ VCRIGHT_btnWindowSwPackUpRR : 49|1@1+ (1,0) [0|1] ""   X
 SG_ VCRIGHT_btnWindowUpRF : 24|1@1+ (1,0) [0|1] ""   X
 SG_ VCRIGHT_btnWindowUpRR : 28|1@1+ (1,0) [0|1] ""   X
 SG_ VCRIGHT_frontBuckleSwitch : 40|2@1+ (1,0) [0|3] ""   X
 SG_ VCRIGHT_frontOccupancySwitch : 42|2@1+ (1,0) [0|3] ""   X
 SG_ VCRIGHT_frontSeatBackrestBack : 12|2@1+ (1,0) [0|3] ""   X
 SG_ VCRIGHT_frontSeatBackrestForward : 14|2@1+ (1,0) [0|3] ""   X
 SG_ VCRIGHT_frontSeatLiftDown : 8|2@1+ (1,0) [0|3] ""   X
 SG_ VCRIGHT_frontSeatLiftUp : 10|2@1+ (1,0) [0|3] ""   X
 SG_ VCRIGHT_frontSeatLumbarDown : 16|2@1+ (1,0) [0|3] ""   X
 SG_ VCRIGHT_frontSeatLumbarIn : 20|2@1+ (1,0) [0|3] ""   X
 SG_ VCRIGHT_frontSeatLumbarOut : 22|2@1+ (1,0) [0|3] ""   X
 SG_ VCRIGHT_frontSeatLumbarUp : 18|2@1+ (1,0) [0|3] ""   X
 SG_ VCRIGHT_frontSeatTiltDown : 4|2@1+ (1,0) [0|3] ""   X
 SG_ VCRIGHT_frontSeatTiltUp : 6|2@1+ (1,0) [0|3] ""   X
 SG_ VCRIGHT_frontSeatTrackBack : 0|2@1+ (1,0) [0|3] ""   X
 SG_ VCRIGHT_frontSeatTrackForward : 2|2@1+ (1,0) [0|3] ""   X
 SG_ VCRIGHT_liftgateShutfaceSwitchPr : 53|1@1+ (1,0) [0|1] ""   X
 SG_ VCRIGHT_rearCenterBuckleSwitch : 44|2@1+ (1,0) [0|3] ""   X
 SG_ VCRIGHT_rearRightBuckleSwitch : 46|2@1+ (1,0) [0|3] ""   X
 SG_ VCRIGHT_trunkExtReleasePressed : 48|1@1+ (1,0) [0|1] ""   X

BO_ 964 PCS_info: 8 VEH
 SG_ PCS_infoIndex M : 0|8@1+ (1,0) [0|0] "" Vector__XXX
 SG_ PCS_buildType m10 : 8|8@1+ (1,0) [0|0] "" Vector__XXX
 SG_ PCS_buildConfigId m10 : 16|16@1+ (1,0) [0|0] "" Vector__XXX
 SG_ PCS_hardwareId m10 : 32|16@1+ (1,0) [0|0] "" Vector__XXX
 SG_ PCS_componentId m10 : 48|16@1+ (1,0) [0|0] "" Vector__XXX
 SG_ PCS_pcbaId m11 : 16|8@1+ (1,0) [0|0] "" Vector__XXX
 SG_ PCS_assemblyId m11 : 24|8@1+ (1,0) [0|0] "" Vector__XXX
 SG_ PCS_usageId m11 : 32|16@1+ (1,0) [0|0] "" Vector__XXX
 SG_ PCS_subUsageId m11 : 48|16@1+ (1,0) [0|0] "" Vector__XXX
 SG_ PCS_platformType m13 : 8|8@1+ (1,0) [0|0] "" Vector__XXX
 SG_ PCS_appCrc m13 : 32|32@1+ (1,0) [0|0] "" Vector__XXX
 SG_ PCS_cpu2AppCrc m16 : 32|32@1+ (1,0) [0|0] "" Vector__XXX
 SG_ PCS_appGitHash m17 : 10|54@1+ (4,0) [0|0] "" Vector__XXX
 SG_ PCS_bootGitHash m18 : 10|54@1+ (4,0) [0|0] "" Vector__XXX
 SG_ PCS_bootUdsProtoVersion m20 : 8|8@1+ (1,0) [0|0] "" Vector__XXX
 SG_ PCS_bootCrc m20 : 32|32@1+ (1,0) [0|0] "" Vector__XXX
 SG_ PCS_partNumChar01 m25 : 8|8@1+ (1,0) [0|0] "" Vector__XXX
 SG_ PCS_partNumChar02 m25 : 16|8@1+ (1,0) [0|0] "" Vector__XXX
 SG_ PCS_partNumChar03 m25 : 24|8@1+ (1,0) [0|0] "" Vector__XXX
 SG_ PCS_partNumChar04 m25 : 32|8@1+ (1,0) [0|0] "" Vector__XXX
 SG_ PCS_partNumChar05 m25 : 40|8@1+ (1,0) [0|0] "" Vector__XXX
 SG_ PCS_partNumChar06 m25 : 48|8@1+ (1,0) [0|0] "" Vector__XXX
 SG_ PCS_partNumChar07 m25 : 56|8@1+ (1,0) [0|0] "" Vector__XXX
 SG_ PCS_partNumChar08 m26 : 8|8@1+ (1,0) [0|0] "" Vector__XXX
 SG_ PCS_partNumChar09 m26 : 16|8@1+ (1,0) [0|0] "" Vector__XXX
 SG_ PCS_partNumChar10 m26 : 24|8@1+ (1,0) [0|0] "" Vector__XXX
 SG_ PCS_partNumChar11 m26 : 32|8@1+ (1,0) [0|0] "" Vector__XXX
 SG_ PCS_partNumChar12 m26 : 40|8@1+ (1,0) [0|0] "" Vector__XXX
 SG_ PCS_partNumChar13 m26 : 48|8@1+ (1,0) [0|0] "" Vector__XXX
 SG_ PCS_partNumChar14 m26 : 56|8@1+ (1,0) [0|0] "" Vector__XXX
 SG_ PCS_partNumChar15 m27 : 8|8@1+ (1,0) [0|0] "" Vector__XXX
 SG_ PCS_partNumChar16 m27 : 16|8@1+ (1,0) [0|0] "" Vector__XXX
 SG_ PCS_partNumChar17 m27 : 24|8@1+ (1,0) [0|0] "" Vector__XXX
 SG_ PCS_partNumChar18 m27 : 32|8@1+ (1,0) [0|0] "" Vector__XXX
 SG_ PCS_partNumChar19 m27 : 40|8@1+ (1,0) [0|0] "" Vector__XXX
 SG_ PCS_partNumChar20 m27 : 48|8@1+ (1,0) [0|0] "" Vector__XXX
 SG_ PCS_serialNumChar01 m29 : 8|8@1+ (1,0) [0|0] "" Vector__XXX
 SG_ PCS_serialNumChar02 m29 : 16|8@1+ (1,0) [0|0] "" Vector__XXX
 SG_ PCS_serialNumChar03 m29 : 24|8@1+ (1,0) [0|0] "" Vector__XXX
 SG_ PCS_serialNumChar04 m29 : 32|8@1+ (1,0) [0|0] "" Vector__XXX
 SG_ PCS_serialNumChar05 m29 : 40|8@1+ (1,0) [0|0] "" Vector__XXX
 SG_ PCS_serialNumChar06 m29 : 48|8@1+ (1,0) [0|0] "" Vector__XXX
 SG_ PCS_serialNumChar07 m29 : 56|8@1+ (1,0) [0|0] "" Vector__XXX
 SG_ PCS_serialNumChar08 m30 : 8|8@1+ (1,0) [0|0] "" Vector__XXX
 SG_ PCS_serialNumChar09 m30 : 16|8@1+ (1,0) [0|0] "" Vector__XXX
 SG_ PCS_serialNumChar10 m30 : 24|8@1+ (1,0) [0|0] "" Vector__XXX
 SG_ PCS_serialNumChar11 m30 : 32|8@1+ (1,0) [0|0] "" Vector__XXX
 SG_ PCS_serialNumChar12 m30 : 40|8@1+ (1,0) [0|0] "" Vector__XXX
 SG_ PCS_serialNumChar13 m30 : 48|8@1+ (1,0) [0|0] "" Vector__XXX
 SG_ PCS_serialNumChar14 m30 : 56|8@1+ (1,0) [0|0] "" Vector__XXX

BO_ 965 DIS_alertMatrix3: 8 VEH
 SG_ DIS_a129_epbNotApplied : 0|1@1+ (1,0) [0|0] "" Vector__XXX
 SG_ DIS_a131_highSpeedWearLimit : 2|1@1+ (1,0) [0|0] "" Vector__XXX
 SG_ DIS_a133_capacitorOT : 4|1@1+ (1,0) [0|0] "" Vector__XXX
 SG_ DIS_a134_wheelSpeedIrrational : 5|1@1+ (1,0) [0|0] "" Vector__XXX
 SG_ DIS_a136_spiError : 7|1@1+ (1,0) [0|0] "" Vector__XXX
 SG_ DIS_a142_highLashAngle : 13|1@1+ (1,0) [0|0] "" Vector__XXX
 SG_ DIS_a143_mcuLimitActive : 14|1@1+ (1,0) [0|0] "" Vector__XXX
 SG_ DIS_a144_configMismatch : 15|1@1+ (1,0) [0|0] "" Vector__XXX
 SG_ DIS_a147_highTorqueWearLimit : 18|1@1+ (1,0) [0|0] "" Vector__XXX
 SG_ DIS_a148_overtorqueUsed : 19|1@1+ (1,0) [0|0] "" Vector__XXX
 SG_ DIS_a149_oilPumpFailure : 20|1@1+ (1,0) [0|0] "" Vector__XXX
 SG_ DIS_a150_busVD : 21|1@1+ (1,0) [0|0] "" Vector__XXX
 SG_ DIS_a151_shockTorqueLimiter : 22|1@1+ (1,0) [0|0] "" Vector__XXX
 SG_ DIS_a152_linError : 23|1@1+ (1,0) [0|0] "" Vector__XXX
 SG_ DIS_a153_oilPump : 24|1@1+ (1,0) [0|0] "" Vector__XXX
 SG_ DIS_a154_resolver : 25|1@1+ (1,0) [0|0] "" Vector__XXX
 SG_ DIS_a155_vcfrontMIA : 26|1@1+ (1,0) [0|0] "" Vector__XXX
 SG_ DIS_a156_currentObserver : 27|1@1+ (1,0) [0|0] "" Vector__XXX
 SG_ DIS_a157_rcmMIA : 28|1@1+ (1,0) [0|0] "" Vector__XXX
 SG_ DIS_a158_ibstMIA : 29|1@1+ (1,0) [0|0] "" Vector__XXX
 SG_ DIS_a160_busVoltageAnomaly : 31|1@1+ (1,0) [0|0] "" Vector__XXX
 SG_ DIS_a161_epas3pMIA : 32|1@1+ (1,0) [0|0] "" Vector__XXX

BO_ 968 EPBL_alertMatrix: 8 VEH
 SG_ EPBL_matrixIndex M : 0|4@1+ (1,0) [0|0] "" Vector__XXX
 SG_ EPBL_a001_WatchdogReset m0 : 4|1@1+ (1,0) [0|0] "" Vector__XXX
 SG_ EPBL_a002_PowerLossReset m0 : 5|1@1+ (1,0) [0|0] "" Vector__XXX
 SG_ EPBL_a003_SWAssertion m0 : 6|1@1+ (1,0) [0|0] "" Vector__XXX
 SG_ EPBL_a010_ExtSupplyVoltError m0 : 13|1@1+ (1,0) [0|0] "" Vector__XXX
 SG_ EPBL_a012_CPUReset m0 : 15|1@1+ (1,0) [0|0] "" Vector__XXX
 SG_ EPBL_a013_AlertManagerFault m0 : 16|1@1+ (1,0) [0|0] "" Vector__XXX
 SG_ EPBL_a015_NVMMAlert m0 : 18|1@1+ (1,0) [0|0] "" Vector__XXX
 SG_ EPBL_a021_TaskSchedulerError m0 : 24|1@1+ (1,0) [0|0] "" Vector__XXX
 SG_ EPBL_a022_TaskInitError m0 : 25|1@1+ (1,0) [0|0] "" Vector__XXX
 SG_ EPBL_a031_UDSActive m0 : 34|1@1+ (1,0) [0|0] "" Vector__XXX
 SG_ EPBL_a041_HighCPULoad m0 : 44|1@1+ (1,0) [0|0] "" Vector__XXX
 SG_ EPBL_a042_HighStackUsage m0 : 45|1@1+ (1,0) [0|0] "" Vector__XXX
 SG_ EPBL_a043_Task1msError m0 : 46|1@1+ (1,0) [0|0] "" Vector__XXX
 SG_ EPBL_a044_Task10msError m0 : 47|1@1+ (1,0) [0|0] "" Vector__XXX
 SG_ EPBL_a045_Task100msError m0 : 48|1@1+ (1,0) [0|0] "" Vector__XXX
 SG_ EPBL_a046_Task1000msError m0 : 49|1@1+ (1,0) [0|0] "" Vector__XXX
 SG_ EPBL_a059_inputResistanceHigh m0 : 62|1@1+ (1,0) [0|0] "" Vector__XXX
 SG_ EPBL_a060_engineeringBuild m0 : 63|1@1+ (1,0) [0|0] "" Vector__XXX
 SG_ EPBL_a061_XCPConnected m1 : 4|1@1+ (1,0) [0|0] "" Vector__XXX
 SG_ EPBL_a062_XCPWasConnected m1 : 5|1@1+ (1,0) [0|0] "" Vector__XXX
 SG_ EPBL_a063_SwitchFault m1 : 6|1@1+ (1,0) [0|0] "" Vector__XXX
 SG_ EPBL_a064_busSleepReqTimeout m1 : 7|1@1+ (1,0) [0|0] "" Vector__XXX
 SG_ EPBL_a097_CMP_MIA m1 : 40|1@1+ (1,0) [0|0] "" Vector__XXX
 SG_ EPBL_a098_DI_THERMAL_MIA m1 : 41|1@1+ (1,0) [0|0] "" Vector__XXX
 SG_ EPBL_a099_PARK_MIA m1 : 42|1@1+ (1,0) [0|0] "" Vector__XXX
 SG_ EPBL_a100_CANbus_MIA m1 : 43|1@1+ (1,0) [0|0] "" Vector__XXX
 SG_ EPBL_a101_PM_MIA m1 : 44|1@1+ (1,0) [0|0] "" Vector__XXX
 SG_ EPBL_a102_PTC_MIA m1 : 45|1@1+ (1,0) [0|0] "" Vector__XXX
 SG_ EPBL_a103_CP_MIA m1 : 46|1@1+ (1,0) [0|0] "" Vector__XXX
 SG_ EPBL_a104_DAS_MIA m1 : 47|1@1+ (1,0) [0|0] "" Vector__XXX
 SG_ EPBL_a105_TAS_MIA m1 : 48|1@1+ (1,0) [0|0] "" Vector__XXX
 SG_ EPBL_a106_PCS_MIA m1 : 49|1@1+ (1,0) [0|0] "" Vector__XXX
 SG_ EPBL_a107_BMS_MIA m1 : 50|1@1+ (1,0) [0|0] "" Vector__XXX
 SG_ EPBL_a108_DIS_MIA m1 : 51|1@1+ (1,0) [0|0] "" Vector__XXX
 SG_ EPBL_a109_RCM_MIA m1 : 52|1@1+ (1,0) [0|0] "" Vector__XXX
 SG_ EPBL_a110_GTW_MIA m1 : 53|1@1+ (1,0) [0|0] "" Vector__XXX
 SG_ EPBL_a111_EPBR_MIA m1 : 54|1@1+ (1,0) [0|0] "" Vector__XXX
 SG_ EPBL_a112_EPBL_MIA m1 : 55|1@1+ (1,0) [0|0] "" Vector__XXX
 SG_ EPBL_a113_UI_MIA m1 : 56|1@1+ (1,0) [0|0] "" Vector__XXX
 SG_ EPBL_a114_ESP_MIA m1 : 57|1@1+ (1,0) [0|0] "" Vector__XXX
 SG_ EPBL_a115_VCSEC_MIA m1 : 58|1@1+ (1,0) [0|0] "" Vector__XXX
 SG_ EPBL_a116_VCRIGHT_MIA m1 : 59|1@1+ (1,0) [0|0] "" Vector__XXX
 SG_ EPBL_a117_VCLEFT_MIA m1 : 60|1@1+ (1,0) [0|0] "" Vector__XXX
 SG_ EPBL_a118_VCFRONT_MIA m1 : 61|1@1+ (1,0) [0|0] "" Vector__XXX
 SG_ EPBL_a119_SCCM_MIA m1 : 62|1@1+ (1,0) [0|0] "" Vector__XXX
 SG_ EPBL_a120_DI_DRIVE_MIA m1 : 63|1@1+ (1,0) [0|0] "" Vector__XXX
 SG_ EPBL_a121_nDriveFault m2 : 4|1@1+ (1,0) [0|0] "" Vector__XXX
 SG_ EPBL_a122_Oc m2 : 5|1@1+ (1,0) [0|0] "" Vector__XXX
 SG_ EPBL_a123_Uc m2 : 6|1@1+ (1,0) [0|0] "" Vector__XXX
 SG_ EPBL_a124_calOutOfBounds m2 : 7|1@1+ (1,0) [0|0] "" Vector__XXX
 SG_ EPBL_a125_IdleVMismatch m2 : 8|1@1+ (1,0) [0|0] "" Vector__XXX
 SG_ EPBL_a126_MotorNVoltLow m2 : 9|1@1+ (1,0) [0|0] "" Vector__XXX
 SG_ EPBL_a127_MotorNVoltHigh m2 : 10|1@1+ (1,0) [0|0] "" Vector__XXX
 SG_ EPBL_a128_MotorPVoltHigh m2 : 11|1@1+ (1,0) [0|0] "" Vector__XXX
 SG_ EPBL_a134_NvOv m2 : 17|1@1+ (1,0) [0|0] "" Vector__XXX
 SG_ EPBL_a135_NvUv m2 : 18|1@1+ (1,0) [0|0] "" Vector__XXX
 SG_ EPBL_a136_PvOv m2 : 19|1@1+ (1,0) [0|0] "" Vector__XXX
 SG_ EPBL_a137_PvUv m2 : 20|1@1+ (1,0) [0|0] "" Vector__XXX
 SG_ EPBL_a138_NVMWriteTime m2 : 21|1@1+ (1,0) [0|0] "" Vector__XXX
 SG_ EPBL_a141_invalidState m2 : 24|1@1+ (1,0) [0|0] "" Vector__XXX
 SG_ EPBL_a170_12vOv m2 : 53|1@1+ (1,0) [0|0] "" Vector__XXX
 SG_ EPBL_a171_12vUv m2 : 54|1@1+ (1,0) [0|0] "" Vector__XXX
 SG_ EPBL_a172_SPI_MIA m2 : 55|1@1+ (1,0) [0|0] "" Vector__XXX
 SG_ EPBL_a173_hiCurrentMissing m2 : 56|1@1+ (1,0) [0|0] "" Vector__XXX
 SG_ EPBL_a174_csmReleaseFailed m2 : 57|1@1+ (1,0) [0|0] "" Vector__XXX
 SG_ EPBL_a175_csmReleaseRetry m2 : 58|1@1+ (1,0) [0|0] "" Vector__XXX
 SG_ EPBL_a176_csmApplyFailed m2 : 59|1@1+ (1,0) [0|0] "" Vector__XXX
 SG_ EPBL_a177_csmApplyRetry m2 : 60|1@1+ (1,0) [0|0] "" Vector__XXX
 SG_ EPBL_a178_caliperStateUnknown m2 : 61|1@1+ (1,0) [0|0] "" Vector__XXX
 SG_ EPBL_a179_epbProblem m2 : 62|1@1+ (1,0) [0|0] "" Vector__XXX
 SG_ EPBL_a180_dynamicActive m2 : 63|1@1+ (1,0) [0|0] "" Vector__XXX
 SG_ EPBL_a181_TooSteepGradeToPark m3 : 4|1@1+ (1,0) [0|0] "" Vector__XXX
 SG_ EPBL_a182_OneEPBAppliedUnsecEnv m3 : 5|1@1+ (1,0) [0|0] "" Vector__XXX
 SG_ EPBL_a183_cdpNotAvailable m3 : 6|1@1+ (1,0) [0|0] "" Vector__XXX
 SG_ EPBL_a184_dynamicParkAbort m3 : 7|1@1+ (1,0) [0|0] "" Vector__XXX
 SG_ EPBL_a185_summonAborted m3 : 8|1@1+ (1,0) [0|0] "" Vector__XXX
 SG_ EPBL_a186_externalParkAbort m3 : 9|1@1+ (1,0) [0|0] "" Vector__XXX
 SG_ EPBL_a187_cdpDynamic m3 : 10|1@1+ (1,0) [0|0] "" Vector__XXX
 SG_ EPBL_a188_epbDynamic m3 : 11|1@1+ (1,0) [0|0] "" Vector__XXX
 SG_ EPBL_a189_epbDynamicParkCanceled m3 : 12|1@1+ (1,0) [0|0] "" Vector__XXX
 SG_ EPBL_a190_csmApplyDegraded m3 : 13|1@1+ (1,0) [0|0] "" Vector__XXX
 SG_ EPBL_a191_csmReleaseDegraded m3 : 14|1@1+ (1,0) [0|0] "" Vector__XXX
 SG_ EPBL_a195_parkForDriverIsLeaving m3 : 18|1@1+ (1,0) [0|0] "" Vector__XXX
 SG_ EPBL_a200_PmUnparkNotAllowed m3 : 23|1@1+ (1,0) [0|0] "" Vector__XXX
 SG_ EPBL_a201_hwBrakeTypeMismatch m3 : 24|1@1+ (1,0) [0|0] "" Vector__XXX
 SG_ EPBL_a216_SPI_MIA_debugData1 m3 : 39|1@1+ (1,0) [0|0] "" Vector__XXX
 SG_ EPBL_a217_SPI_MIA_debugData2 m3 : 40|1@1+ (1,0) [0|0] "" Vector__XXX
 SG_ EPBL_a241_diOutputLocked m4 : 4|1@1+ (1,0) [0|0] "" Vector__XXX
 SG_ EPBL_a242_hvOutputLocked m4 : 5|1@1+ (1,0) [0|0] "" Vector__XXX
 SG_ EPBL_a243_bdwUnavailable m4 : 6|1@1+ (1,0) [0|0] "" Vector__XXX
 SG_ EPBL_a244_WinchModeActive m4 : 7|1@1+ (1,0) [0|0] "" Vector__XXX
 SG_ EPBL_a245_serviceModeActive m4 : 8|1@1+ (1,0) [0|0] "" Vector__XXX
 SG_ EPBL_a246_idleFaultApply m4 : 9|1@1+ (1,0) [0|0] "" Vector__XXX
 SG_ EPBL_a247_csmDynamicApplyRetry m4 : 10|1@1+ (1,0) [0|0] "" Vector__XXX
 SG_ EPBL_a248_csmDynamicApplyFailed m4 : 11|1@1+ (1,0) [0|0] "" Vector__XXX
 SG_ EPBL_a249_idleFaultRelease m4 : 12|1@1+ (1,0) [0|0] "" Vector__XXX
 SG_ EPBL_a250_WinchModeCanceled m4 : 13|1@1+ (1,0) [0|0] "" Vector__XXX
 SG_ EPBL_a251_currentVarianceHigh m4 : 14|1@1+ (1,0) [0|0] "" Vector__XXX

BO_ 969 VCSEC_BLEEndpointInfo: 8 VEH
 SG_ VCSEC_BLEEndpointInfoIndex M : 0|3@1+ (1,0) [0|0] "" Vector__XXX
 SG_ VCSEC_BLELEFTCrc m0 : 8|32@1+ (1,0) [0|0] "" Vector__XXX
 SG_ VCSEC_BLELEFTComponentID m0 : 40|16@1+ (1,0) [0|0] "" Vector__XXX
 SG_ VCSEC_BLELEFTPcbaID m0 : 56|8@1+ (1,0) [0|0] "" Vector__XXX
 SG_ VCSEC_BLERIGHTCrc m1 : 8|32@1+ (1,0) [0|0] "" Vector__XXX
 SG_ VCSEC_BLERIGHTComponentID m1 : 40|16@1+ (1,0) [0|0] "" Vector__XXX
 SG_ VCSEC_BLERIGHTPcbaID m1 : 56|8@1+ (1,0) [0|0] "" Vector__XXX
 SG_ VCSEC_BLEREARCrc m2 : 8|32@1+ (1,0) [0|0] "" Vector__XXX
 SG_ VCSEC_BLEREARComponentID m2 : 40|16@1+ (1,0) [0|0] "" Vector__XXX
 SG_ VCSEC_BLEREARPcbaID m2 : 56|8@1+ (1,0) [0|0] "" Vector__XXX
 SG_ VCSEC_BLECENTERCrc m3 : 8|32@1+ (1,0) [0|0] "" Vector__XXX
 SG_ VCSEC_BLECENTERComponentID m3 : 40|16@1+ (1,0) [0|0] "" Vector__XXX
 SG_ VCSEC_BLECENTERPcbaID m3 : 56|8@1+ (1,0) [0|0] "" Vector__XXX
 SG_ VCSEC_BLELEFTAppGitHashByte m4 : 10|54@1+ (4,0) [0|0] "" Vector__XXX
 SG_ VCSEC_BLERIGHTAppGitHashByte m5 : 10|54@1+ (4,0) [0|0] "" Vector__XXX
 SG_ VCSEC_BLEREARAppGitHashByte m6 : 10|54@1+ (4,0) [0|0] "" Vector__XXX
 SG_ VCSEC_BLECENTERAppGitHashByte m7 : 10|54@1+ (4,0) [0|0] "" Vector__XXX

BO_ 970 APS_status: 4 CH
 SG_ APS_apbGpioState : 20|2@1+ (1,0) [0|0] "" Vector__XXX
 SG_ APS_apbStatusMonitorState : 16|3@1+ (1,0) [0|0] "" Vector__XXX
 SG_ APS_appGpioState : 10|2@1+ (1,0) [0|0] "" Vector__XXX
 SG_ APS_appStatusMonitorState : 0|3@1+ (1,0) [0|0] "" Vector__XXX
 SG_ APS_canMaster : 8|2@1+ (1,0) [0|0] "" Vector__XXX
 SG_ APS_eacInternalState : 12|3@1+ (1,0) [0|0] "" Vector__XXX
 SG_ APS_statusCounter : 22|4@1+ (1,0) [0|0] "" Vector__XXX
 SG_ APS_switchState : 15|1@1+ (1,0) [0|0] "" Vector__XXX
 SG_ APS_vehBehaviorState : 4|3@1+ (1,0) [0|0] "" Vector__XXX

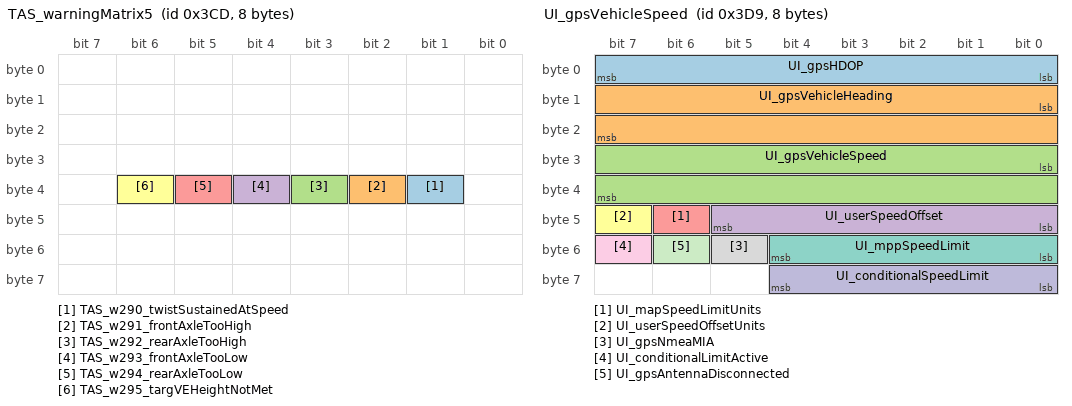
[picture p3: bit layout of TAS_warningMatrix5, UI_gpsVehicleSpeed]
BO_ 973 TAS_warningMatrix5: 8 VEH
 SG_ TAS_w290_twistSustainedAtSpeed : 33|1@1+ (1,0) [0|0] "" Vector__XXX
 SG_ TAS_w291_frontAxleTooHigh : 34|1@1+ (1,0) [0|0] "" Vector__XXX
 SG_ TAS_w292_rearAxleTooHigh : 35|1@1+ (1,0) [0|0] "" Vector__XXX
 SG_ TAS_w293_frontAxleTooLow : 36|1@1+ (1,0) [0|0] "" Vector__XXX
 SG_ TAS_w294_rearAxleTooLow : 37|1@1+ (1,0) [0|0] "" Vector__XXX
 SG_ TAS_w295_targVEHeightNotMet : 38|1@1+ (1,0) [0|0] "" Vector__XXX

BO_ 978 BMS_kwhCounter: 8 VEH
 SG_ BMS_kwhChargeTotal : 32|32@1+ (0.001,0) [0|0] "KWh" Vector__XXX
 SG_ BMS_kwhDischargeTotal : 0|32@1+ (0.001,0) [0|0] "KWh" Vector__XXX

BO_ 979 UI_airbagCutoffStatus: 1 VEH
 SG_ UI_airbagCutoffSwState : 0|2@1+ (1,0) [0|0] "" Vector__XXX
 SG_ UI_warningIndicatorStatus : 2|2@1+ (1,0) [0|0] "" Vector__XXX

BO_ 981 ESP_alertMatrix: 8 CH
 SG_ ESP_matrixIndex M : 0|4@1+ (1,0) [0|0] "" Vector__XXX
 SG_ ESP_a001_ecuGenericFault m0 : 4|1@1+ (1,0) [0|0] "" Vector__XXX
 SG_ ESP_a002_valvesGenericFault m0 : 5|1@1+ (1,0) [0|0] "" Vector__XXX
 SG_ ESP_a003_outletValvesFault m0 : 6|1@1+ (1,0) [0|0] "" Vector__XXX
 SG_ ESP_a004_inletValvesFault m0 : 7|1@1+ (1,0) [0|0] "" Vector__XXX
 SG_ ESP_a005_HSVValvesFault m0 : 8|1@1+ (1,0) [0|0] "" Vector__XXX
 SG_ ESP_a006_USVValvesFault m0 : 9|1@1+ (1,0) [0|0] "" Vector__XXX
 SG_ ESP_a007_pumpMotorFault m0 : 10|1@1+ (1,0) [0|0] "" Vector__XXX
 SG_ ESP_a008_pumpMotor12VsupplyLow m0 : 11|1@1+ (1,0) [0|0] "" Vector__XXX
 SG_ ESP_a009_12VHardUndervoltage m0 : 12|1@1+ (1,0) [0|0] "" Vector__XXX
 SG_ ESP_a010_12VUndervoltage m0 : 13|1@1+ (1,0) [0|0] "" Vector__XXX
 SG_ ESP_a011_12VSystemUndervoltage m0 : 14|1@1+ (1,0) [0|0] "" Vector__XXX
 SG_ ESP_a012_netUndervoltage m0 : 15|1@1+ (1,0) [0|0] "" Vector__XXX
 SG_ ESP_a013_valveRelayUndervoltage m0 : 16|1@1+ (1,0) [0|0] "" Vector__XXX
 SG_ ESP_a014_WSSSupplyUndervoltage m0 : 17|1@1+ (1,0) [0|0] "" Vector__XXX
 SG_ ESP_a015_12VSupplyOvervoltage m0 : 18|1@1+ (1,0) [0|0] "" Vector__XXX
 SG_ ESP_a016_12VSystemOvervoltage m0 : 19|1@1+ (1,0) [0|0] "" Vector__XXX
 SG_ ESP_a017_netOvervoltage m0 : 20|1@1+ (1,0) [0|0] "" Vector__XXX
 SG_ ESP_a018_WSSSignFrontAxle m0 : 21|1@1+ (1,0) [0|0] "" Vector__XXX
 SG_ ESP_a019_WSSSignRearAxle m0 : 22|1@1+ (1,0) [0|0] "" Vector__XXX
 SG_ ESP_a020_WSSGenericTempFault m0 : 23|1@1+ (1,0) [0|0] "" Vector__XXX
 SG_ ESP_a021_WSSGeneralVDiffFault m0 : 24|1@1+ (1,0) [0|0] "" Vector__XXX
 SG_ ESP_a022_WSSDirectionFault m0 : 25|1@1+ (1,0) [0|0] "" Vector__XXX
 SG_ ESP_a023_WSSSeveralSuspected m0 : 26|1@1+ (1,0) [0|0] "" Vector__XXX
 SG_ ESP_a024_WSSReverseCurrent m0 : 27|1@1+ (1,0) [0|0] "" Vector__XXX
 SG_ ESP_a025_FrLWSSOpenOrShortToGnd m0 : 28|1@1+ (1,0) [0|0] "" Vector__XXX
 SG_ ESP_a026_FrLWSSShortTo12V m0 : 29|1@1+ (1,0) [0|0] "" Vector__XXX
 SG_ ESP_a027_FrLWSSLineInterruption m0 : 30|1@1+ (1,0) [0|0] "" Vector__XXX
 SG_ ESP_a028_FrLWSSMaxSpeedExceeded m0 : 31|1@1+ (1,0) [0|0] "" Vector__XXX
 SG_ ESP_a029_FrLWSSTooManyPulses m0 : 32|1@1+ (1,0) [0|0] "" Vector__XXX
 SG_ ESP_a030_FrLWSSLostSignal m0 : 33|1@1+ (1,0) [0|0] "" Vector__XXX
 SG_ ESP_a031_FrLWSSNoPulsesDetected m0 : 34|1@1+ (1,0) [0|0] "" Vector__XXX
 SG_ ESP_a032_FrLWSSWrongSensorType m0 : 35|1@1+ (1,0) [0|0] "" Vector__XXX
 SG_ ESP_a033_FrLWSSSignalNoise m0 : 36|1@1+ (1,0) [0|0] "" Vector__XXX
 SG_ ESP_a034_FrLWSSVDiffFault m0 : 37|1@1+ (1,0) [0|0] "" Vector__XXX
 SG_ ESP_a035_FrLWSSDirectionFault m0 : 38|1@1+ (1,0) [0|0] "" Vector__XXX
 SG_ ESP_a036_FrLWSSLargeAirGap m0 : 39|1@1+ (1,0) [0|0] "" Vector__XXX
 SG_ ESP_a037_FrLWSSSupplyShortToGnd m0 : 40|1@1+ (1,0) [0|0] "" Vector__XXX
 SG_ ESP_a038_FrLWSSGeneralFault m0 : 41|1@1+ (1,0) [0|0] "" Vector__XXX
 SG_ ESP_a039_FrRWSSOpenOrShortToGnd m0 : 42|1@1+ (1,0) [0|0] "" Vector__XXX
 SG_ ESP_a040_FrRWSSShortTo12V m0 : 43|1@1+ (1,0) [0|0] "" Vector__XXX
 SG_ ESP_a041_FrRWSSLineInterruption m0 : 44|1@1+ (1,0) [0|0] "" Vector__XXX
 SG_ ESP_a042_FrRWSSMaxSpeedExceeded m0 : 45|1@1+ (1,0) [0|0] "" Vector__XXX
 SG_ ESP_a043_FrRWSSTooManyPulses m0 : 46|1@1+ (1,0) [0|0] "" Vector__XXX
 SG_ ESP_a044_FrRWSSLostSignal m0 : 47|1@1+ (1,0) [0|0] "" Vector__XXX
 SG_ ESP_a045_FrRWSSNoPulsesDetected m0 : 48|1@1+ (1,0) [0|0] "" Vector__XXX
 SG_ ESP_a046_FrRWSSWrongSensorType m0 : 49|1@1+ (1,0) [0|0] "" Vector__XXX
 SG_ ESP_a047_FrRWSSSignalNoise m0 : 50|1@1+ (1,0) [0|0] "" Vector__XXX
 SG_ ESP_a048_FrRWSSVDiffFault m0 : 51|1@1+ (1,0) [0|0] "" Vector__XXX
 SG_ ESP_a049_FrRWSSDirectionFault m0 : 52|1@1+ (1,0) [0|0] "" Vector__XXX
 SG_ ESP_a050_FrRWSSLargeAirGap m0 : 53|1@1+ (1,0) [0|0] "" Vector__XXX
 SG_ ESP_a051_FrRWSSSupplyShortToGnd m0 : 54|1@1+ (1,0) [0|0] "" Vector__XXX
 SG_ ESP_a052_FrRWSSGeneralFault m0 : 55|1@1+ (1,0) [0|0] "" Vector__XXX
 SG_ ESP_a053_ReLWSSOpenOrShortToGnd m0 : 56|1@1+ (1,0) [0|0] "" Vector__XXX
 SG_ ESP_a054_ReLWSSShortTo12V m0 : 57|1@1+ (1,0) [0|0] "" Vector__XXX
 SG_ ESP_a055_ReLWSSLineInterruption m0 : 58|1@1+ (1,0) [0|0] "" Vector__XXX
 SG_ ESP_a056_ReLWSSMaxSpeedExceeded m0 : 59|1@1+ (1,0) [0|0] "" Vector__XXX
 SG_ ESP_a057_ReLWSSTooManyPulses m0 : 60|1@1+ (1,0) [0|0] "" Vector__XXX
 SG_ ESP_a058_ReLWSSLostSignal m0 : 61|1@1+ (1,0) [0|0] "" Vector__XXX
 SG_ ESP_a059_ReLWSSNoPulsesDetected m0 : 62|1@1+ (1,0) [0|0] "" Vector__XXX
 SG_ ESP_a060_ReLWSSWrongSensorType m0 : 63|1@1+ (1,0) [0|0] "" Vector__XXX
 SG_ ESP_a061_ReLWSSSignalNoise m1 : 4|1@1+ (1,0) [0|0] "" Vector__XXX
 SG_ ESP_a062_ReLWSSVDiffFault m1 : 5|1@1+ (1,0) [0|0] "" Vector__XXX
 SG_ ESP_a063_ReLWSSDirectionFault m1 : 6|1@1+ (1,0) [0|0] "" Vector__XXX
 SG_ ESP_a064_ReLWSSLargeAirGap m1 : 7|1@1+ (1,0) [0|0] "" Vector__XXX
 SG_ ESP_a065_ReLWSSSupplyShortToGnd m1 : 8|1@1+ (1,0) [0|0] "" Vector__XXX
 SG_ ESP_a066_ReLWSSGeneralFault m1 : 9|1@1+ (1,0) [0|0] "" Vector__XXX
 SG_ ESP_a067_ReRWSSOpenOrShortToGnd m1 : 10|1@1+ (1,0) [0|0] "" Vector__XXX
 SG_ ESP_a068_ReRWSSShortTo12V m1 : 11|1@1+ (1,0) [0|0] "" Vector__XXX
 SG_ ESP_a069_ReRWSSLineInterruption m1 : 12|1@1+ (1,0) [0|0] "" Vector__XXX
 SG_ ESP_a070_ReRWSSMaxSpeedExceeded m1 : 13|1@1+ (1,0) [0|0] "" Vector__XXX
 SG_ ESP_a071_ReRWSSTooManyPulses m1 : 14|1@1+ (1,0) [0|0] "" Vector__XXX
 SG_ ESP_a072_ReRWSSLostSignal m1 : 15|1@1+ (1,0) [0|0] "" Vector__XXX
 SG_ ESP_a073_ReRWSSNoPulsesDetected m1 : 16|1@1+ (1,0) [0|0] "" Vector__XXX
 SG_ ESP_a074_ReRWSSWrongSensorType m1 : 17|1@1+ (1,0) [0|0] "" Vector__XXX
 SG_ ESP_a075_ReRWSSSignalNoise m1 : 18|1@1+ (1,0) [0|0] "" Vector__XXX
 SG_ ESP_a076_ReRWSSVDiffFault m1 : 19|1@1+ (1,0) [0|0] "" Vector__XXX
 SG_ ESP_a077_ReRWSSDirectionFault m1 : 20|1@1+ (1,0) [0|0] "" Vector__XXX
 SG_ ESP_a078_ReRWSSLargeAirGap m1 : 21|1@1+ (1,0) [0|0] "" Vector__XXX
 SG_ ESP_a079_ReRWSSSupplyShortToGnd m1 : 22|1@1+ (1,0) [0|0] "" Vector__XXX
 SG_ ESP_a080_ReRWSSGeneralFault m1 : 23|1@1+ (1,0) [0|0] "" Vector__XXX
 SG_ ESP_a081_PressureSensorShort m1 : 24|1@1+ (1,0) [0|0] "" Vector__XXX
 SG_ ESP_a082_PMCSensorOffsVEHigh m1 : 25|1@1+ (1,0) [0|0] "" Vector__XXX
 SG_ ESP_a083_PMCSensorFault m1 : 26|1@1+ (1,0) [0|0] "" Vector__XXX
 SG_ ESP_a084_BrakeFluidReservoirLow m1 : 27|1@1+ (1,0) [0|0] "" Vector__XXX
 SG_ ESP_a085_BrakeSwitchStuckHigh m1 : 28|1@1+ (1,0) [0|0] "" Vector__XXX
 SG_ ESP_a086_BrakeSwitchImplausible1 m1 : 29|1@1+ (1,0) [0|0] "" Vector__XXX
 SG_ ESP_a087_BrakeSwitchImplausible3 m1 : 30|1@1+ (1,0) [0|0] "" Vector__XXX
 SG_ ESP_a088_absContinuousControl m1 : 31|1@1+ (1,0) [0|0] "" Vector__XXX
 SG_ ESP_a089_absNoPressureIncrease m1 : 32|1@1+ (1,0) [0|0] "" Vector__XXX
 SG_ ESP_a090_vdcContinuousControl m1 : 33|1@1+ (1,0) [0|0] "" Vector__XXX
 SG_ ESP_a091_CANUndervoltage m1 : 34|1@1+ (1,0) [0|0] "" Vector__XXX
 SG_ ESP_a092_CANOvervoltage m1 : 35|1@1+ (1,0) [0|0] "" Vector__XXX
 SG_ ESP_a093_partyBusOff m1 : 36|1@1+ (1,0) [0|0] "" Vector__XXX
 SG_ ESP_a094_partyBusPassive m1 : 37|1@1+ (1,0) [0|0] "" Vector__XXX
 SG_ ESP_a095_CHOff m1 : 38|1@1+ (1,0) [0|0] "" Vector__XXX
 SG_ ESP_a096_CHPassive m1 : 39|1@1+ (1,0) [0|0] "" Vector__XXX
 SG_ ESP_a097_tcsRefSpeedNotInit m1 : 40|1@1+ (1,0) [0|0] "" Vector__XXX
 SG_ ESP_a098_vdcRefSpeedNotInit m1 : 41|1@1+ (1,0) [0|0] "" Vector__XXX
 SG_ ESP_a099_brakeTempModelOverheat m1 : 42|1@1+ (1,0) [0|0] "" Vector__XXX
 SG_ ESP_a100_brakeTempModelDisabled m1 : 43|1@1+ (1,0) [0|0] "" Vector__XXX
 SG_ ESP_a101_ebdFault m1 : 44|1@1+ (1,0) [0|0] "" Vector__XXX
 SG_ ESP_a102_absFault m1 : 45|1@1+ (1,0) [0|0] "" Vector__XXX
 SG_ ESP_a103_stabilityControlFault m1 : 46|1@1+ (1,0) [0|0] "" Vector__XXX
 SG_ ESP_a104_hbcEnabled m1 : 47|1@1+ (1,0) [0|0] "" Vector__XXX
 SG_ ESP_a105_ebrFault m1 : 48|1@1+ (1,0) [0|0] "" Vector__XXX
 SG_ ESP_a106_vdcActuatorFault m1 : 49|1@1+ (1,0) [0|0] "" Vector__XXX
 SG_ ESP_a107_reserved107 m1 : 50|1@1+ (1,0) [0|0] "" Vector__XXX
 SG_ ESP_a108_reserved108 m1 : 51|1@1+ (1,0) [0|0] "" Vector__XXX
 SG_ ESP_a109_reserved109 m1 : 52|1@1+ (1,0) [0|0] "" Vector__XXX
 SG_ ESP_a110_rollerBenchActive m1 : 53|1@1+ (1,0) [0|0] "" Vector__XXX
 SG_ ESP_a111_absActive m1 : 54|1@1+ (1,0) [0|0] "" Vector__XXX
 SG_ ESP_a112_espActive m1 : 55|1@1+ (1,0) [0|0] "" Vector__XXX
 SG_ ESP_a113_btcActive m1 : 56|1@1+ (1,0) [0|0] "" Vector__XXX
 SG_ ESP_a114_tvdcActive m1 : 57|1@1+ (1,0) [0|0] "" Vector__XXX
 SG_ ESP_a115_ebdActive m1 : 58|1@1+ (1,0) [0|0] "" Vector__XXX
 SG_ ESP_a116_tsmActive m1 : 59|1@1+ (1,0) [0|0] "" Vector__XXX
 SG_ ESP_a117_hbaActive m1 : 60|1@1+ (1,0) [0|0] "" Vector__XXX
 SG_ ESP_a118_hfcActive m1 : 61|1@1+ (1,0) [0|0] "" Vector__XXX
 SG_ ESP_a119_hbbActive m1 : 62|1@1+ (1,0) [0|0] "" Vector__XXX
 SG_ ESP_a120_rmiActive m1 : 63|1@1+ (1,0) [0|0] "" Vector__XXX
 SG_ ESP_a121_regenTcActive m2 : 4|1@1+ (1,0) [0|0] "" Vector__XXX
 SG_ ESP_a122_bdwActive m2 : 5|1@1+ (1,0) [0|0] "" Vector__XXX
 SG_ ESP_a123_ebrActive m2 : 6|1@1+ (1,0) [0|0] "" Vector__XXX
 SG_ ESP_a124_ebrSkidActive m2 : 7|1@1+ (1,0) [0|0] "" Vector__XXX
 SG_ ESP_a125_reserved125 m2 : 8|1@1+ (1,0) [0|0] "" Vector__XXX
 SG_ ESP_a126_reserved126 m2 : 9|1@1+ (1,0) [0|0] "" Vector__XXX
 SG_ ESP_a127_reserved127 m2 : 10|1@1+ (1,0) [0|0] "" Vector__XXX
 SG_ ESP_a128_reserved128 m2 : 11|1@1+ (1,0) [0|0] "" Vector__XXX
 SG_ ESP_a129_reserved129 m2 : 12|1@1+ (1,0) [0|0] "" Vector__XXX
 SG_ ESP_a130_EPAS3PsysStatusTimeout m2 : 13|1@1+ (1,0) [0|0] "" Vector__XXX
 SG_ ESP_a131_EPAS3PsysStatusDLC m2 : 14|1@1+ (1,0) [0|0] "" Vector__XXX
 SG_ ESP_a132_EPAS3PsysStatusChecksum m2 : 15|1@1+ (1,0) [0|0] "" Vector__XXX
 SG_ ESP_a133_EPAS3PsysStatusCounter m2 : 16|1@1+ (1,0) [0|0] "" Vector__XXX
 SG_ ESP_a134_steeringAngleInvalid m2 : 17|1@1+ (1,0) [0|0] "" Vector__XXX
 SG_ ESP_a135_steeringAngleNoCenter m2 : 18|1@1+ (1,0) [0|0] "" Vector__XXX
 SG_ ESP_a136_steeringAngleFrozen m2 : 19|1@1+ (1,0) [0|0] "" Vector__XXX
 SG_ ESP_a137_steeringOffsetTooLarge m2 : 20|1@1+ (1,0) [0|0] "" Vector__XXX
 SG_ ESP_a138_steeringAngleImplaus m2 : 21|1@1+ (1,0) [0|0] "" Vector__XXX
 SG_ ESP_a139_steeringAngleWrongSign m2 : 22|1@1+ (1,0) [0|0] "" Vector__XXX
 SG_ ESP_a140_RCMInertial1Timeout m2 : 23|1@1+ (1,0) [0|0] "" Vector__XXX
 SG_ ESP_a141_RCMInertial1DLC m2 : 24|1@1+ (1,0) [0|0] "" Vector__XXX
 SG_ ESP_a142_RCMInertial1Checksum m2 : 25|1@1+ (1,0) [0|0] "" Vector__XXX
 SG_ ESP_a143_RCMInertial1Counter m2 : 26|1@1+ (1,0) [0|0] "" Vector__XXX
 SG_ ESP_a144_yawMaxLatency m2 : 27|1@1+ (1,0) [0|0] "" Vector__XXX
 SG_ ESP_a145_yawInitFault m2 : 28|1@1+ (1,0) [0|0] "" Vector__XXX
 SG_ ESP_a146_yawInvalidValue m2 : 29|1@1+ (1,0) [0|0] "" Vector__XXX
 SG_ ESP_a147_yawSensorNotAvailable m2 : 30|1@1+ (1,0) [0|0] "" Vector__XXX
 SG_ ESP_a148_yawSignalFault m2 : 31|1@1+ (1,0) [0|0] "" Vector__XXX
 SG_ ESP_a149_yawInvalidSign m2 : 32|1@1+ (1,0) [0|0] "" Vector__XXX
 SG_ ESP_a150_yawImplausible m2 : 33|1@1+ (1,0) [0|0] "" Vector__XXX
 SG_ ESP_a151_RCMInertial2Timeout m2 : 34|1@1+ (1,0) [0|0] "" Vector__XXX
 SG_ ESP_a152_RCMInertial2DLC m2 : 35|1@1+ (1,0) [0|0] "" Vector__XXX
 SG_ ESP_a153_RCMInertial2Checksum m2 : 36|1@1+ (1,0) [0|0] "" Vector__XXX
 SG_ ESP_a154_RCMInertial2Counter m2 : 37|1@1+ (1,0) [0|0] "" Vector__XXX
 SG_ ESP_a155_ayMaxLatency m2 : 38|1@1+ (1,0) [0|0] "" Vector__XXX
 SG_ ESP_a156_ayInitFault m2 : 39|1@1+ (1,0) [0|0] "" Vector__XXX
 SG_ ESP_a157_ayInvalidValue m2 : 40|1@1+ (1,0) [0|0] "" Vector__XXX
 SG_ ESP_a158_aySensorNotAvailable m2 : 41|1@1+ (1,0) [0|0] "" Vector__XXX
 SG_ ESP_a159_aySignalFault m2 : 42|1@1+ (1,0) [0|0] "" Vector__XXX
 SG_ ESP_a160_ayRangeExceeded m2 : 43|1@1+ (1,0) [0|0] "" Vector__XXX
 SG_ ESP_a161_ayOffsetExceeded m2 : 44|1@1+ (1,0) [0|0] "" Vector__XXX
 SG_ ESP_a162_ayImplausible m2 : 45|1@1+ (1,0) [0|0] "" Vector__XXX
 SG_ ESP_a163_axMaxLatency m2 : 46|1@1+ (1,0) [0|0] "" Vector__XXX
 SG_ ESP_a164_axInitFault m2 : 47|1@1+ (1,0) [0|0] "" Vector__XXX
 SG_ ESP_a165_axInvalidValue m2 : 48|1@1+ (1,0) [0|0] "" Vector__XXX
 SG_ ESP_a166_axSensorNotAvailable m2 : 49|1@1+ (1,0) [0|0] "" Vector__XXX
 SG_ ESP_a167_axSignalFault m2 : 50|1@1+ (1,0) [0|0] "" Vector__XXX
 SG_ ESP_a168_axRangeExceeded m2 : 51|1@1+ (1,0) [0|0] "" Vector__XXX
 SG_ ESP_a169_axOffsetExceeded m2 : 52|1@1+ (1,0) [0|0] "" Vector__XXX
 SG_ ESP_a170_axSignalFrozen m2 : 53|1@1+ (1,0) [0|0] "" Vector__XXX
 SG_ ESP_a171_axImplausible m2 : 54|1@1+ (1,0) [0|0] "" Vector__XXX
 SG_ ESP_a172_IBSTparty1Timeout m2 : 55|1@1+ (1,0) [0|0] "" Vector__XXX
 SG_ ESP_a173_IBSTparty1DLC m2 : 56|1@1+ (1,0) [0|0] "" Vector__XXX
 SG_ ESP_a174_IBSTparty1Checksum m2 : 57|1@1+ (1,0) [0|0] "" Vector__XXX
 SG_ ESP_a175_IBSTparty1Counter m2 : 58|1@1+ (1,0) [0|0] "" Vector__XXX
 SG_ ESP_a176_IBSTEBRNotAvailable m2 : 59|1@1+ (1,0) [0|0] "" Vector__XXX
 SG_ ESP_a177_IBSTOutputRodDrvInvalid m2 : 60|1@1+ (1,0) [0|0] "" Vector__XXX
 SG_ ESP_a178_IBSTOutputRodActInvalid m2 : 61|1@1+ (1,0) [0|0] "" Vector__XXX
 SG_ ESP_a179_IBSTparty2Timeout m2 : 62|1@1+ (1,0) [0|0] "" Vector__XXX
 SG_ ESP_a180_IBSTparty2Checksum m2 : 63|1@1+ (1,0) [0|0] "" Vector__XXX
 SG_ ESP_a181_IBSTparty2DLC m3 : 4|1@1+ (1,0) [0|0] "" Vector__XXX
 SG_ ESP_a182_IBSTparty2Counter m3 : 5|1@1+ (1,0) [0|0] "" Vector__XXX
 SG_ ESP_a183_IBSTStatusOff m3 : 6|1@1+ (1,0) [0|0] "" Vector__XXX
 SG_ ESP_a184_IBSTpRunoutInvalid m3 : 7|1@1+ (1,0) [0|0] "" Vector__XXX
 SG_ ESP_a185_IBSTFeedforwardBackup m3 : 8|1@1+ (1,0) [0|0] "" Vector__XXX
 SG_ ESP_a186_IBSTBrakeAppliedInvalid m3 : 9|1@1+ (1,0) [0|0] "" Vector__XXX
 SG_ ESP_a187_DIbtcRequestTimeout m3 : 10|1@1+ (1,0) [0|0] "" Vector__XXX
 SG_ ESP_a188_DIbtcRequestDLC m3 : 11|1@1+ (1,0) [0|0] "" Vector__XXX
 SG_ ESP_a189_DIbtcRequestChecksum m3 : 12|1@1+ (1,0) [0|0] "" Vector__XXX
 SG_ ESP_a190_DIbtcRequestCounter m3 : 13|1@1+ (1,0) [0|0] "" Vector__XXX
 SG_ ESP_a191_DIchassiControlTimeout m3 : 14|1@1+ (1,0) [0|0] "" Vector__XXX
 SG_ ESP_a192_DIchassiControlDLC m3 : 15|1@1+ (1,0) [0|0] "" Vector__XXX
 SG_ ESP_a193_DIchassiControlChecksum m3 : 16|1@1+ (1,0) [0|0] "" Vector__XXX
 SG_ ESP_a194_DIchassiControlCounter m3 : 17|1@1+ (1,0) [0|0] "" Vector__XXX
 SG_ ESP_a195_ptcStateInvalid m3 : 18|1@1+ (1,0) [0|0] "" Vector__XXX
 SG_ ESP_a196_DIsystemStatusTimeout m3 : 19|1@1+ (1,0) [0|0] "" Vector__XXX
 SG_ ESP_a197_DIsystemStatusDLC m3 : 20|1@1+ (1,0) [0|0] "" Vector__XXX
 SG_ ESP_a198_DIsystemStatusChecksum m3 : 21|1@1+ (1,0) [0|0] "" Vector__XXX
 SG_ ESP_a199_DIsystemStatusCounter m3 : 22|1@1+ (1,0) [0|0] "" Vector__XXX
 SG_ ESP_a200_reverseGearStuckHigh m3 : 23|1@1+ (1,0) [0|0] "" Vector__XXX
 SG_ ESP_a201_reverseGearStuckLow m3 : 24|1@1+ (1,0) [0|0] "" Vector__XXX
 SG_ ESP_a202_accelPedalInvalid m3 : 25|1@1+ (1,0) [0|0] "" Vector__XXX
 SG_ ESP_a203_DItorqueTimeout m3 : 26|1@1+ (1,0) [0|0] "" Vector__XXX
 SG_ ESP_a204_DItorqueDLC m3 : 27|1@1+ (1,0) [0|0] "" Vector__XXX
 SG_ ESP_a205_DItorqueChecksum m3 : 28|1@1+ (1,0) [0|0] "" Vector__XXX
 SG_ ESP_a206_DItorqueCounter m3 : 29|1@1+ (1,0) [0|0] "" Vector__XXX
 SG_ ESP_a207_DITorqueCommandInvalid m3 : 30|1@1+ (1,0) [0|0] "" Vector__XXX
 SG_ ESP_a208_DIRPMInvalid m3 : 31|1@1+ (1,0) [0|0] "" Vector__XXX
 SG_ ESP_a209_DITorqueActualInvalid m3 : 32|1@1+ (1,0) [0|0] "" Vector__XXX
 SG_ ESP_a210_DIStorqueTimeout m3 : 33|1@1+ (1,0) [0|0] "" Vector__XXX
 SG_ ESP_a211_DIStorqueDLC m3 : 34|1@1+ (1,0) [0|0] "" Vector__XXX
 SG_ ESP_a212_DIStorqueChecksum m3 : 35|1@1+ (1,0) [0|0] "" Vector__XXX
 SG_ ESP_a213_DIStorqueCounter m3 : 36|1@1+ (1,0) [0|0] "" Vector__XXX
 SG_ ESP_a214_DISTorqueCommandInvalid m3 : 37|1@1+ (1,0) [0|0] "" Vector__XXX
 SG_ ESP_a215_DISRPMInvalid m3 : 38|1@1+ (1,0) [0|0] "" Vector__XXX
 SG_ ESP_a216_DISTorqueActualInvalid m3 : 39|1@1+ (1,0) [0|0] "" Vector__XXX
 SG_ ESP_a217_DIvdcLeftTimeout m3 : 40|1@1+ (1,0) [0|0] "" Vector__XXX
 SG_ ESP_a218_DIvdcLeftDLC m3 : 41|1@1+ (1,0) [0|0] "" Vector__XXX
 SG_ ESP_a219_DIvdcLeftChecksum m3 : 42|1@1+ (1,0) [0|0] "" Vector__XXX
 SG_ ESP_a220_DIvdcLeftCounter m3 : 43|1@1+ (1,0) [0|0] "" Vector__XXX
 SG_ ESP_a221_DIvdcRightTimeout m3 : 44|1@1+ (1,0) [0|0] "" Vector__XXX
 SG_ ESP_a222_DIvdcRightDLC m3 : 45|1@1+ (1,0) [0|0] "" Vector__XXX
 SG_ ESP_a223_DIvdcRightChecksum m3 : 46|1@1+ (1,0) [0|0] "" Vector__XXX
 SG_ ESP_a224_DIvdcRightCounter m3 : 47|1@1+ (1,0) [0|0] "" Vector__XXX
 SG_ ESP_a225_configMismatch m3 : 48|1@1+ (1,0) [0|0] "" Vector__XXX
 SG_ ESP_a226_bdwRequestInvalid m3 : 49|1@1+ (1,0) [0|0] "" Vector__XXX
 SG_ ESP_a227_bdwRequestActiveInvalid m3 : 50|1@1+ (1,0) [0|0] "" Vector__XXX
 SG_ ESP_a228_GTWvinTimeout m3 : 51|1@1+ (1,0) [0|0] "" Vector__XXX
 SG_ ESP_a229_GTWvinDLC m3 : 52|1@1+ (1,0) [0|0] "" Vector__XXX
 SG_ ESP_a230_vinNotLearned m3 : 53|1@1+ (1,0) [0|0] "" Vector__XXX
 SG_ ESP_a231_storedVINMismatch m3 : 54|1@1+ (1,0) [0|0] "" Vector__XXX
 SG_ ESP_a232_PMstate2Timeout m3 : 55|1@1+ (1,0) [0|0] "" Vector__XXX
 SG_ ESP_a233_PMstate2Checksum m3 : 56|1@1+ (1,0) [0|0] "" Vector__XXX
 SG_ ESP_a234_PMstate2DLC m3 : 57|1@1+ (1,0) [0|0] "" Vector__XXX
 SG_ ESP_a235_PMstate2Counter m3 : 58|1@1+ (1,0) [0|0] "" Vector__XXX
 SG_ ESP_a236_ebrCommandStateInvalid m3 : 59|1@1+ (1,0) [0|0] "" Vector__XXX
 SG_ ESP_a237_vdcCommandStateInvalid m3 : 60|1@1+ (1,0) [0|0] "" Vector__XXX
 SG_ ESP_a238_UIodoTimeout m3 : 61|1@1+ (1,0) [0|0] "" Vector__XXX
 SG_ ESP_a239_UIodoDLC m3 : 62|1@1+ (1,0) [0|0] "" Vector__XXX
 SG_ ESP_a240_LVPowerStateTimeout m3 : 63|1@1+ (1,0) [0|0] "" Vector__XXX
 SG_ ESP_a241_LVPowerStateChecksum m4 : 4|1@1+ (1,0) [0|0] "" Vector__XXX
 SG_ ESP_a242_LVPowerStateDLC m4 : 5|1@1+ (1,0) [0|0] "" Vector__XXX
 SG_ ESP_a243_LVPowerStateCounter m4 : 6|1@1+ (1,0) [0|0] "" Vector__XXX
 SG_ ESP_a244_LVOffStateInvalid m4 : 7|1@1+ (1,0) [0|0] "" Vector__XXX
 SG_ ESP_a245_LVGoingDownStateInvalid m4 : 8|1@1+ (1,0) [0|0] "" Vector__XXX
 SG_ ESP_a246_VCFRONTsensorTimeout m4 : 9|1@1+ (1,0) [0|0] "" Vector__XXX
 SG_ ESP_a247_VCFRONTsensorDLC m4 : 10|1@1+ (1,0) [0|0] "" Vector__XXX
 SG_ ESP_a248_vdcBrkeTrqTarFrLInvalid m4 : 11|1@1+ (1,0) [0|0] "" Vector__XXX
 SG_ ESP_a249_vdcBrkeTrqTarFrRInvalid m4 : 12|1@1+ (1,0) [0|0] "" Vector__XXX
 SG_ ESP_a250_vdcBrkeTrqTarReLInvalid m4 : 13|1@1+ (1,0) [0|0] "" Vector__XXX
 SG_ ESP_a251_vdcBrkeTrqTarReRInvalid m4 : 14|1@1+ (1,0) [0|0] "" Vector__XXX
 SG_ ESP_a252_vdcWhlSlipLimFrLInvalid m4 : 15|1@1+ (1,0) [0|0] "" Vector__XXX
 SG_ ESP_a253_vdcWhlSlipLimFrRInvalid m4 : 16|1@1+ (1,0) [0|0] "" Vector__XXX
 SG_ ESP_a254_vdcWhlSlipLimReLInvalid m4 : 17|1@1+ (1,0) [0|0] "" Vector__XXX
 SG_ ESP_a255_vdcWhlSlipLimReRInvalid m4 : 18|1@1+ (1,0) [0|0] "" Vector__XXX
 SG_ ESP_a256_epbmStatusTimeout m4 : 19|1@1+ (1,0) [0|0] "" Vector__XXX
 SG_ ESP_a257_epbmStatusChecksum m4 : 20|1@1+ (1,0) [0|0] "" Vector__XXX
 SG_ ESP_a258_epbmStatusDLC m4 : 21|1@1+ (1,0) [0|0] "" Vector__XXX
 SG_ ESP_a259_epbmStatusCounter m4 : 22|1@1+ (1,0) [0|0] "" Vector__XXX
 SG_ ESP_a260_epblStatusTimeout m4 : 23|1@1+ (1,0) [0|0] "" Vector__XXX
 SG_ ESP_a261_epblStatusChecksum m4 : 24|1@1+ (1,0) [0|0] "" Vector__XXX
 SG_ ESP_a262_epblStatusDLC m4 : 25|1@1+ (1,0) [0|0] "" Vector__XXX
 SG_ ESP_a263_epblStatusCounter m4 : 26|1@1+ (1,0) [0|0] "" Vector__XXX

BO_ 984 UI_elevationStatus: 2 VEH
 SG_ UI_elevation : 0|14@1+ (1,0) [0|0] "m" Vector__XXX

BO_ 985 UI_gpsVehicleSpeed: 8 CH
 SG_ UI_gpsHDOP : 0|8@1+ (0.1,0) [0|0] "1" Vector__XXX
 SG_ UI_gpsVehicleHeading : 8|16@1+ (0.0078125,0) [0|0] "deg" Vector__XXX
 SG_ UI_gpsVehicleSpeed : 24|16@1+ (0.00390625,0) [0|0] "km/hr" Vector__XXX
 SG_ UI_userSpeedOffset : 40|6@1+ (1,-30) [0|0] "kph/mph" Vector__XXX
 SG_ UI_mapSpeedLimitUnits : 46|1@1+ (1,0) [0|0] "" Vector__XXX
 SG_ UI_userSpeedOffsetUnits : 47|1@1+ (1,0) [0|0] "" Vector__XXX
 SG_ UI_mppSpeedLimit : 48|5@1+ (5,0) [0|0] "kph/mph" Vector__XXX
 SG_ UI_gpsNmeaMIA : 53|1@1+ (1,0) [0|0] "" Vector__XXX
 SG_ UI_conditionalLimitActive : 55|1@1+ (1,0) [0|1] "" Vector__XXX
 SG_ UI_conditionalSpeedLimit : 56|5@1+ (5,0) [0|155] "kph/mph" Vector__XXX
 SG_ UI_gpsAntennaDisconnected : 54|1@1+ (1,0) [0|1] "" Vector__XXX

BO_ 986 DAS_telemetryEvent: 8 VEH
 SG_ DAS_TE_multiplexer M : 0|5@1+ (1,0) [0|0] "" Vector__XXX
 SG_ DAS_TE_counter m0 : 5|3@1+ (1,0) [0|0] "" Vector__XXX
 SG_ DAS_TE_eventID m0 : 8|16@1+ (1,0) [0|0] "" Vector__XXX
 SG_ DAS_TE_eventType m0 : 24|6@1+ (1,0) [0|0] "" Vector__XXX
 SG_ DAS_TE_lcAbortReason m0 : 32|5@1+ (1,0) [0|0] "" Vector__XXX
 SG_ DAS_TE_llCounter m1 : 5|3@1+ (1,0) [0|0] "" Vector__XXX
 SG_ DAS_TE_llC0 m1 : 8|10@1- (0.02,0) [0|0] "m" Vector__XXX
 SG_ DAS_TE_llC1 m1 : 18|9@1- (0.00195313,0) [0|0] "rad" Vector__XXX
 SG_ DAS_TE_llC2 m1 : 27|14@1- (4e-06,0) [0|0] "1/m" Vector__XXX
 SG_ DAS_TE_llC3 m1 : 41|14@1- (1.6e-08,0) [0|0] "1/m2" Vector__XXX
 SG_ DAS_TE_llQlty m1 : 55|1@1+ (1,0) [0|0] "" Vector__XXX
 SG_ DAS_TE_llRange m1 : 56|7@1+ (1,0) [0|0] "m" Vector__XXX
 SG_ DAS_TE_llFuse m1 : 63|1@1+ (1,0) [0|0] "" Vector__XXX
 SG_ DAS_TE_rlCounter m2 : 5|3@1+ (1,0) [0|0] "" Vector__XXX
 SG_ DAS_TE_rlC0 m2 : 8|10@1- (0.02,0) [0|0] "m" Vector__XXX
 SG_ DAS_TE_rlC1 m2 : 18|9@1- (0.00195313,0) [0|0] "rad" Vector__XXX
 SG_ DAS_TE_rlC2 m2 : 27|14@1- (4e-06,0) [0|0] "1/m" Vector__XXX
 SG_ DAS_TE_rlC3 m2 : 41|14@1- (1.6e-08,0) [0|0] "1/m2" Vector__XXX
 SG_ DAS_TE_rlQlty m2 : 55|1@1+ (1,0) [0|0] "" Vector__XXX
 SG_ DAS_TE_rlRange m2 : 56|7@1+ (1,0) [0|0] "m" Vector__XXX
 SG_ DAS_TE_rlFuse m2 : 63|1@1+ (1,0) [0|0] "" Vector__XXX
 SG_ DAS_TE_hppCounter m3 : 5|3@1+ (1,0) [0|0] "" Vector__XXX
 SG_ DAS_TE_hppC0 m3 : 8|10@1- (0.02,0) [0|0] "m" Vector__XXX
 SG_ DAS_TE_hppC1 m3 : 18|9@1- (0.00195313,0) [0|0] "rad" Vector__XXX
 SG_ DAS_TE_hppC2 m3 : 27|14@1- (4e-06,0) [0|0] "1/m" Vector__XXX
 SG_ DAS_TE_hppC3 m3 : 41|14@1- (1.6e-08,0) [0|0] "1/m2" Vector__XXX
 SG_ DAS_TE_hppQlty m3 : 55|1@1+ (1,0) [0|0] "" Vector__XXX
 SG_ DAS_TE_hppRange m3 : 56|7@1+ (1,0) [0|0] "m" Vector__XXX
 SG_ DAS_TE_hppFuse m3 : 63|1@1+ (1,0) [0|0] "" Vector__XXX
 SG_ DAS_TE_navCounter m4 : 5|3@1+ (1,0) [0|0] "" Vector__XXX
 SG_ DAS_TE_navC0 m4 : 8|10@1- (0.02,0) [0|0] "m" Vector__XXX
 SG_ DAS_TE_navC1 m4 : 18|9@1- (0.00195313,0) [0|0] "rad" Vector__XXX
 SG_ DAS_TE_navC2 m4 : 27|14@1- (4e-06,0) [0|0] "1/m" Vector__XXX
 SG_ DAS_TE_navC3 m4 : 41|14@1- (1.6e-08,0) [0|0] "1/m2" Vector__XXX
 SG_ DAS_TE_navQlty m4 : 55|1@1+ (1,0) [0|0] "" Vector__XXX
 SG_ DAS_TE_navRange m4 : 56|7@1+ (1,0) [0|0] "m" Vector__XXX
 SG_ DAS_TE_navFuse m4 : 63|1@1+ (1,0) [0|0] "" Vector__XXX
 SG_ DAS_TE_vlCounter m5 : 5|3@1+ (1,0) [0|0] "" Vector__XXX
 SG_ DAS_TE_vlC0 m5 : 8|10@1- (0.02,0) [0|0] "m" Vector__XXX
 SG_ DAS_TE_vlC1 m5 : 18|9@1- (0.00195313,0) [0|0] "rad" Vector__XXX
 SG_ DAS_TE_vlC2 m5 : 27|14@1- (4e-06,0) [0|0] "1/m" Vector__XXX
 SG_ DAS_TE_vlC3 m5 : 41|14@1- (1.6e-08,0) [0|0] "1/m2" Vector__XXX
 SG_ DAS_TE_vlQlty m5 : 55|1@1+ (1,0) [0|0] "" Vector__XXX
 SG_ DAS_TE_vlRange m5 : 56|7@1+ (1,0) [0|0] "m" Vector__XXX
 SG_ DAS_TE_vlFuse m5 : 63|1@1+ (1,0) [0|0] "" Vector__XXX
 SG_ DAS_TE_accCounter m6 : 5|3@1+ (1,0) [0|0] "" Vector__XXX
 SG_ DAS_TE_accTargetDx m6 : 8|6@1+ (2,0) [0|0] "m" Vector__XXX
 SG_ DAS_TE_accTargetDy m6 : 14|6@1+ (0.2,-6.4) [0|0] "m" Vector__XXX
 SG_ DAS_TE_accTargetRelVel m6 : 20|7@1- (0.25,-15.75) [0|0] "m/s" Vector__XXX
 SG_ DAS_TE_accTargetRelA m6 : 27|5@1- (0.5,-7.5) [0|0] "m/s^2" Vector__XXX
 SG_ DAS_TE_accMinAccel m6 : 32|5@1- (0.5,-7.5) [0|0] "m/s^2" Vector__XXX
 SG_ DAS_TE_accMinJ m6 : 37|5@1- (0.5,-7.5) [0|0] "m/s^3" Vector__XXX
 SG_ DAS_TE_fcmCounter m7 : 5|3@1+ (1,0) [0|0] "" Vector__XXX
 SG_ DAS_TE_fcmTargetDx m7 : 8|8@1+ (0.25,0) [0|0] "m" Vector__XXX
 SG_ DAS_TE_fcmTargetDy m7 : 16|5@1+ (0.2,-3.2) [0|0] "m" Vector__XXX
 SG_ DAS_TE_fcmTargetVRel m7 : 21|7@1+ (0.25,-31.75) [0|0] "m/s" Vector__XXX
 SG_ DAS_TE_fcmTargetAccel m7 : 28|5@1+ (0.5,-15.5) [0|0] "m/s^2" Vector__XXX
 SG_ DAS_TE_fcmTargetProb m7 : 33|5@1+ (5,0) [0|0] "%" Vector__XXX
 SG_ DAS_TE_fcmDecelReqInstant m7 : 38|7@1- (0.1,-6.3) [0|0] "m/s^2" Vector__XXX
 SG_ DAS_TE_fcmDecelReqAeb m7 : 45|7@1- (0.1,-6.3) [0|0] "m/s^2" Vector__XXX
 SG_ DAS_TE_meAebFlag m7 : 52|1@1+ (1,0) [0|0] "" Vector__XXX
 SG_ DAS_TE_ipsoCounter m8 : 5|3@1+ (1,0) [0|0] "" Vector__XXX
 SG_ DAS_TE_ipsoValid m8 : 8|1@1+ (1,0) [0|0] "" Vector__XXX
 SG_ DAS_TE_ipsoConfidence m8 : 9|7@1+ (1,0) [0|0] "" Vector__XXX
 SG_ DAS_TE_ipsoDx m8 : 16|6@1+ (2,0) [0|0] "m" Vector__XXX
 SG_ DAS_TE_ipsoDy m8 : 22|6@1+ (0.1,-3.2) [0|0] "m" Vector__XXX
 SG_ DAS_TE_vlDyAtIpsoDx m8 : 28|6@1+ (0.1,-3.2) [0|0] "m" Vector__XXX
 SG_ DAS_TE_swaProjection m8 : 34|6@1+ (0.1,-3.2) [0|0] "m" Vector__XXX
 SG_ DAS_TE_ipsoIsTarget1 m8 : 40|1@1+ (1,0) [0|0] "" Vector__XXX
 SG_ DAS_TE_ipsoIsTarget5 m8 : 41|1@1+ (1,0) [0|0] "" Vector__XXX
 SG_ DAS_TE_restrictedAccess m8 : 42|1@1+ (1,0) [0|0] "" Vector__XXX
 SG_ DAS_TE_csaOfframpValid m8 : 43|1@1+ (1,0) [0|0] "" Vector__XXX
 SG_ DAS_TE_accControlType m8 : 44|4@1+ (1,0) [0|0] "" Vector__XXX
 SG_ DAS_TE_brakeCapacityWarning m8 : 48|1@1+ (1,0) [0|0] "" Vector__XXX
 SG_ DAS_TE_emergencyBrake m8 : 49|1@1+ (1,0) [0|0] "" Vector__XXX
 SG_ DAS_TE_extendedAccLimits m8 : 50|1@1+ (1,0) [0|0] "" Vector__XXX
 SG_ DAS_TE_crashFront m8 : 51|1@1+ (1,0) [0|0] "" Vector__XXX
 SG_ DAS_TE_crashLeft m8 : 52|1@1+ (1,0) [0|0] "" Vector__XXX
 SG_ DAS_TE_crashRear m8 : 53|1@1+ (1,0) [0|0] "" Vector__XXX
 SG_ DAS_TE_crashRight m8 : 54|1@1+ (1,0) [0|0] "" Vector__XXX
 SG_ DAS_TE_crashRollover m8 : 55|1@1+ (1,0) [0|0] "" Vector__XXX
 SG_ DAS_TE_crashPedPro m8 : 56|1@1+ (1,0) [0|0] "" Vector__XXX
 SG_ DAS_TE_meIpsoValid m8 : 57|1@1+ (1,0) [0|0] "" Vector__XXX
 SG_ DAS_TE_robCounter m9 : 5|3@1+ (1,0) [0|0] "" Vector__XXX
 SG_ DAS_TE_robExceptionStart m9 : 16|8@1+ (1,-95) [0|0] "m" Vector__XXX
 SG_ DAS_TE_robExceptionEnd m9 : 24|8@1+ (1,0) [0|0] "m" Vector__XXX
 SG_ DAS_TE_robDistanceEllipse m9 : 32|8@1+ (0.5,0) [0|0] "m" Vector__XXX
 SG_ DAS_TE_robEllipseOverlap m9 : 40|8@1+ (0.1,-12.5) [0|0] "m" Vector__XXX
 SG_ DAS_TE_robEllipseAge m9 : 48|3@1+ (1,0) [0|0] "" Vector__XXX
 SG_ DAS_TE_robInfrastructure m9 : 51|1@1+ (1,0) [0|0] "" Vector__XXX
 SG_ DAS_TE_robTrustRadarMap m9 : 52|1@1+ (1,0) [0|0] "" Vector__XXX
 SG_ DAS_TE_robActiveBraking m9 : 53|1@1+ (1,0) [0|0] "" Vector__XXX

BO_ 990 FC_alertMatrix6: 8 VEH
 SG_ FC_a321_FCAlertPlaceholder : 0|1@1+ (1,0) [0|0] "" Vector__XXX

BO_ 994 VCLEFT_lightStatus: 7 VEH
 SG_ VCLEFT_FLMapLightStatus : 6|2@1+ (1,0) [0|3] "" Vector__XXX
 SG_ VCLEFT_FLMapLightSwitchPressed : 14|1@1+ (1,0) [0|1] "" Vector__XXX
 SG_ VCLEFT_FRMapLightStatus : 8|2@1+ (1,0) [0|3] "" Vector__XXX
 SG_ VCLEFT_FRMapLightSwitchPressed : 15|1@1+ (1,0) [0|1] "" Vector__XXX
 SG_ VCLEFT_RLMapLightStatus : 10|2@1+ (1,0) [0|3] "" Vector__XXX
 SG_ VCLEFT_RLMapLightSwitchPressed : 16|1@1+ (1,0) [0|1] "" Vector__XXX
 SG_ VCLEFT_RRMapLightStatus : 12|2@1+ (1,0) [0|3] "" Vector__XXX
 SG_ VCLEFT_RRMapLightSwitchPressed : 17|1@1+ (1,0) [0|1] "" Vector__XXX
 SG_ VCLEFT_brakeLightStatus : 0|2@1+ (1,0) [0|3] "" Vector__XXX
 SG_ VCLEFT_brakeTrailerLightStatus : 22|2@1+ (1,0) [0|3] "" Vector__XXX
 SG_ VCLEFT_dynamicBrakeLightStatus : 44|2@1+ (1,0) [0|2] "" Vector__XXX
 SG_ VCLEFT_fogTrailerLightStatus : 26|2@1+ (1,0) [0|3] "" Vector__XXX
 SG_ VCLEFT_frontRideHeight : 28|8@1- (1,0) [-127|127] "mm" Vector__XXX
 SG_ VCLEFT_leftTurnTrailerLightStatus : 18|2@1+ (1,0) [0|3] "" Vector__XXX
 SG_ VCLEFT_rearRideHeight : 36|8@1- (1,0) [-127|127] "mm" Vector__XXX
 SG_ VCLEFT_reverseTrailerLightStatus : 49|2@1+ (1,0) [0|3] "" Vector__XXX
 SG_ VCLEFT_rideHeightSensorFault : 48|1@1+ (1,0) [0|1] "" Vector__XXX
 SG_ VCLEFT_rightTrnTrailerLightStatus : 20|2@1+ (1,0) [0|3] "" Vector__XXX
 SG_ VCLEFT_tailLightStatus : 2|2@1+ (1,0) [0|3] "" Vector__XXX
 SG_ VCLEFT_tailTrailerLightStatus : 24|2@1+ (1,0) [0|3] "" Vector__XXX
 SG_ VCLEFT_trailerDetected : 46|2@1+ (1,0) [0|3] "" Vector__XXX
 SG_ VCLEFT_turnSignalStatus : 4|2@1+ (1,0) [0|3] "" Vector__XXX

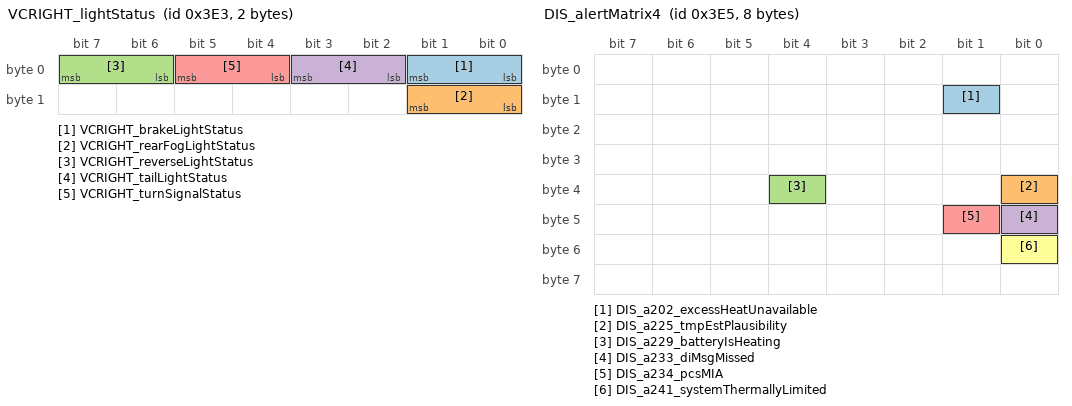
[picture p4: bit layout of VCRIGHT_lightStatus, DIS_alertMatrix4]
BO_ 995 VCRIGHT_lightStatus: 2 VEH
 SG_ VCRIGHT_brakeLightStatus : 0|2@1+ (1,0) [0|0] "" Vector__XXX
 SG_ VCRIGHT_rearFogLightStatus : 8|2@1+ (1,0) [0|0] "" Vector__XXX
 SG_ VCRIGHT_reverseLightStatus : 6|2@1+ (1,0) [0|0] "" Vector__XXX
 SG_ VCRIGHT_tailLightStatus : 2|2@1+ (1,0) [0|0] "" Vector__XXX
 SG_ VCRIGHT_turnSignalStatus : 4|2@1+ (1,0) [0|0] "" Vector__XXX

BO_ 997 DIS_alertMatrix4: 8 VEH
 SG_ DIS_a202_excessHeatUnavailable : 9|1@1+ (1,0) [0|0] "" Vector__XXX
 SG_ DIS_a225_tmpEstPlausibility : 32|1@1+ (1,0) [0|0] "" Vector__XXX
 SG_ DIS_a229_batteryIsHeating : 36|1@1+ (1,0) [0|0] "" Vector__XXX
 SG_ DIS_a233_diMsgMissed : 40|1@1+ (1,0) [0|0] "" Vector__XXX
 SG_ DIS_a234_pcsMIA : 41|1@1+ (1,0) [0|0] "" Vector__XXX
 SG_ DIS_a241_systemThermallyLimited : 48|1@1+ (1,0) [0|0] "" Vector__XXX

BO_ 1000 EPBR_alertMatrix: 8 VEH
 SG_ EPBR_matrixIndex M : 0|4@1+ (1,0) [0|0] "" Vector__XXX
 SG_ EPBR_a001_WatchdogReset m0 : 4|1@1+ (1,0) [0|0] "" Vector__XXX
 SG_ EPBR_a002_PowerLossReset m0 : 5|1@1+ (1,0) [0|0] "" Vector__XXX
 SG_ EPBR_a003_SWAssertion m0 : 6|1@1+ (1,0) [0|0] "" Vector__XXX
 SG_ EPBR_a010_ExtSupplyVoltError m0 : 13|1@1+ (1,0) [0|0] "" Vector__XXX
 SG_ EPBR_a012_CPUReset m0 : 15|1@1+ (1,0) [0|0] "" Vector__XXX
 SG_ EPBR_a013_AlertManagerFault m0 : 16|1@1+ (1,0) [0|0] "" Vector__XXX
 SG_ EPBR_a015_NVMMAlert m0 : 18|1@1+ (1,0) [0|0] "" Vector__XXX
 SG_ EPBR_a021_TaskSchedulerError m0 : 24|1@1+ (1,0) [0|0] "" Vector__XXX
 SG_ EPBR_a022_TaskInitError m0 : 25|1@1+ (1,0) [0|0] "" Vector__XXX
 SG_ EPBR_a031_UDSActive m0 : 34|1@1+ (1,0) [0|0] "" Vector__XXX
 SG_ EPBR_a041_HighCPULoad m0 : 44|1@1+ (1,0) [0|0] "" Vector__XXX
 SG_ EPBR_a042_HighStackUsage m0 : 45|1@1+ (1,0) [0|0] "" Vector__XXX
 SG_ EPBR_a043_Task1msError m0 : 46|1@1+ (1,0) [0|0] "" Vector__XXX
 SG_ EPBR_a044_Task10msError m0 : 47|1@1+ (1,0) [0|0] "" Vector__XXX
 SG_ EPBR_a045_Task100msError m0 : 48|1@1+ (1,0) [0|0] "" Vector__XXX
 SG_ EPBR_a046_Task1000msError m0 : 49|1@1+ (1,0) [0|0] "" Vector__XXX
 SG_ EPBR_a059_inputResistanceHigh m0 : 62|1@1+ (1,0) [0|0] "" Vector__XXX
 SG_ EPBR_a060_engineeringBuild m0 : 63|1@1+ (1,0) [0|0] "" Vector__XXX
 SG_ EPBR_a061_XCPConnected m1 : 4|1@1+ (1,0) [0|0] "" Vector__XXX
 SG_ EPBR_a062_XCPWasConnected m1 : 5|1@1+ (1,0) [0|0] "" Vector__XXX
 SG_ EPBR_a063_SwitchFault m1 : 6|1@1+ (1,0) [0|0] "" Vector__XXX
 SG_ EPBR_a064_busSleepReqTimeout m1 : 7|1@1+ (1,0) [0|0] "" Vector__XXX
 SG_ EPBR_a097_CMP_MIA m1 : 40|1@1+ (1,0) [0|0] "" Vector__XXX
 SG_ EPBR_a098_DI_THERMAL_MIA m1 : 41|1@1+ (1,0) [0|0] "" Vector__XXX
 SG_ EPBR_a099_PARK_MIA m1 : 42|1@1+ (1,0) [0|0] "" Vector__XXX
 SG_ EPBR_a100_CANbus_MIA m1 : 43|1@1+ (1,0) [0|0] "" Vector__XXX
 SG_ EPBR_a101_PM_MIA m1 : 44|1@1+ (1,0) [0|0] "" Vector__XXX
 SG_ EPBR_a102_PTC_MIA m1 : 45|1@1+ (1,0) [0|0] "" Vector__XXX
 SG_ EPBR_a103_CP_MIA m1 : 46|1@1+ (1,0) [0|0] "" Vector__XXX
 SG_ EPBR_a104_DAS_MIA m1 : 47|1@1+ (1,0) [0|0] "" Vector__XXX
 SG_ EPBR_a105_TAS_MIA m1 : 48|1@1+ (1,0) [0|0] "" Vector__XXX
 SG_ EPBR_a106_PCS_MIA m1 : 49|1@1+ (1,0) [0|0] "" Vector__XXX
 SG_ EPBR_a107_BMS_MIA m1 : 50|1@1+ (1,0) [0|0] "" Vector__XXX
 SG_ EPBR_a108_DIS_MIA m1 : 51|1@1+ (1,0) [0|0] "" Vector__XXX
 SG_ EPBR_a109_RCM_MIA m1 : 52|1@1+ (1,0) [0|0] "" Vector__XXX
 SG_ EPBR_a110_GTW_MIA m1 : 53|1@1+ (1,0) [0|0] "" Vector__XXX
 SG_ EPBR_a111_EPBR_MIA m1 : 54|1@1+ (1,0) [0|0] "" Vector__XXX
 SG_ EPBR_a112_EPBL_MIA m1 : 55|1@1+ (1,0) [0|0] "" Vector__XXX
 SG_ EPBR_a113_UI_MIA m1 : 56|1@1+ (1,0) [0|0] "" Vector__XXX
 SG_ EPBR_a114_ESP_MIA m1 : 57|1@1+ (1,0) [0|0] "" Vector__XXX
 SG_ EPBR_a115_VCSEC_MIA m1 : 58|1@1+ (1,0) [0|0] "" Vector__XXX
 SG_ EPBR_a116_VCRIGHT_MIA m1 : 59|1@1+ (1,0) [0|0] "" Vector__XXX
 SG_ EPBR_a117_VCLEFT_MIA m1 : 60|1@1+ (1,0) [0|0] "" Vector__XXX
 SG_ EPBR_a118_VCFRONT_MIA m1 : 61|1@1+ (1,0) [0|0] "" Vector__XXX
 SG_ EPBR_a119_SCCM_MIA m1 : 62|1@1+ (1,0) [0|0] "" Vector__XXX
 SG_ EPBR_a120_DI_DRIVE_MIA m1 : 63|1@1+ (1,0) [0|0] "" Vector__XXX
 SG_ EPBR_a121_nDriveFault m2 : 4|1@1+ (1,0) [0|0] "" Vector__XXX
 SG_ EPBR_a122_Oc m2 : 5|1@1+ (1,0) [0|0] "" Vector__XXX
 SG_ EPBR_a123_Uc m2 : 6|1@1+ (1,0) [0|0] "" Vector__XXX
 SG_ EPBR_a124_calOutOfBounds m2 : 7|1@1+ (1,0) [0|0] "" Vector__XXX
 SG_ EPBR_a125_IdleVMismatch m2 : 8|1@1+ (1,0) [0|0] "" Vector__XXX
 SG_ EPBR_a126_MotorNVoltLow m2 : 9|1@1+ (1,0) [0|0] "" Vector__XXX
 SG_ EPBR_a127_MotorNVoltHigh m2 : 10|1@1+ (1,0) [0|0] "" Vector__XXX
 SG_ EPBR_a128_MotorPVoltHigh m2 : 11|1@1+ (1,0) [0|0] "" Vector__XXX
 SG_ EPBR_a134_NvOv m2 : 17|1@1+ (1,0) [0|0] "" Vector__XXX
 SG_ EPBR_a135_NvUv m2 : 18|1@1+ (1,0) [0|0] "" Vector__XXX
 SG_ EPBR_a136_PvOv m2 : 19|1@1+ (1,0) [0|0] "" Vector__XXX
 SG_ EPBR_a137_PvUv m2 : 20|1@1+ (1,0) [0|0] "" Vector__XXX
 SG_ EPBR_a138_NVMWriteTime m2 : 21|1@1+ (1,0) [0|0] "" Vector__XXX
 SG_ EPBR_a141_invalidState m2 : 24|1@1+ (1,0) [0|0] "" Vector__XXX
 SG_ EPBR_a170_12vOv m2 : 53|1@1+ (1,0) [0|0] "" Vector__XXX
 SG_ EPBR_a171_12vUv m2 : 54|1@1+ (1,0) [0|0] "" Vector__XXX
 SG_ EPBR_a172_SPI_MIA m2 : 55|1@1+ (1,0) [0|0] "" Vector__XXX
 SG_ EPBR_a173_hiCurrentMissing m2 : 56|1@1+ (1,0) [0|0] "" Vector__XXX
 SG_ EPBR_a174_csmReleaseFailed m2 : 57|1@1+ (1,0) [0|0] "" Vector__XXX
 SG_ EPBR_a175_csmReleaseRetry m2 : 58|1@1+ (1,0) [0|0] "" Vector__XXX
 SG_ EPBR_a176_csmApplyFailed m2 : 59|1@1+ (1,0) [0|0] "" Vector__XXX
 SG_ EPBR_a177_csmApplyRetry m2 : 60|1@1+ (1,0) [0|0] "" Vector__XXX
 SG_ EPBR_a178_caliperStateUnknown m2 : 61|1@1+ (1,0) [0|0] "" Vector__XXX
 SG_ EPBR_a179_epbProblem m2 : 62|1@1+ (1,0) [0|0] "" Vector__XXX
 SG_ EPBR_a180_dynamicActive m2 : 63|1@1+ (1,0) [0|0] "" Vector__XXX
 SG_ EPBR_a181_TooSteepGradeToPark m3 : 4|1@1+ (1,0) [0|0] "" Vector__XXX
 SG_ EPBR_a182_OneEPBAppliedUnsecEnv m3 : 5|1@1+ (1,0) [0|0] "" Vector__XXX
 SG_ EPBR_a183_cdpNotAvailable m3 : 6|1@1+ (1,0) [0|0] "" Vector__XXX
 SG_ EPBR_a184_dynamicParkAbort m3 : 7|1@1+ (1,0) [0|0] "" Vector__XXX
 SG_ EPBR_a185_summonAborted m3 : 8|1@1+ (1,0) [0|0] "" Vector__XXX
 SG_ EPBR_a186_externalParkAbort m3 : 9|1@1+ (1,0) [0|0] "" Vector__XXX
 SG_ EPBR_a187_cdpDynamic m3 : 10|1@1+ (1,0) [0|0] "" Vector__XXX
 SG_ EPBR_a188_epbDynamic m3 : 11|1@1+ (1,0) [0|0] "" Vector__XXX
 SG_ EPBR_a189_epbDynamicParkCanceled m3 : 12|1@1+ (1,0) [0|0] "" Vector__XXX
 SG_ EPBR_a190_csmApplyDegraded m3 : 13|1@1+ (1,0) [0|0] "" Vector__XXX
 SG_ EPBR_a191_csmReleaseDegraded m3 : 14|1@1+ (1,0) [0|0] "" Vector__XXX
 SG_ EPBR_a195_parkForDriverIsLeaving m3 : 18|1@1+ (1,0) [0|0] "" Vector__XXX
 SG_ EPBR_a200_PmUnparkNotAllowed m3 : 23|1@1+ (1,0) [0|0] "" Vector__XXX
 SG_ EPBR_a201_hwBrakeTypeMismatch m3 : 24|1@1+ (1,0) [0|0] "" Vector__XXX
 SG_ EPBR_a216_SPI_MIA_debugData1 m3 : 39|1@1+ (1,0) [0|0] "" Vector__XXX
 SG_ EPBR_a217_SPI_MIA_debugData2 m3 : 40|1@1+ (1,0) [0|0] "" Vector__XXX
 SG_ EPBR_a241_diOutputLocked m4 : 4|1@1+ (1,0) [0|0] "" Vector__XXX
 SG_ EPBR_a242_hvOutputLocked m4 : 5|1@1+ (1,0) [0|0] "" Vector__XXX
 SG_ EPBR_a243_bdwUnavailable m4 : 6|1@1+ (1,0) [0|0] "" Vector__XXX
 SG_ EPBR_a244_WinchModeActive m4 : 7|1@1+ (1,0) [0|0] "" Vector__XXX
 SG_ EPBR_a245_serviceModeActive m4 : 8|1@1+ (1,0) [0|0] "" Vector__XXX
 SG_ EPBR_a246_idleFaultApply m4 : 9|1@1+ (1,0) [0|0] "" Vector__XXX
 SG_ EPBR_a247_csmDynamicApplyRetry m4 : 10|1@1+ (1,0) [0|0] "" Vector__XXX
 SG_ EPBR_a248_csmDynamicApplyFailed m4 : 11|1@1+ (1,0) [0|0] "" Vector__XXX
 SG_ EPBR_a249_idleFaultRelease m4 : 12|1@1+ (1,0) [0|0] "" Vector__XXX
 SG_ EPBR_a250_WinchModeCanceled m4 : 13|1@1+ (1,0) [0|0] "" Vector__XXX
 SG_ EPBR_a251_currentVarianceHigh m4 : 14|1@1+ (1,0) [0|0] "" Vector__XXX

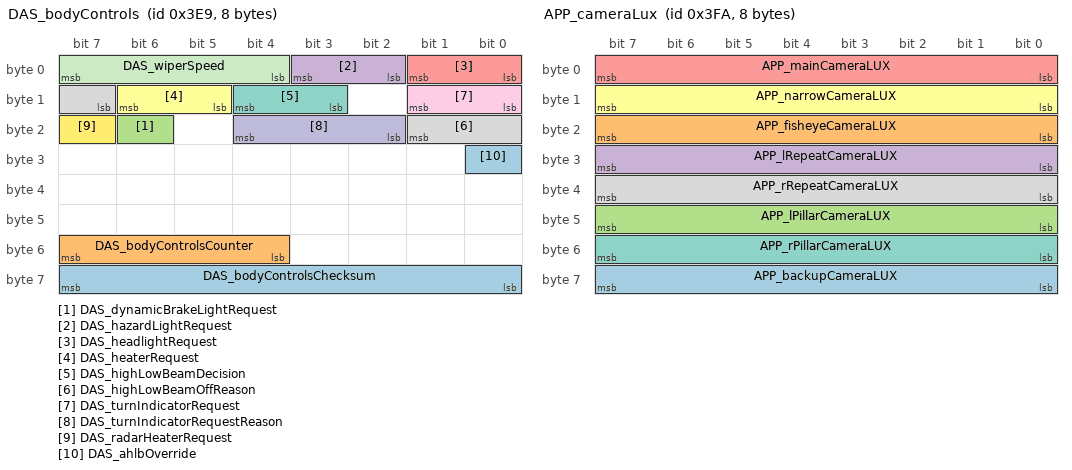
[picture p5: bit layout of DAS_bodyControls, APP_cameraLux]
BO_ 1001 DAS_bodyControls: 8 VEH
 SG_ DAS_bodyControlsChecksum : 56|8@1+ (1,0) [0|0] "" Vector__XXX
 SG_ DAS_bodyControlsCounter : 52|4@1+ (1,0) [0|0] "" Vector__XXX
 SG_ DAS_dynamicBrakeLightRequest : 22|1@1+ (1,0) [0|1] "" Vector__XXX
 SG_ DAS_hazardLightRequest : 2|2@1+ (1,0) [0|0] "" Vector__XXX
 SG_ DAS_headlightRequest : 0|2@1+ (1,0) [0|0] "" Vector__XXX
 SG_ DAS_heaterRequest : 13|2@1+ (1,0) [0|2] "" Vector__XXX
 SG_ DAS_highLowBeamDecision : 11|2@1+ (1,0) [0|0] "" Vector__XXX
 SG_ DAS_highLowBeamOffReason : 15|3@1+ (1,0) [0|0] "" Vector__XXX
 SG_ DAS_turnIndicatorRequest : 8|2@1+ (1,0) [0|0] "" Vector__XXX
 SG_ DAS_turnIndicatorRequestReason : 18|3@1+ (1,0) [0|0] "" Vector__XXX
 SG_ DAS_wiperSpeed : 4|4@1+ (1,0) [0|0] "" Vector__XXX
 SG_ DAS_radarHeaterRequest : 23|1@1+ (1,0) [0|1] "" Vector__XXX
 SG_ DAS_ahlbOverride : 24|1@1+ (1,0) [0|1] "" Vector__XXX

BO_ 1009 VCFRONT_lighting: 8 VEH
 SG_ VCFRONT_DRLLeftStatus : 36|2@1+ (1,0) [0|0] "" Vector__XXX
 SG_ VCFRONT_DRLRightStatus : 38|2@1+ (1,0) [0|0] "" Vector__XXX
 SG_ VCFRONT_ambientLightingBrightnes : 8|8@1+ (0.5,0) [0|0] "%" Vector__XXX
 SG_ VCFRONT_approachLightingRequest : 25|1@1+ (1,0) [0|0] "" Vector__XXX
 SG_ VCFRONT_courtesyLightingRequest : 24|1@1+ (1,0) [0|0] "" Vector__XXX
 SG_ VCFRONT_fogLeftStatus : 40|2@1+ (1,0) [0|0] "" Vector__XXX
 SG_ VCFRONT_fogRightStatus : 42|2@1+ (1,0) [0|0] "" Vector__XXX
 SG_ VCFRONT_hazardLightRequest : 4|3@1+ (1,0) [0|0] "" Vector__XXX
 SG_ VCFRONT_hazardSwitchBacklight : 27|1@1+ (1,0) [0|0] "" Vector__XXX
 SG_ VCFRONT_highBeamLeftStatus : 32|2@1+ (1,0) [0|0] "" Vector__XXX
 SG_ VCFRONT_highBeamRightStatus : 34|2@1+ (1,0) [0|0] "" Vector__XXX
 SG_ VCFRONT_highBeamSwitchActive : 58|1@1+ (1,0) [0|0] "" Vector__XXX
 SG_ VCFRONT_indicatorLeftRequest : 0|2@1+ (1,0) [0|0] "" Vector__XXX
 SG_ VCFRONT_indicatorRightRequest : 2|2@1+ (1,0) [0|0] "" Vector__XXX
 SG_ VCFRONT_lowBeamLeftStatus : 28|2@1+ (1,0) [0|0] "" Vector__XXX
 SG_ VCFRONT_lowBeamRightStatus : 30|2@1+ (1,0) [0|0] "" Vector__XXX
 SG_ VCFRONT_lowBeamsCalibrated : 62|1@1+ (1,0) [0|0] "" Vector__XXX
 SG_ VCFRONT_lowBeamsOnForDRL : 61|1@1+ (1,0) [0|0] "" Vector__XXX
 SG_ VCFRONT_parkLeftStatus : 54|2@1+ (1,0) [0|0] "" Vector__XXX
 SG_ VCFRONT_parkRightStatus : 56|2@1+ (1,0) [0|0] "" Vector__XXX
 SG_ VCFRONT_seeYouHomeLightingReq : 26|1@1+ (1,0) [0|0] "" Vector__XXX
 SG_ VCFRONT_sideMarkersStatus : 44|2@1+ (1,0) [0|0] "" Vector__XXX
 SG_ VCFRONT_sideRepeaterLeftStatus : 46|2@1+ (1,0) [0|0] "" Vector__XXX
 SG_ VCFRONT_sideRepeaterRightStatus : 48|2@1+ (1,0) [0|0] "" Vector__XXX
 SG_ VCFRONT_simLatchingStalk : 59|2@1+ (1,0) [0|0] "" Vector__XXX
 SG_ VCFRONT_switchLightingBrightness : 16|8@1+ (0.5,0) [0|0] "%" Vector__XXX
 SG_ VCFRONT_turnSignalLeftStatus : 50|2@1+ (1,0) [0|0] "" Vector__XXX
 SG_ VCFRONT_turnSignalRightStatus : 52|2@1+ (1,0) [0|0] "" Vector__XXX

BO_ 1010 ID3F2BMSCounters: 8 VehicleBus
 SG_ BMS_kwhCounter_Id M : 0|4@1+ (1,0) [0|0] ""   X
 SG_ BMS_kwhDcChargeTotalModule3 m9 : 36|28@1+ (0.001,0) [0|0] "KWh"   X
 SG_ BMS_kwhChargeTotalModule2 m6 : 36|28@1+ (0.001,0) [0|0] "KWh"   X
 SG_ BMS_kwhDcChargeTotalModule2 m7 : 36|28@1+ (0.001,0) [0|0] "KWh"   X
 SG_ BMS_kwhChargeTotalModule4 m10 : 36|28@1+ (0.001,0) [0|0] "KWh"   X
 SG_ BMS_kwhDcChargeTotalModule4 m11 : 36|28@1+ (0.001,0) [0|0] "KWh"   X
 SG_ BMS_kwhDcChargeTotalModule1 m5 : 36|28@1+ (0.001,0) [0|0] "KWh"   X
 SG_ BMS_kwhChargeTotalModule1 m4 : 36|28@1+ (0.001,0) [0|0] "KWh"   X
 SG_ BMS_kwhChargeTotalModule3 m8 : 36|28@1+ (0.001,0) [0|0] "KWh"   X
 SG_ BMS_kwhAcChargeTotalModule3 m9 : 8|28@1- (0.001,0) [0|0] "KWh"   X
 SG_ BMS_kwhDischargeTotalModule2 m6 : 8|28@1- (0.001,0) [0|0] "KWh"   X
 SG_ BMS_kwhAcChargeTotalModule2 m7 : 8|28@1- (0.001,0) [0|0] "KWh"   X
 SG_ BMS_kwhDischargeTotalModule4 m10 : 8|28@1- (0.001,0) [0|0] "KWh"   X
 SG_ BMS_kwhAcChargeTotalModule4 m11 : 8|28@1- (0.001,0) [0|0] "KWh"   X
 SG_ BMS_kwhAcChargeTotalModule1 m5 : 8|28@1- (0.001,0) [0|0] "KWh"   X
 SG_ BMS_kwhDriveDischargeTotal m3 : 8|32@1+ (0.001,0) [0|0] "KWh"   X
 SG_ BMS_dcChargerKwhTotal m1 : 8|32@1+ (0.001,0) [0|0] "KWh"   X
 SG_ BMS_kwhDischargeTotalModule1 m4 : 8|28@1- (0.001,0) [0|0] "KWh"   X
 SG_ BMS_acChargerKwhTotal m0 : 8|32@1+ (0.001,0) [0|0] "KWh"   X
 SG_ BMS_kwhRegenChargeTotal m2 : 8|32@1+ (0.001,0) [0|0] "KWh"   X
 SG_ BMS_kwhDischargeTotalModule3 m8 : 8|28@1- (0.001,0) [0|0] "KWh"   X

BO_ 1011 UI_odo: 3 CH
 SG_ UI_odometer : 0|24@1+ (0.1,0) [0|0] "km" Vector__XXX

BO_ 1012 APP_camCalibrationStatus: 6 CH
 SG_ APP_cameraPosition M : 0|4@1+ (1,0) [0|0] "" Vector__XXX
 SG_ APP_mainCamExtPitchCal m1 : 8|9@1+ (0.05,-12.5) [0|0] "deg" Vector__XXX
 SG_ APP_mainCamExtYawCal m1 : 17|9@1+ (0.05,-12.5) [0|0] "deg" Vector__XXX
 SG_ APP_mainCalibTime m1 : 26|7@1+ (1,0) [0|0] "min" Vector__XXX
 SG_ APP_mainCalibProgress m1 : 33|7@1+ (1,0) [0|0] "percent" Vector__XXX
 SG_ APP_mainCalibrated m1 : 40|1@1+ (1,0) [0|0] "" Vector__XXX
 SG_ APP_narrowCamExtPitchCal m2 : 8|9@1+ (0.05,-12.5) [0|0] "deg" Vector__XXX
 SG_ APP_narrowCamExtYawCal m2 : 17|9@1+ (0.05,-12.5) [0|0] "deg" Vector__XXX
 SG_ APP_narrowCalibTime m2 : 26|7@1+ (1,0) [0|0] "min" Vector__XXX
 SG_ APP_narrowCalibProgress m2 : 33|7@1+ (1,0) [0|0] "percent" Vector__XXX
 SG_ APP_narrowCalibrated m2 : 40|1@1+ (1,0) [0|0] "" Vector__XXX
 SG_ APP_fisheyeCamExtPitchCal m3 : 8|9@1+ (0.05,-12.5) [0|0] "deg" Vector__XXX
 SG_ APP_fisheyeCamExtYawCal m3 : 17|9@1+ (0.05,-12.5) [0|0] "deg" Vector__XXX
 SG_ APP_fisheyeCalibTime m3 : 26|7@1+ (1,0) [0|0] "min" Vector__XXX
 SG_ APP_fisheyeCalibProgress m3 : 33|7@1+ (1,0) [0|0] "percent" Vector__XXX
 SG_ APP_fisheyeCalibrated m3 : 40|1@1+ (1,0) [0|0] "" Vector__XXX
 SG_ APP_lPillarCamExtPitchCal m4 : 8|9@1+ (0.05,-12.5) [0|0] "deg" Vector__XXX
 SG_ APP_lPillarCamExtYawCal m4 : 17|9@1+ (0.05,-12.5) [0|0] "deg" Vector__XXX
 SG_ APP_lPillarCalibTime m4 : 26|7@1+ (1,0) [0|0] "min" Vector__XXX
 SG_ APP_lPillarCalibProgress m4 : 33|7@1+ (1,0) [0|0] "percent" Vector__XXX
 SG_ APP_lPillarCalibrated m4 : 40|1@1+ (1,0) [0|0] "" Vector__XXX
 SG_ APP_rPillarCamExtPitchCal m5 : 8|9@1+ (0.05,-12.5) [0|0] "deg" Vector__XXX
 SG_ APP_rPillarCamExtYawCal m5 : 17|9@1+ (0.05,-12.5) [0|0] "deg" Vector__XXX
 SG_ APP_rPillarCalibTime m5 : 26|7@1+ (1,0) [0|0] "min" Vector__XXX
 SG_ APP_rPillarCalibProgress m5 : 33|7@1+ (1,0) [0|0] "percent" Vector__XXX
 SG_ APP_rPillarCalibrated m5 : 40|1@1+ (1,0) [0|0] "" Vector__XXX
 SG_ APP_lRepeatCamExtPitchCal m6 : 8|9@1+ (0.05,-12.5) [0|0] "deg" Vector__XXX
 SG_ APP_lRepeatCamExtYawCal m6 : 17|9@1+ (0.05,-12.5) [0|0] "deg" Vector__XXX
 SG_ APP_lRepeatCalibTime m6 : 26|7@1+ (1,0) [0|0] "min" Vector__XXX
 SG_ APP_lRepeatCalibProgress m6 : 33|7@1+ (1,0) [0|0] "percent" Vector__XXX
 SG_ APP_lRepeatCalibrated m6 : 40|1@1+ (1,0) [0|0] "" Vector__XXX
 SG_ APP_rRepeatCamExtPitchCal m7 : 8|9@1+ (0.05,-12.5) [0|0] "deg" Vector__XXX
 SG_ APP_rRepeatCamExtYawCal m7 : 17|9@1+ (0.05,-12.5) [0|0] "deg" Vector__XXX
 SG_ APP_rRepeatCalibTime m7 : 26|7@1+ (1,0) [0|0] "min" Vector__XXX
 SG_ APP_rRepeatCalibProgress m7 : 33|7@1+ (1,0) [0|0] "percent" Vector__XXX
 SG_ APP_rRepeatCalibrated m7 : 40|1@1+ (1,0) [0|0] "" Vector__XXX
 SG_ APP_backupCamExtPitchCal m8 : 8|9@1+ (0.05,-12.5) [0|0] "deg" Vector__XXX
 SG_ APP_backupCamExtYawCal m8 : 17|9@1+ (0.05,-12.5) [0|0] "deg" Vector__XXX
 SG_ APP_backupCalibTime m8 : 26|7@1+ (1,0) [0|0] "min" Vector__XXX
 SG_ APP_backupCalibProgress m8 : 33|7@1+ (1,0) [0|0] "percent" Vector__XXX
 SG_ APP_backupCalibrated m8 : 40|1@1+ (1,0) [0|0] "" Vector__XXX

BO_ 1013 ID3F5VCFRONT_lighting: 8 VehicleBus
 SG_ VCFRONT_DRLLeftStatus : 36|2@1+ (1,0) [0|3] ""   X
 SG_ VCFRONT_DRLRightStatus : 38|2@1+ (1,0) [0|3] ""   X
 SG_ VCFRONT_ambientLightingBrightnes : 8|8@1+ (0.5,0) [0|127] "%"   X
 SG_ VCFRONT_approachLightingRequest : 25|1@1+ (1,0) [0|1] ""   X
 SG_ VCFRONT_courtesyLightingRequest : 24|1@1+ (1,0) [0|1] ""   X
 SG_ VCFRONT_fogLeftStatus : 40|2@1+ (1,0) [0|3] ""   X
 SG_ VCFRONT_fogRightStatus : 42|2@1+ (1,0) [0|3] ""   X
 SG_ VCFRONT_hazardLightRequest : 4|4@1+ (1,0) [0|8] ""   X
 SG_ VCFRONT_hazardSwitchBacklight : 27|1@1+ (1,0) [0|1] ""   X
 SG_ VCFRONT_highBeamLeftStatus : 32|2@1+ (1,0) [0|3] ""   X
 SG_ VCFRONT_highBeamRightStatus : 34|2@1+ (1,0) [0|3] ""   X
 SG_ VCFRONT_highBeamSwitchActive : 58|1@1+ (1,0) [0|1] ""   X
 SG_ VCFRONT_indicatorLeftRequest : 0|2@1+ (1,0) [0|2] ""   X
 SG_ VCFRONT_indicatorRightRequest : 2|2@1+ (1,0) [0|2] ""   X
 SG_ VCFRONT_lowBeamLeftStatus : 28|2@1+ (1,0) [0|3] ""   X
 SG_ VCFRONT_lowBeamRightStatus : 30|2@1+ (1,0) [0|3] ""   X
 SG_ VCFRONT_lowBeamsCalibrated : 62|1@1+ (1,0) [0|1] ""   X
 SG_ VCFRONT_lowBeamsOnForDRL : 61|1@1+ (1,0) [0|1] ""   X
 SG_ VCFRONT_parkLeftStatus : 54|2@1+ (1,0) [0|3] ""   X
 SG_ VCFRONT_parkRightStatus : 56|2@1+ (1,0) [0|3] ""   X
 SG_ VCFRONT_seeYouHomeLightingReq : 26|1@1+ (1,0) [0|1] ""   X
 SG_ VCFRONT_sideMarkersStatus : 44|2@1+ (1,0) [0|3] ""   X
 SG_ VCFRONT_sideRepeaterLeftStatus : 46|2@1+ (1,0) [0|3] ""   X
 SG_ VCFRONT_sideRepeaterRightStatus : 48|2@1+ (1,0) [0|3] ""   X
 SG_ VCFRONT_simLatchingStalk : 59|2@1+ (1,0) [0|3] ""   X
 SG_ VCFRONT_switchLightingBrightness : 16|8@1+ (0.5,0) [0|127] "%"   X
 SG_ VCFRONT_turnSignalLeftStatus : 50|2@1+ (1,0) [0|3] ""   X
 SG_ VCFRONT_turnSignalRightStatus : 52|2@1+ (1,0) [0|3] ""   X

BO_ 1016 UI_driverAssistControl: 8 CH
 SG_ UI_accFollowDistanceSetting : 45|3@1+ (1,0) [0|0] "" Vector__XXX
 SG_ UI_accFromZero : 55|1@1+ (1,0) [0|0] "" Vector__XXX
 SG_ UI_adaptiveSetSpeedEnable : 39|1@1+ (1,0) [0|0] "" Vector__XXX
 SG_ UI_alcOffHighwayEnable : 56|1@1+ (1,0) [0|0] "" Vector__XXX
 SG_ UI_autoSummonEnable : 10|1@1+ (1,0) [0|0] "" Vector__XXX
 SG_ UI_autopilotAlwaysOn : 54|1@1+ (1,0) [0|0] "" Vector__XXX
 SG_ UI_autopilotControlRequest : 0|1@1+ (1,0) [0|0] "" Vector__XXX
 SG_ UI_curvSpeedAdaptDisable : 4|1@1+ (1,0) [0|0] "" Vector__XXX
 SG_ UI_curvatureDatabaseOnly : 22|1@1+ (1,0) [0|0] "" Vector__XXX
 SG_ UI_dasDeveloper : 5|1@1+ (1,0) [0|0] "" Vector__XXX
 SG_ UI_driveOnMapsEnable : 13|1@1+ (1,0) [0|0] "" Vector__XXX
 SG_ UI_drivingSide : 40|2@1+ (1,0) [0|0] "" Vector__XXX
 SG_ UI_enableClipTelemetry : 42|1@1+ (1,0) [0|0] "" Vector__XXX
 SG_ UI_enableCutinExperiments : 59|1@1+ (1,0) [0|0] "" Vector__XXX
 SG_ UI_enableNavRouteCSA : 58|1@1+ (1,0) [0|0] "" Vector__XXX
 SG_ UI_enableNextGenACC : 19|1@1+ (1,0) [0|0] "" Vector__XXX
 SG_ UI_enableRoadSegmentTelemetry : 44|1@1+ (1,0) [0|0] "" Vector__XXX
 SG_ UI_enableTripTelemetry : 43|1@1+ (1,0) [0|0] "" Vector__XXX
 SG_ UI_enableVinAssociation : 6|1@1+ (1,0) [0|0] "" Vector__XXX
 SG_ UI_enableVisionOnlyStops : 60|1@1+ (1,0) [0|0] "" Vector__XXX
 SG_ UI_exceptionListEnable : 11|1@1+ (1,0) [0|0] "" Vector__XXX
 SG_ UI_followNavRouteEnable : 49|1@1+ (1,0) [0|0] "" Vector__XXX
 SG_ UI_forksEnable : 63|1@1+ (1,0) [0|0] "" Vector__XXX
 SG_ UI_fuseHPPDisable : 17|1@1+ (1,0) [0|0] "" Vector__XXX
 SG_ UI_fuseLanesDisable : 16|1@1+ (1,0) [0|0] "" Vector__XXX
 SG_ UI_fuseVehiclesDisable : 18|1@1+ (1,0) [0|0] "" Vector__XXX
 SG_ UI_handsOnRequirementDisable : 14|1@1+ (1,0) [0|0] "" Vector__XXX
 SG_ UI_lssElkEnabled : 23|1@1+ (1,0) [0|0] "" Vector__XXX
 SG_ UI_lssLdwEnabled : 8|1@1+ (1,0) [0|0] "" Vector__XXX
 SG_ UI_lssLkaEnabled : 7|1@1+ (1,0) [0|0] "" Vector__XXX
 SG_ UI_roadCheckDisable : 12|1@1+ (1,0) [0|0] "" Vector__XXX
 SG_ UI_selfParkRequest : 28|4@1+ (1,0) [0|0] "" Vector__XXX
 SG_ UI_source3D : 61|2@1+ (1,0) [0|0] "" Vector__XXX
 SG_ UI_summonEntryType : 26|2@1+ (1,0) [0|0] "" Vector__XXX
 SG_ UI_summonExitType : 24|2@1+ (1,0) [0|0] "" Vector__XXX
 SG_ UI_summonHeartbeat : 2|2@1+ (1,0) [0|0] "" Vector__XXX
 SG_ UI_summonReverseDist : 32|6@1+ (1,0) [0|0] "" Vector__XXX
 SG_ UI_ulcBlindSpotConfig : 52|2@1+ (1,0) [0|0] "" Vector__XXX
 SG_ UI_ulcOffHighway : 15|1@1+ (1,0) [0|0] "" Vector__XXX
 SG_ UI_ulcSpeedConfig : 50|2@1+ (1,0) [0|0] "" Vector__XXX
 SG_ UI_ulcStalkConfirm : 1|1@1+ (1,0) [0|0] "" Vector__XXX
 SG_ UI_undertakeAssistEnable : 38|1@1+ (1,0) [0|0] "" Vector__XXX
 SG_ UI_validationLoop : 57|1@1+ (1,0) [0|0] "" Vector__XXX
 SG_ UI_visionSpeedType : 20|2@1+ (1,0) [0|0] "" Vector__XXX

BO_ 1017 VCSEC_alertMatrix: 8 VEH
 SG_ VCSEC_matrixIndex M : 0|4@1+ (1,0) [0|0] "" Vector__XXX
 SG_ VCSEC_a001_WatchdogReset m0 : 4|1@1+ (1,0) [0|0] "" Vector__XXX
 SG_ VCSEC_a002_PowerLossReset m0 : 5|1@1+ (1,0) [0|0] "" Vector__XXX
 SG_ VCSEC_a003_SWAssertion m0 : 6|1@1+ (1,0) [0|0] "" Vector__XXX
 SG_ VCSEC_a010_ExtSupplyVoltError m0 : 13|1@1+ (1,0) [0|0] "" Vector__XXX
 SG_ VCSEC_a012_CPUReset m0 : 15|1@1+ (1,0) [0|0] "" Vector__XXX
 SG_ VCSEC_a013_AlertManagerFault m0 : 16|1@1+ (1,0) [0|0] "" Vector__XXX
 SG_ VCSEC_a015_NVMMAlert m0 : 18|1@1+ (1,0) [0|0] "" Vector__XXX
 SG_ VCSEC_a021_TaskSchedulerError m0 : 24|1@1+ (1,0) [0|0] "" Vector__XXX
 SG_ VCSEC_a022_TaskInitError m0 : 25|1@1+ (1,0) [0|0] "" Vector__XXX
 SG_ VCSEC_a031_UDSActive m0 : 34|1@1+ (1,0) [0|0] "" Vector__XXX
 SG_ VCSEC_a041_HighCPULoad m0 : 44|1@1+ (1,0) [0|0] "" Vector__XXX
 SG_ VCSEC_a042_HighStackUsage m0 : 45|1@1+ (1,0) [0|0] "" Vector__XXX
 SG_ VCSEC_a043_Task1msError m0 : 46|1@1+ (1,0) [0|0] "" Vector__XXX
 SG_ VCSEC_a044_Task10msError m0 : 47|1@1+ (1,0) [0|0] "" Vector__XXX
 SG_ VCSEC_a045_Task100msError m0 : 48|1@1+ (1,0) [0|0] "" Vector__XXX
 SG_ VCSEC_a046_Task1000msError m0 : 49|1@1+ (1,0) [0|0] "" Vector__XXX
 SG_ VCSEC_a059_inputResistanceHigh m0 : 62|1@1+ (1,0) [0|0] "" Vector__XXX
 SG_ VCSEC_a060_engineeringBuild m0 : 63|1@1+ (1,0) [0|0] "" Vector__XXX
 SG_ VCSEC_a061_XCPConnected m1 : 4|1@1+ (1,0) [0|0] "" Vector__XXX
 SG_ VCSEC_a062_XCPWasConnected m1 : 5|1@1+ (1,0) [0|0] "" Vector__XXX
 SG_ VCSEC_a063_SwitchFault m1 : 6|1@1+ (1,0) [0|0] "" Vector__XXX
 SG_ VCSEC_a064_busSleepReqTimeout m1 : 7|1@1+ (1,0) [0|0] "" Vector__XXX
 SG_ VCSEC_a097_CMP_MIA m1 : 40|1@1+ (1,0) [0|0] "" Vector__XXX
 SG_ VCSEC_a098_DI_THERMAL_MIA m1 : 41|1@1+ (1,0) [0|0] "" Vector__XXX
 SG_ VCSEC_a099_PARK_MIA m1 : 42|1@1+ (1,0) [0|0] "" Vector__XXX
 SG_ VCSEC_a100_CANbus_MIA m1 : 43|1@1+ (1,0) [0|0] "" Vector__XXX
 SG_ VCSEC_a101_PM_MIA m1 : 44|1@1+ (1,0) [0|0] "" Vector__XXX
 SG_ VCSEC_a102_PTC_MIA m1 : 45|1@1+ (1,0) [0|0] "" Vector__XXX
 SG_ VCSEC_a103_CP_MIA m1 : 46|1@1+ (1,0) [0|0] "" Vector__XXX
 SG_ VCSEC_a104_DAS_MIA m1 : 47|1@1+ (1,0) [0|0] "" Vector__XXX
 SG_ VCSEC_a105_TAS_MIA m1 : 48|1@1+ (1,0) [0|0] "" Vector__XXX
 SG_ VCSEC_a106_PCS_MIA m1 : 49|1@1+ (1,0) [0|0] "" Vector__XXX
 SG_ VCSEC_a107_BMS_MIA m1 : 50|1@1+ (1,0) [0|0] "" Vector__XXX
 SG_ VCSEC_a108_DIS_MIA m1 : 51|1@1+ (1,0) [0|0] "" Vector__XXX
 SG_ VCSEC_a109_RCM_MIA m1 : 52|1@1+ (1,0) [0|0] "" Vector__XXX
 SG_ VCSEC_a110_GTW_MIA m1 : 53|1@1+ (1,0) [0|0] "" Vector__XXX
 SG_ VCSEC_a111_EPBR_MIA m1 : 54|1@1+ (1,0) [0|0] "" Vector__XXX
 SG_ VCSEC_a112_EPBL_MIA m1 : 55|1@1+ (1,0) [0|0] "" Vector__XXX
 SG_ VCSEC_a113_UI_MIA m1 : 56|1@1+ (1,0) [0|0] "" Vector__XXX
 SG_ VCSEC_a114_ESP_MIA m1 : 57|1@1+ (1,0) [0|0] "" Vector__XXX
 SG_ VCSEC_a115_VCSEC_MIA m1 : 58|1@1+ (1,0) [0|0] "" Vector__XXX
 SG_ VCSEC_a116_VCRIGHT_MIA m1 : 59|1@1+ (1,0) [0|0] "" Vector__XXX
 SG_ VCSEC_a117_VCLEFT_MIA m1 : 60|1@1+ (1,0) [0|0] "" Vector__XXX
 SG_ VCSEC_a118_VCFRONT_MIA m1 : 61|1@1+ (1,0) [0|0] "" Vector__XXX
 SG_ VCSEC_a119_SCCM_MIA m1 : 62|1@1+ (1,0) [0|0] "" Vector__XXX
 SG_ VCSEC_a120_DI_DRIVE_MIA m1 : 63|1@1+ (1,0) [0|0] "" Vector__XXX
 SG_ VCSEC_a133_alarmTriggered m2 : 16|1@1+ (1,0) [0|0] "" Vector__XXX
 SG_ VCSEC_a134_badCertificate m2 : 17|1@1+ (1,0) [0|0] "" Vector__XXX
 SG_ VCSEC_a135_centerEndpointMIA m2 : 18|1@1+ (1,0) [0|0] "" Vector__XXX
 SG_ VCSEC_a136_leftEndpointMIA m2 : 19|1@1+ (1,0) [0|0] "" Vector__XXX
 SG_ VCSEC_a137_rightEndpointMIA m2 : 20|1@1+ (1,0) [0|0] "" Vector__XXX
 SG_ VCSEC_a138_rearEndpointMIA m2 : 21|1@1+ (1,0) [0|0] "" Vector__XXX
 SG_ VCSEC_a140_nfcAuthentication m2 : 23|1@1+ (1,0) [0|0] "" Vector__XXX
 SG_ VCSEC_a141_tooFewKeysOnWhitelist m2 : 24|1@1+ (1,0) [0|0] "" Vector__XXX
 SG_ VCSEC_a142_bleGattAlertC m2 : 25|1@1+ (1,0) [0|0] "" Vector__XXX
 SG_ VCSEC_a143_bleGattAlertL m2 : 26|1@1+ (1,0) [0|0] "" Vector__XXX
 SG_ VCSEC_a144_bleGattAlertR m2 : 27|1@1+ (1,0) [0|0] "" Vector__XXX
 SG_ VCSEC_a145_bleGattAlertRe m2 : 28|1@1+ (1,0) [0|0] "" Vector__XXX
 SG_ VCSEC_a147_protobufRXTimeout m2 : 30|1@1+ (1,0) [0|0] "" Vector__XXX
 SG_ VCSEC_a148_keyWhitelistFull m2 : 31|1@1+ (1,0) [0|0] "" Vector__XXX
 SG_ VCSEC_a149_attrsWentMissingL m2 : 32|1@1+ (1,0) [0|0] "" Vector__XXX
 SG_ VCSEC_a150_attrsWentMissingR m2 : 33|1@1+ (1,0) [0|0] "" Vector__XXX
 SG_ VCSEC_a151_attrsWentMissingRe m2 : 34|1@1+ (1,0) [0|0] "" Vector__XXX
 SG_ VCSEC_a153_srvcCmdTimeoutC m2 : 36|1@1+ (1,0) [0|0] "" Vector__XXX
 SG_ VCSEC_a154_srvcCmdTimeoutL m2 : 37|1@1+ (1,0) [0|0] "" Vector__XXX
 SG_ VCSEC_a155_srvcCmdTimeoutR m2 : 38|1@1+ (1,0) [0|0] "" Vector__XXX
 SG_ VCSEC_a156_srvcCmdTimeoutRe m2 : 39|1@1+ (1,0) [0|0] "" Vector__XXX
 SG_ VCSEC_a158_hciFaultC m2 : 41|1@1+ (1,0) [0|0] "" Vector__XXX
 SG_ VCSEC_a159_hciFaultL m2 : 42|1@1+ (1,0) [0|0] "" Vector__XXX
 SG_ VCSEC_a161_hciFaultR m2 : 44|1@1+ (1,0) [0|0] "" Vector__XXX
 SG_ VCSEC_a162_hciFaultRe m2 : 45|1@1+ (1,0) [0|0] "" Vector__XXX
 SG_ VCSEC_a164_attrsWentMissingC m2 : 47|1@1+ (1,0) [0|0] "" Vector__XXX
 SG_ VCSEC_a165_ephemeralKeyGenerated m2 : 48|1@1+ (1,0) [0|0] "" Vector__XXX
 SG_ VCSEC_a166_BLECenterPowerCycled m2 : 49|1@1+ (1,0) [0|0] "" Vector__XXX
 SG_ VCSEC_a167_BLECenterSoftReset m2 : 50|1@1+ (1,0) [0|0] "" Vector__XXX
 SG_ VCSEC_a168_BLELeftSoftReset m2 : 51|1@1+ (1,0) [0|0] "" Vector__XXX
 SG_ VCSEC_a169_BLERightSoftReset m2 : 52|1@1+ (1,0) [0|0] "" Vector__XXX
 SG_ VCSEC_a170_BLERearSoftReset m2 : 53|1@1+ (1,0) [0|0] "" Vector__XXX
 SG_ VCSEC_a172_BLEUnexpectedResetC m2 : 55|1@1+ (1,0) [0|0] "" Vector__XXX
 SG_ VCSEC_a173_BLEUnexpectedResetL m2 : 56|1@1+ (1,0) [0|0] "" Vector__XXX
 SG_ VCSEC_a174_BLEUnexpectedResetRi m2 : 57|1@1+ (1,0) [0|0] "" Vector__XXX
 SG_ VCSEC_a175_BLEUnexpectedResetRe m2 : 58|1@1+ (1,0) [0|0] "" Vector__XXX
 SG_ VCSEC_a177_whitelistAddedKey m2 : 60|1@1+ (1,0) [0|0] "" Vector__XXX
 SG_ VCSEC_a178_whitelistRemovedKey m2 : 61|1@1+ (1,0) [0|0] "" Vector__XXX
 SG_ VCSEC_a179_wlistAddedPermission m2 : 62|1@1+ (1,0) [0|0] "" Vector__XXX
 SG_ VCSEC_a180_wlistRemovedPermission m2 : 63|1@1+ (1,0) [0|0] "" Vector__XXX
 SG_ VCSEC_a181_signedMessageFault m3 : 4|1@1+ (1,0) [0|0] "" Vector__XXX
 SG_ VCSEC_a182_cryptoHighStackUsage m3 : 5|1@1+ (1,0) [0|0] "" Vector__XXX
 SG_ VCSEC_a183_centerEndpointRFMia m3 : 6|1@1+ (1,0) [0|0] "" Vector__XXX
 SG_ VCSEC_a184_driverEndpointRFMia m3 : 7|1@1+ (1,0) [0|0] "" Vector__XXX
 SG_ VCSEC_a185_passengerEndpointRFMia m3 : 8|1@1+ (1,0) [0|0] "" Vector__XXX
 SG_ VCSEC_a186_rearEndpointRFMia m3 : 9|1@1+ (1,0) [0|0] "" Vector__XXX
 SG_ VCSEC_a187_badConnectionDropped m3 : 10|1@1+ (1,0) [0|0] "" Vector__XXX
 SG_ VCSEC_a188_protobufDecodeError m3 : 11|1@1+ (1,0) [0|0] "" Vector__XXX
 SG_ VCSEC_a189_protoExpLengthTooLarge m3 : 12|1@1+ (1,0) [0|0] "" Vector__XXX
 SG_ VCSEC_a190_protoTooManyBytes m3 : 13|1@1+ (1,0) [0|0] "" Vector__XXX
 SG_ VCSEC_a191_macIDWlistingFailedC m3 : 14|1@1+ (1,0) [0|0] "" Vector__XXX
 SG_ VCSEC_a192_macIDWlistingFailedL m3 : 15|1@1+ (1,0) [0|0] "" Vector__XXX
 SG_ VCSEC_a193_macIDWlistingFailedRi m3 : 16|1@1+ (1,0) [0|0] "" Vector__XXX
 SG_ VCSEC_a194_macIDWlistingFailedRe m3 : 17|1@1+ (1,0) [0|0] "" Vector__XXX
 SG_ VCSEC_a195_keyMissingInDrive m3 : 18|1@1+ (1,0) [0|0] "" Vector__XXX
 SG_ VCSEC_a196_protobufTXTimeout m3 : 19|1@1+ (1,0) [0|0] "" Vector__XXX
 SG_ VCSEC_a197_indicationFault m3 : 20|1@1+ (1,0) [0|0] "" Vector__XXX
 SG_ VCSEC_a198_BPillarNFCReaderMIA m3 : 21|1@1+ (1,0) [0|0] "" Vector__XXX
 SG_ VCSEC_a199_CenterNFCReaderMIA m3 : 22|1@1+ (1,0) [0|0] "" Vector__XXX
 SG_ VCSEC_a200_centerEndpointLostComm m3 : 23|1@1+ (1,0) [0|0] "" Vector__XXX
 SG_ VCSEC_a201_leftEndpointLostComm m3 : 24|1@1+ (1,0) [0|0] "" Vector__XXX
 SG_ VCSEC_a202_rightEndpointLostComm m3 : 25|1@1+ (1,0) [0|0] "" Vector__XXX
 SG_ VCSEC_a203_rearEndpointLostComm m3 : 26|1@1+ (1,0) [0|0] "" Vector__XXX
 SG_ VCSEC_a204_SharedSecretsWritten m3 : 27|1@1+ (1,0) [0|0] "" Vector__XXX
 SG_ VCSEC_a205_MTUUpdateNotConfirmed m3 : 28|1@1+ (1,0) [0|0] "" Vector__XXX
 SG_ VCSEC_a206_BLELeftAssertFailure m3 : 29|1@1+ (1,0) [0|0] "" Vector__XXX
 SG_ VCSEC_a207_BLERightAssertFailure m3 : 30|1@1+ (1,0) [0|0] "" Vector__XXX
 SG_ VCSEC_a208_BLERearAssertFailure m3 : 31|1@1+ (1,0) [0|0] "" Vector__XXX
 SG_ VCSEC_a209_BLECenterAssertFailure m3 : 32|1@1+ (1,0) [0|0] "" Vector__XXX

BO_ 1018 APP_cameraLux: 8 CH
 SG_ APP_backupCameraLUX : 56|8@1+ (50,0) [0|0] "lux" Vector__XXX
 SG_ APP_fisheyeCameraLUX : 16|8@1+ (50,0) [0|0] "lux" Vector__XXX
 SG_ APP_lPillarCameraLUX : 40|8@1+ (50,0) [0|0] "lux" Vector__XXX
 SG_ APP_lRepeatCameraLUX : 24|8@1+ (50,0) [0|0] "lux" Vector__XXX
 SG_ APP_mainCameraLUX : 0|8@1+ (50,0) [0|0] "lux" Vector__XXX
 SG_ APP_narrowCameraLUX : 8|8@1+ (50,0) [0|0] "lux" Vector__XXX
 SG_ APP_rPillarCameraLUX : 48|8@1+ (50,0) [0|0] "lux" Vector__XXX
 SG_ APP_rRepeatCameraLUX : 32|8@1+ (50,0) [0|0] "lux" Vector__XXX

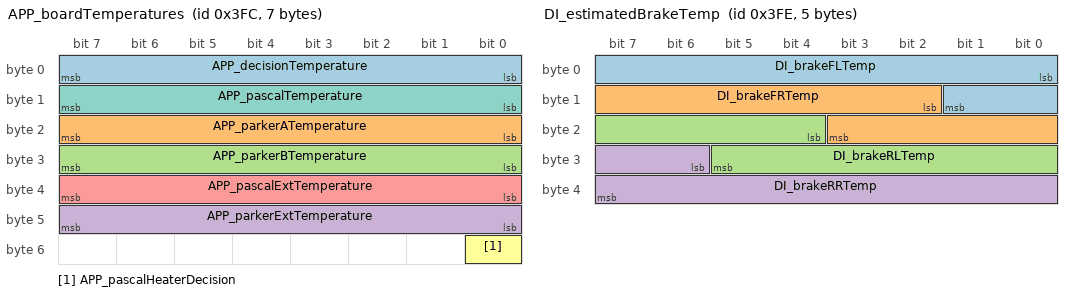
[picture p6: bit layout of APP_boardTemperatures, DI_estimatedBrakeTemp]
BO_ 1020 APP_boardTemperatures: 7 CH
 SG_ APP_decisionTemperature : 0|8@1+ (1,-128) [0|0] "C" Vector__XXX
 SG_ APP_parkerATemperature : 16|8@1+ (1,-128) [0|0] "C" Vector__XXX
 SG_ APP_parkerBTemperature : 24|8@1+ (1,-128) [0|0] "C" Vector__XXX
 SG_ APP_parkerExtTemperature : 40|8@1+ (1,-128) [0|0] "C" Vector__XXX
 SG_ APP_pascalExtTemperature : 32|8@1+ (1,-128) [0|0] "C" Vector__XXX
 SG_ APP_pascalHeaterDecision : 48|1@1+ (1,0) [0|0] "" Vector__XXX
 SG_ APP_pascalTemperature : 8|8@1+ (1,-128) [0|0] "C" Vector__XXX

BO_ 1021 UI_autopilotControl: 8 CH
 SG_ UI_autopilotControlIndex M : 0|3@1+ (1,0) [0|7] "" Vector__XXX
 SG_ UI_apmv3Branch m1 : 40|3@1+ (1,0) [0|5] "" Vector__XXX
 SG_ UI_applyEceR79 m1 : 19|1@1+ (1,0) [0|1] "" Vector__XXX
 SG_ UI_blindspotDistance m0 : 15|3@1+ (1,0) [0|5] "" Vector__XXX
 SG_ UI_blindspotMinSpeed m0 : 11|4@1+ (1,0) [0|10] "" Vector__XXX
 SG_ UI_blindspotTTC m0 : 18|3@1+ (1,0) [0|7] "" Vector__XXX
 SG_ UI_disableBackup m1 : 30|1@1+ (1,0) [0|1] "" Vector__XXX
 SG_ UI_disableFisheye m1 : 25|1@1+ (1,0) [0|1] "" Vector__XXX
 SG_ UI_disableLeftPillar m1 : 26|1@1+ (1,0) [0|1] "" Vector__XXX
 SG_ UI_disableLeftRepeater m1 : 28|1@1+ (1,0) [0|1] "" Vector__XXX
 SG_ UI_disableMain m1 : 23|1@1+ (1,0) [0|1] "" Vector__XXX
 SG_ UI_disableNarrow m1 : 24|1@1+ (1,0) [0|1] "" Vector__XXX
 SG_ UI_disableRadar m1 : 31|1@1+ (1,0) [0|1] "" Vector__XXX
 SG_ UI_disableRightPillar m1 : 27|1@1+ (1,0) [0|1] "" Vector__XXX
 SG_ UI_disableRightRepeater m1 : 29|1@1+ (1,0) [0|1] "" Vector__XXX
 SG_ UI_donAlcProgGoreAbortThres m0 : 29|4@1+ (1,0) [0|9] "" Vector__XXX
 SG_ UI_donDisableAutoWiperDuration m0 : 4|3@1+ (1,0) [0|6] "" Vector__XXX
 SG_ UI_donDisableCutin m0 : 24|1@1+ (1,0) [0|1] "" Vector__XXX
 SG_ UI_donDisableOnAutoWiperSpeed m0 : 7|4@1+ (1,0) [0|15] "" Vector__XXX
 SG_ UI_donMinGoreWidthForAbortMap m0 : 25|4@1+ (1,0) [0|11] "" Vector__XXX
 SG_ UI_donMinGoreWidthForAbortNotMap m0 : 33|4@1+ (1,0) [0|11] "" Vector__XXX
 SG_ UI_donStopEndOfRampBuffer m0 : 21|3@1+ (1,0) [0|4] "" Vector__XXX
 SG_ UI_driverMonitorConfirmation m1 : 17|1@1+ (1,0) [0|1] "" Vector__XXX
 SG_ UI_enableAutopilotStopWarning m1 : 44|1@1+ (1,0) [0|1] "" Vector__XXX
 SG_ UI_enableCabinCamera m1 : 43|1@1+ (1,0) [0|1] "" Vector__XXX
 SG_ UI_enableCabinCameraTelemetry m1 : 48|1@1+ (1,0) [0|1] "" Vector__XXX
 SG_ UI_enableMapStops m1 : 20|1@1+ (1,0) [0|1] "" Vector__XXX
 SG_ UI_factorySummonEnable m1 : 39|1@1+ (1,0) [0|1] "" Vector__XXX
 SG_ UI_fsdStopsControlEnabled m0 : 38|1@1+ (1,0) [0|1] "" Vector__XXX
 SG_ UI_fsdVisualizationEnabled m0 : 37|1@1+ (1,0) [0|1] "" Vector__XXX
 SG_ UI_hardCoreSummon m1 : 47|1@1+ (1,0) [0|1] "" Vector__XXX
 SG_ UI_homelinkNearby m0 : 45|1@1+ (1,0) [0|1] "" Vector__XXX
 SG_ UI_hovEnabled m0 : 3|1@1+ (1,0) [0|1] "" Vector__XXX
 SG_ UI_noStalkConfirmAlertChime m1 : 37|1@1+ (1,0) [0|1] "" Vector__XXX
 SG_ UI_noStalkConfirmAlertHaptic m1 : 32|1@1+ (1,0) [0|1] "" Vector__XXX
 SG_ UI_showLaneGraph m1 : 45|1@1+ (1,0) [0|1] "" Vector__XXX
 SG_ UI_showTrackLabels m1 : 46|1@1+ (1,0) [0|1] "" Vector__XXX
 SG_ UI_ulcSnooze m1 : 36|1@1+ (1,0) [0|1] "" Vector__XXX

BO_ 1022 DI_estimatedBrakeTemp: 5 VEH
 SG_ DI_brakeFLTemp : 0|10@1+ (1,-40) [0|0] "DegC" Vector__XXX
 SG_ DI_brakeFRTemp : 10|10@1+ (1,-40) [0|0] "DegC" Vector__XXX
 SG_ DI_brakeRLTemp : 20|10@1+ (1,-40) [0|0] "DegC" Vector__XXX
 SG_ DI_brakeRRTemp : 30|10@1+ (1,-40) [0|0] "DegC" Vector__XXX

BO_ 1025 BMS_brickVoltages: 8 VEH
 SG_ BMS_brickIndex M : 0|8@1+ (1,0) [0|0] ""  Receiver
 SG_ BMS_brickStatus : 8|8@1+ (1,0) [0|0] ""  Receiver
 SG_ BMS_brick0 m0 : 16|16@1+ (0.0001,0) [0|0] "V"  Receiver
 SG_ BMS_brick1 m0 : 32|16@1+ (0.0001,0) [0|0] "V"  Receiver
 SG_ BMS_brick2 m0 : 48|16@1+ (0.0001,0) [0|0] "V"  Receiver
 SG_ BMS_brick3 m1 : 16|16@1+ (0.0001,0) [0|0] "V"  Receiver
 SG_ BMS_brick4 m1 : 32|16@1+ (0.0001,0) [0|0] "V"  Receiver
 SG_ BMS_brick5 m1 : 48|16@1+ (0.0001,0) [0|0] "V"  Receiver
 SG_ BMS_brick6 m2 : 16|16@1+ (0.0001,0) [0|0] "V"  Receiver
 SG_ BMS_brick7 m2 : 32|16@1+ (0.0001,0) [0|0] "V"  Receiver
 SG_ BMS_brick8 m2 : 48|16@1+ (0.0001,0) [0|0] "V"  Receiver
 SG_ BMS_brick9 m3 : 16|16@1+ (0.0001,0) [0|0] "V"  Receiver
 SG_ BMS_brick10 m3 : 32|16@1+ (0.0001,0) [0|0] "V"  Receiver
 SG_ BMS_brick11 m3 : 48|16@1+ (0.0001,0) [0|0] "V"  Receiver
 SG_ BMS_brick12 m4 : 16|16@1+ (0.0001,0) [0|0] "V"  Receiver
 SG_ BMS_brick13 m4 : 32|16@1+ (0.0001,0) [0|0] "V"  Receiver
 SG_ BMS_brick14 m4 : 48|16@1+ (0.0001,0) [0|0] "V"  Receiver
 SG_ BMS_brick15 m5 : 16|16@1+ (0.0001,0) [0|0] "V"  Receiver
 SG_ BMS_brick16 m5 : 32|16@1+ (0.0001,0) [0|0] "V"  Receiver
 SG_ BMS_brick17 m5 : 48|16@1+ (0.0001,0) [0|0] "V"  Receiver
 SG_ BMS_brick18 m6 : 16|16@1+ (0.0001,0) [0|0] "V"  Receiver
 SG_ BMS_brick19 m6 : 32|16@1+ (0.0001,0) [0|0] "V"  Receiver
 SG_ BMS_brick20 m6 : 48|16@1+ (0.0001,0) [0|0] "V"  Receiver
 SG_ BMS_brick21 m7 : 16|16@1+ (0.0001,0) [0|0] "V"  Receiver
 SG_ BMS_brick22 m7 : 32|16@1+ (0.0001,0) [0|0] "V"  Receiver
 SG_ BMS_brick23 m7 : 48|16@1+ (0.0001,0) [0|0] "V"  Receiver
 SG_ BMS_brick24 m8 : 16|16@1+ (0.0001,0) [0|0] "V"  Receiver
 SG_ BMS_brick25 m8 : 32|16@1+ (0.0001,0) [0|0] "V"  Receiver
 SG_ BMS_brick26 m8 : 48|16@1+ (0.0001,0) [0|0] "V"  Receiver
 SG_ BMS_brick27 m9 : 16|16@1+ (0.0001,0) [0|0] "V"  Receiver
 SG_ BMS_brick28 m9 : 32|16@1+ (0.0001,0) [0|0] "V"  Receiver
 SG_ BMS_brick29 m9 : 48|16@1+ (0.0001,0) [0|0] "V"  Receiver
 SG_ BMS_brick30 m10 : 16|16@1+ (0.0001,0) [0|0] "V"  Receiver
 SG_ BMS_brick31 m10 : 32|16@1+ (0.0001,0) [0|0] "V"  Receiver
 SG_ BMS_brick32 m10 : 48|16@1+ (0.0001,0) [0|0] "V"  Receiver
 SG_ BMS_brick34 m11 : 16|16@1+ (0.0001,0) [0|0] "V"  Receiver
 SG_ BMS_brick33 m11 : 32|16@1+ (0.0001,0) [0|0] "V"  Receiver
 SG_ BMS_brick35 m11 : 48|16@1+ (0.0001,0) [0|0] "V"  Receiver
 SG_ BMS_brick36 m12 : 16|16@1+ (0.0001,0) [0|0] "V"  Receiver
 SG_ BMS_brick37 m12 : 32|16@1+ (0.0001,0) [0|0] "V"  Receiver
 SG_ BMS_brick38 m12 : 48|16@1+ (0.0001,0) [0|0] "V"  Receiver
 SG_ BMS_brick39 m13 : 16|16@1+ (0.0001,0) [0|0] "V"  Receiver
 SG_ BMS_brick40 m13 : 32|16@1+ (0.0001,0) [0|0] "V"  Receiver
 SG_ BMS_brick41 m13 : 48|16@1+ (0.0001,0) [0|0] "V"  Receiver
 SG_ BMS_brick42 m14 : 16|16@1+ (0.0001,0) [0|0] "V"  Receiver
 SG_ BMS_brick43 m14 : 32|16@1+ (0.0001,0) [0|0] "V"  Receiver
 SG_ BMS_brick44 m14 : 48|16@1+ (0.0001,0) [0|0] "V"  Receiver
 SG_ BMS_brick45 m15 : 16|16@1+ (0.0001,0) [0|0] "V"  Receiver
 SG_ BMS_brick46 m15 : 32|16@1+ (0.0001,0) [0|0] "V"  Receiver
 SG_ BMS_brick47 m15 : 48|16@1+ (0.0001,0) [0|0] "V"  Receiver
 SG_ BMS_brick48 m16 : 16|16@1+ (0.0001,0) [0|0] "V"  Receiver
 SG_ BMS_brick49 m16 : 32|16@1+ (0.0001,0) [0|0] "V"  Receiver
 SG_ BMS_brick50 m16 : 48|16@1+ (0.0001,0) [0|0] "V"  Receiver
 SG_ BMS_brick51 m17 : 16|16@1+ (0.0001,0) [0|0] "V"  Receiver
 SG_ BMS_brick52 m17 : 32|16@1+ (0.0001,0) [0|0] "V"  Receiver
 SG_ BMS_brick53 m17 : 48|16@1+ (0.0001,0) [0|0] "V"  Receiver
 SG_ BMS_brick54 m18 : 16|16@1+ (0.0001,0) [0|0] "V"  Receiver
 SG_ BMS_brick55 m18 : 32|16@1+ (0.0001,0) [0|0] "V"  Receiver
 SG_ BMS_brick56 m18 : 48|16@1+ (0.0001,0) [0|0] "V"  Receiver
 SG_ BMS_brick57 m19 : 16|16@1+ (0.0001,0) [0|0] "V"  Receiver
 SG_ BMS_brick58 m19 : 32|16@1+ (0.0001,0) [0|0] "V"  Receiver
 SG_ BMS_brick59 m19 : 48|16@1+ (0.0001,0) [0|0] "V"  Receiver
 SG_ BMS_brick60 m20 : 16|16@1+ (0.0001,0) [0|0] "V"  Receiver
 SG_ BMS_brick61 m20 : 32|16@1+ (0.0001,0) [0|0] "V"  Receiver
 SG_ BMS_brick62 m20 : 48|16@1+ (0.0001,0) [0|0] "V"  Receiver
 SG_ BMS_brick63 m21 : 16|16@1+ (0.0001,0) [0|0] "V"  Receiver
 SG_ BMS_brick64 m21 : 32|16@1+ (0.0001,0) [0|0] "V"  Receiver
 SG_ BMS_brick65 m21 : 48|16@1+ (0.0001,0) [0|0] "V"  Receiver
 SG_ BMS_brick66 m22 : 16|16@1+ (0.0001,0) [0|0] "V"  Receiver
 SG_ BMS_brick67 m22 : 32|16@1+ (0.0001,0) [0|0] "V"  Receiver
 SG_ BMS_brick68 m22 : 48|16@1+ (0.0001,0) [0|0] "V"  Receiver
 SG_ BMS_brick69 m23 : 16|16@1+ (0.0001,0) [0|0] "V"  Receiver
 SG_ BMS_brick70 m23 : 32|16@1+ (0.0001,0) [0|0] "V"  Receiver
 SG_ BMS_brick71 m23 : 48|16@1+ (0.0001,0) [0|0] "V"  Receiver
 SG_ BMS_brick72 m24 : 16|16@1+ (0.0001,0) [0|0] "V"  Receiver
 SG_ BMS_brick73 m24 : 32|16@1+ (0.0001,0) [0|0] "V"  Receiver
 SG_ BMS_brick74 m24 : 48|16@1+ (0.0001,0) [0|0] "V"  Receiver
 SG_ BMS_brick75 m25 : 16|16@1+ (0.0001,0) [0|0] "V"  Receiver
 SG_ BMS_brick76 m25 : 32|16@1+ (0.0001,0) [0|0] "V"  Receiver
 SG_ BMS_brick77 m25 : 48|16@1+ (0.0001,0) [0|0] "V"  Receiver
 SG_ BMS_brick78 m26 : 16|16@1+ (0.0001,0) [0|0] "V"  Receiver
 SG_ BMS_brick79 m26 : 32|16@1+ (0.0001,0) [0|0] "V"  Receiver
 SG_ BMS_brick80 m26 : 48|16@1+ (0.0001,0) [0|0] "V"  Receiver
 SG_ BMS_brick81 m27 : 16|16@1+ (0.0001,0) [0|0] "V"  Receiver
 SG_ BMS_brick82 m27 : 32|16@1+ (0.0001,0) [0|0] "V"  Receiver
 SG_ BMS_brick83 m27 : 48|16@1+ (0.0001,0) [0|0] "V"  Receiver
 SG_ BMS_brick84 m28 : 16|16@1+ (0.0001,0) [0|0] "V"  Receiver
 SG_ BMS_brick85 m28 : 32|16@1+ (0.0001,0) [0|0] "V"  Receiver
 SG_ BMS_brick86 m28 : 48|16@1+ (0.0001,0) [0|0] "V"  Receiver
 SG_ BMS_brick87 m29 : 16|16@1+ (0.0001,0) [0|0] "V"  Receiver
 SG_ BMS_brick88 m29 : 32|16@1+ (0.0001,0) [0|0] "V"  Receiver
 SG_ BMS_brick89 m29 : 48|16@1+ (0.0001,0) [0|0] "V"  Receiver
 SG_ BMS_brick90 m30 : 16|16@1+ (0.0001,0) [0|0] "V"  Receiver
 SG_ BMS_brick91 m30 : 32|16@1+ (0.0001,0) [0|0] "V"  Receiver
 SG_ BMS_brick92 m30 : 48|16@1+ (0.0001,0) [0|0] "V"  Receiver
 SG_ BMS_brick93 m31 : 16|16@1+ (0.0001,0) [0|0] "V"  Receiver
 SG_ BMS_brick94 m31 : 32|16@1+ (0.0001,0) [0|0] "V"  Receiver
 SG_ BMS_brick95 m31 : 48|16@1+ (0.0001,0) [0|0] "V"  Receiver
 SG_ BMS_brick96 m32 : 16|16@1+ (0.0001,0) [0|0] "V"  Receiver
 SG_ BMS_brick97 m32 : 32|16@1+ (0.0001,0) [0|0] "V"  Receiver
 SG_ BMS_brick98 m32 : 48|16@1+ (0.0001,0) [0|0] "V"  Receiver
 SG_ BMS_brick99 m33 : 16|16@1+ (0.0001,0) [0|0] "V"  Receiver
 SG_ BMS_brick100 m33 : 32|16@1+ (0.0001,0) [0|0] "V"  Receiver
 SG_ BMS_brick101 m33 : 48|16@1+ (0.0001,0) [0|0] "V"  Receiver
 SG_ BMS_brick102 m34 : 16|16@1+ (0.0001,0) [0|0] "V"  Receiver
 SG_ BMS_brick103 m34 : 32|16@1+ (0.0001,0) [0|0] "V"  Receiver
 SG_ BMS_brick104 m34 : 48|16@1+ (0.0001,0) [0|0] "V"  Receiver
 SG_ BMS_brick105 m35 : 16|16@1+ (0.0001,0) [0|0] "V"  Receiver
 SG_ BMS_brick106 m35 : 32|16@1+ (0.0001,0) [0|0] "V"  Receiver
 SG_ BMS_brick107 m35 : 48|16@1+ (0.0001,0) [0|0] "V"  Receiver
 SG_ BMS_Brick108 m36 : 16|16@1+ (0.0001,0) [0|0] "V"   X
 SG_ BMS_Brick109 m36 : 32|16@1+ (0.0001,0) [0|0] "V"   X
 SG_ BMS_Brick110 m36 : 48|16@1+ (0.0001,0) [0|0] "V"   X

BA_DEF_ BO_  "GenMsgSendType" ENUM  "Cyclic";
BA_DEF_ BO_  "GenMsgCycleTime" INT 0 10000;
BA_ "GenMsgSendType" BO_ 994 0;
BA_ "GenMsgCycleTime" BO_ 994 100;
BA_ "GenMsgSendType" BO_ 1020 0;
BA_ "GenMsgCycleTime" BO_ 1020 1000;
BA_ "GenMsgSendType" BO_ 1012 0;
BA_ "GenMsgCycleTime" BO_ 1012 1000;
BA_ "GenMsgSendType" BO_ 1018 0;
BA_ "GenMsgCycleTime" BO_ 1018 500;
BA_ "GenMsgSendType" BO_ 970 0;
BA_ "GenMsgCycleTime" BO_ 970 500;
BA_ "GenMsgSendType" BO_ 978 0;
BA_ "GenMsgCycleTime" BO_ 978 1000;
BA_ "GenMsgSendType" BO_ 1010 0;
BA_ "GenMsgCycleTime" BO_ 1010 1000;
BA_ "GenMsgSendType" BO_ 1001 0;
BA_ "GenMsgCycleTime" BO_ 1001 500;
BA_ "GenMsgSendType" BO_ 921 0;
BA_ "GenMsgCycleTime" BO_ 921 500;
BA_ "GenMsgSendType" BO_ 937 0;
BA_ "GenMsgCycleTime" BO_ 937 100;
BA_ "GenMsgSendType" BO_ 986 0;
BA_ "GenMsgCycleTime" BO_ 986 100;
BA_ "GenMsgSendType" BO_ 945 0;
BA_ "GenMsgCycleTime" BO_ 945 40;
BA_ "GenMsgSendType" BO_ 933 0;
BA_ "GenMsgCycleTime" BO_ 933 1000;
BA_ "GenMsgSendType" BO_ 949 0;
BA_ "GenMsgCycleTime" BO_ 949 1000;
BA_ "GenMsgSendType" BO_ 965 0;
BA_ "GenMsgCycleTime" BO_ 965 1000;
BA_ "GenMsgSendType" BO_ 997 0;
BA_ "GenMsgCycleTime" BO_ 997 1000;
BA_ "GenMsgSendType" BO_ 1022 0;
BA_ "GenMsgCycleTime" BO_ 1022 1000;
BA_ "GenMsgSendType" BO_ 950 0;
BA_ "GenMsgCycleTime" BO_ 950 1000;
BA_ "GenMsgSendType" BO_ 917 0;
BA_ "GenMsgCycleTime" BO_ 917 100;
BA_ "GenMsgSendType" BO_ 918 0;
BA_ "GenMsgCycleTime" BO_ 918 100;
BA_ "GenMsgSendType" BO_ 968 0;
BA_ "GenMsgCycleTime" BO_ 968 100;
BA_ "GenMsgSendType" BO_ 1000 0;
BA_ "GenMsgCycleTime" BO_ 1000 100;
BA_ "GenMsgSendType" BO_ 981 0;
BA_ "GenMsgCycleTime" BO_ 981 1000;
BA_ "GenMsgSendType" BO_ 927 0;
BA_ "GenMsgCycleTime" BO_ 927 1000;
BA_ "GenMsgSendType" BO_ 958 0;
BA_ "GenMsgCycleTime" BO_ 958 1000;
BA_ "GenMsgSendType" BO_ 990 0;
BA_ "GenMsgCycleTime" BO_ 990 1000;
BA_ "GenMsgSendType" BO_ 938 0;
BA_ "GenMsgCycleTime" BO_ 938 1000;
BA_ "GenMsgSendType" BO_ 925 0;
BA_ "GenMsgCycleTime" BO_ 925 40;
BA_ "GenMsgSendType" BO_ 926 0;
BA_ "GenMsgCycleTime" BO_ 926 100;
BA_ "GenMsgSendType" BO_ 932 0;
BA_ "GenMsgCycleTime" BO_ 932 1000;
BA_ "GenMsgSendType" BO_ 964 0;
BA_ "GenMsgCycleTime" BO_ 964 1000;
BA_ "GenMsgSendType" BO_ 941 0;
BA_ "GenMsgCycleTime" BO_ 941 1000;
BA_ "GenMsgSendType" BO_ 973 0;
BA_ "GenMsgCycleTime" BO_ 973 1000;
BA_ "GenMsgSendType" BO_ 979 0;
BA_ "GenMsgCycleTime" BO_ 979 500;
BA_ "GenMsgSendType" BO_ 1016 0;
BA_ "GenMsgCycleTime" BO_ 1016 1000;
BA_ "GenMsgSendType" BO_ 984 0;
BA_ "GenMsgCycleTime" BO_ 984 1000;
BA_ "GenMsgSendType" BO_ 985 0;
BA_ "GenMsgCycleTime" BO_ 985 1000;
BA_ "GenMsgSendType" BO_ 1011 0;
BA_ "GenMsgCycleTime" BO_ 1011 1000;
BA_ "GenMsgSendType" BO_ 952 0;
BA_ "GenMsgCycleTime" BO_ 952 1000;
BA_ "GenMsgSendType" BO_ 947 0;
BA_ "GenMsgCycleTime" BO_ 947 500;
BA_ "GenMsgSendType" BO_ 1009 0;
BA_ "GenMsgCycleTime" BO_ 1009 100;
BA_ "GenMsgSendType" BO_ 929 0;
BA_ "GenMsgCycleTime" BO_ 929 100;
BA_ "GenMsgSendType" BO_ 930 0;
BA_ "GenMsgCycleTime" BO_ 930 50;
BA_ "GenMsgSendType" BO_ 962 0;
BA_ "GenMsgCycleTime" BO_ 962 50;
BA_ "GenMsgSendType" BO_ 960 0;
BA_ "GenMsgCycleTime" BO_ 960 100;
BA_ "GenMsgSendType" BO_ 995 0;
BA_ "GenMsgCycleTime" BO_ 995 100;
BA_ "GenMsgSendType" BO_ 969 0;
BA_ "GenMsgCycleTime" BO_ 969 1000;
BA_ "GenMsgSendType" BO_ 1017 0;
BA_ "GenMsgCycleTime" BO_ 1017 100;
VAL_ 917 DI_oilPumpState 0 "STANDBY" 1 "ENABLE" 2 "COLD_STARTUP" 6 "FAULTED" 7 "SNA" ;
VAL_ 917 DI_oilPumpFlowTarget 255 "SNA" ;
VAL_ 917 DI_oilPumpFlowActual 255 "SNA" ;
VAL_ 917 DI_oilPumpPcbT 255 "SNA" ;
VAL_ 917 DI_oilPumpFluidT 255 "SNA" ;
VAL_ 917 DI_oilPumpVoltage 255 "SNA" ;
VAL_ 917 DI_oilPumpCurrent 255 "SNA" ;
VAL_ 917 DI_oilPumpCurrentSensorOffset 255 "SNA" ;
VAL_ 918 DI_frontOilPumpCurrent 255 "SNA" ;
VAL_ 918 DI_frontOilPumpFlowActual 255 "SNA" ;
VAL_ 918 DI_frontOilPumpFlowTarget 255 "SNA" ;
VAL_ 918 DI_frontOilPumpFluidT 255 "SNA" ;
VAL_ 918 DI_frontOilPumpPcbT 255 "SNA" ;
VAL_ 918 DI_frontOilPumpState 0 "STANDBY" 1 "ENABLE" 2 "COLD_STARTUP" 6 "FAULTED" 7 "SNA" ;
VAL_ 918 DI_frontOilPumpVoltage 255 "SNA" ;
VAL_ 921 DAS_autoLaneChangeState 0 "UNAVAILABLE_DISABLED" 1 "UNAVAILABLE_NO_LANES" 2 "UNAVAILABLE_SONICS_INVALID" 3 "UNAVAILABLE_TP_FOLLOW" 4 "UNAVAILABLE_EXITING_HIGHWAY" 5 "UNAVAILABLE_VEHICLE_SPEED" 6 "AVAILABLE_ONLY_L" 7 "AVAILABLE_ONLY_R" 8 "AVAILABLE_BOTH" 9 "IN_PROGRESS_L" 10 "IN_PROGRESS_R" 11 "WAITING_FOR_SIDE_OBST_TO_PASS_L" 12 "WAITING_FOR_SIDE_OBST_TO_PASS_R" 13 "WAITING_FOR_FWD_OBST_TO_PASS_L" 14 "WAITING_FOR_FWD_OBST_TO_PASS_R" 15 "ABORT_SIDE_OBSTACLE_PRESENT_L" 16 "ABORT_SIDE_OBSTACLE_PRESENT_R" 17 "ABORT_POOR_VIEW_RANGE" 18 "ABORT_LC_HEALTH_BAD" 19 "ABORT_BLINKER_TURNED_OFF" 20 "ABORT_OTHER_REASON" 21 "UNAVAILABLE_SOLID_LANE_LINE" 22 "BLOCKED_VEH_TTC_L" 23 "BLOCKED_VEH_TTC_AND_USS_L" 24 "BLOCKED_VEH_TTC_R" 25 "BLOCKED_VEH_TTC_AND_USS_R" 26 "BLOCKED_LANE_TYPE_L" 27 "BLOCKED_LANE_TYPE_R" 28 "WAITING_HANDS_ON" 29 "ABORT_TIMEOUT" 30 "ABORT_MISSION_PLAN_INVALID" 31 "SNA" ;
VAL_ 921 DAS_autoparkReady 0 "UNAVAILABLE" 1 "READY" ;
VAL_ 921 DAS_autopilotHandsOnState 0 "NOT_REQD" 1 "REQD_DETECTED" 2 "REQD_NOT_DETECTED" 3 "REQD_VISUAL" 4 "REQD_CHIME_1" 5 "REQD_CHIME_2" 6 "REQD_SLOWING" 7 "REQD_STRUCK_OUT" 8 "SUSPENDED" 15 "SNA" ;
VAL_ 921 DAS_autopilotState 0 "DISABLED" 1 "UNAVAILABLE" 2 "AVAILABLE" 3 "ACTIVE_NOMINAL" 4 "ACTIVE_RESTRICTED" 5 "ACTIVE_NAV" 8 "ABORTING" 9 "ABORTED" 14 "FAULT" 15 "SNA" ;
VAL_ 921 DAS_blindSpotRearLeft 0 "NO_WARNING" 1 "WARNING_LEVEL_1" 2 "WARNING_LEVEL_2" 3 "SNA" ;
VAL_ 921 DAS_blindSpotRearRight 0 "NO_WARNING" 1 "WARNING_LEVEL_1" 2 "WARNING_LEVEL_2" 3 "SNA" ;
VAL_ 921 DAS_csaState 0 "UNAVAILABLE" 1 "AVAILABLE" 2 "ENABLE" 3 "HOLD" ;
VAL_ 921 DAS_fleetSpeedState 0 "UNAVAILABLE" 1 "AVAILABLE" 2 "ACTIVE" 3 "HOLD" ;
VAL_ 921 DAS_forwardCollisionWarning 0 "NONE" 1 "FORWARD_COLLISION_WARNING" 3 "SNA" ;
VAL_ 921 DAS_fusedSpeedLimit 0 "UNKNOWN_SNA" 31 "NONE" ;
VAL_ 921 DAS_heaterState 0 "OFF_SNA" 1 "ON" ;
VAL_ 921 DAS_laneDepartureWarning 0 "NONE" 1 "LEFT_WARNING" 2 "RIGHT_WARNING" 3 "LEFT_WARNING_SEVERE" 4 "RIGHT_WARNING_SEVERE" 5 "SNA" ;
VAL_ 921 DAS_sideCollisionAvoid 0 "NONE" 1 "AVOID_LEFT" 2 "AVOID_RIGHT" 3 "SNA" ;
VAL_ 921 DAS_sideCollisionInhibit 0 "NO_INHIBIT" 1 "INHIBIT" ;
VAL_ 921 DAS_sideCollisionWarning 0 "NONE" 1 "WARN_LEFT" 2 "WARN_RIGHT" 3 "WARN_LEFT_RIGHT" ;
VAL_ 921 DAS_suppressSpeedWarning 0 "Do_Not_Suppress" 1 "Suppress_Speed_Warning" ;
VAL_ 921 DAS_visionOnlySpeedLimit 0 "UNKNOWN_SNA" 31 "NONE" ;
VAL_ 925 IBST_driverBrakeApply 0 "NOT_INIT_OR_OFF" 1 "BRAKES_NOT_APPLIED" 2 "DRIVER_APPLYING_BRAKES" 3 "FAULT" ;
VAL_ 925 IBST_iBoosterStatus 0 "OFF" 1 "INIT" 2 "FAILURE" 3 "DIAGNOSTIC" 4 "ACTIVE_GOOD_CHECK" 5 "READY" 6 "ACTUATION" ;
VAL_ 925 IBST_internalState 4 "DIAGNOSTIC" 3 "EXTERNAL_BRAKE_REQUEST" 2 "LOCAL_BRAKE_REQUEST" 0 "NO_MODE_ACTIVE" 6 "POST_DRIVE_CHECK" 1 "PRE_DRIVE_CHECK" 5 "TRANSITION_TO_IDLE" ;
VAL_ 926 PARK_leftSideFrontRawDistData 255 "SNA" ;
VAL_ 926 PARK_leftSideRearRawDistData 255 "SNA" ;
VAL_ 926 PARK_rightSideFrontRawDistData 255 "SNA" ;
VAL_ 926 PARK_rightSideRearRawDistData 255 "SNA" ;
VAL_ 929 VCFRONT_12vStatusForDrive 0 "NOT_READY_FOR_DRIVE_12V" 1 "READY_FOR_DRIVE_12V" 2 "EXIT_DRIVE_REQUESTED_12V" ;
VAL_ 929 VCFRONT_2RowCenterUnbuckled 0 "NONE" 1 "OCCUPIED_AND_UNBUCKLED" 2 "SNA" ;
VAL_ 929 VCFRONT_2RowLeftUnbuckled 0 "NONE" 1 "OCCUPIED_AND_UNBUCKLED" 2 "SNA" ;
VAL_ 929 VCFRONT_2RowRightUnbuckled 0 "NONE" 1 "OCCUPIED_AND_UNBUCKLED" 2 "SNA" ;
VAL_ 929 VCFRONT_APGlassHeaterState 0 "SNA" 1 "ON" 2 "OFF" 3 "OFF_UNAVAILABLE" 4 "FAULT" ;
VAL_ 929 VCFRONT_diPowerOnState 0 "POWERED_OFF" 1 "POWERED_ON_FOR_POST_RUN" 2 "POWERED_ON_FOR_STATIONARY_HEAT" 3 "POWERED_ON_FOR_DRIVE" 4 "POWER_GOING_DOWN" ;
VAL_ 929 VCFRONT_driverBuckleStatus 0 "UNBUCKLED" 1 "BUCKLED" ;
VAL_ 929 VCFRONT_driverDoorStatus 0 "OPEN" 1 "CLOSED" ;
VAL_ 929 VCFRONT_driverUnbuckled 0 "NONE" 1 "OCCUPIED_AND_UNBUCKLED" 2 "SNA" ;
VAL_ 929 VCFRONT_passengerUnbuckled 0 "NONE" 1 "OCCUPIED_AND_UNBUCKLED" 2 "SNA" ;
VAL_ 929 VCFRONT_pcsEFuseVoltage 1023 "SNA" ;
VAL_ 929 VCFRONT_thermalSystemType 1 "HEAT_PUMP_THERMAL_SYSTEM" 0 "LEGACY_THERMAL_SYSTEM" ;
VAL_ 930 VCLEFT_statusIndex 0 "MUX0" 1 "MUX1" ;
VAL_ 930 VCLEFT_vehiclePowerStateDBG 0 "OFF" 1 "CONDITIONING" 2 "ACCESSORY" 3 "DRIVE" ;
VAL_ 930 VCLEFT_swcInputVoltage 255 "SNA" ;
VAL_ 930 VCLEFT_swcPCBATemperature 128 "SNA" ;
VAL_ 930 VCLEFT_tlcPCBATemperature 128 "SNA" ;
VAL_ 932 PCS_matrixIndex 0 "AlertMatrix0" 1 "AlertMatrix1" ;
VAL_ 937 DAS_telemetryMultiplexer 0 "ROAD_INFORMATION" 1 "ACC_DRIVER_MONITOR" 2 "TRAFFIC_SIGNS" 7 "CSA_EVENT" 8 "STATIONARY_OBST" 9 "CRUISE_STALK_INPUT" ;
VAL_ 937 DAS_telLeftLaneType 0 "UNDECIDED" 1 "SOLID" 2 "ROAD_EDGE" 3 "DASHED" 4 "DOUBLE" 5 "BOTTS_DOTS" 6 "BARRIER" ;
VAL_ 937 DAS_telRightLaneType 0 "UNDECIDED" 1 "SOLID" 2 "ROAD_EDGE" 3 "DASHED" 4 "DOUBLE" 5 "BOTTS_DOTS" 6 "BARRIER" ;
VAL_ 937 DAS_telLeftMarkerQuality 0 "LOWEST" 1 "LOW" 2 "MEDIUM" 3 "HIGH" ;
VAL_ 937 DAS_telRightMarkerQuality 0 "LOWEST" 1 "LOW" 2 "MEDIUM" 3 "HIGH" ;
VAL_ 937 DAS_telLeftMarkerColor 0 "UNKNOWN" 1 "WHITE" 2 "YELLOW" 3 "BLUE" ;
VAL_ 937 DAS_telRightMarkerColor 0 "UNKNOWN" 1 "WHITE" 2 "YELLOW" 3 "BLUE" ;
VAL_ 937 DAS_telLeftLaneCrossing 0 "NOT_CROSSING" 1 "CROSSING" ;
VAL_ 937 DAS_telRightLaneCrossing 0 "NOT_CROSSING" 1 "CROSSING" ;
VAL_ 937 DAS_soCamCipvStatus 0 "INVALID" 1 "UNFUSED" 2 "FUSED_W_OTHER_RAD_OBJ" 3 "FUSED_W_RAD5" ;
VAL_ 937 DAS_soRad5Status 0 "INVALID" 1 "UNFUSED" 2 "FUSED_W_CIPV" 3 "FUSED_W_OTHER_CAMOBJ" ;
VAL_ 937 DAS_soRad1Status 0 "INVALID" 1 "UNFUSED" 2 "FUSED_W_CIPV" 3 "FUSED_W_OTHER_CAMOBJ" ;
VAL_ 945 DAS_TF_multiplexer 0 "Mux0" 1 "Mux1" 2 "Mux2" ;
VAL_ 947 UI_autopilotPowerStateRequest 0 "AUTOPILOT_NOMINAL" 1 "AUTOPILOT_SENTRY" 2 "AUTOPILOT_SUSPEND" ;
VAL_ 947 UI_autopilotPowerStateRequest 0 "AUTOPILOT_NOMINAL" 1 "AUTOPILOT_SENTRY" 2 "AUTOPILOT_SUSPEND" ;
VAL_ 947 UI_lightSwitch 0 "LIGHT_SWITCH_AUTO" 3 "LIGHT_SWITCH_OFF" 1 "LIGHT_SWITCH_ON" 2 "LIGHT_SWITCH_PARKING" 4 "LIGHT_SWITCH_SNA" ;
VAL_ 947 UI_shorted12VCellTestMode 2 "SHORTED_CELL_TEST_MODE_ACTIVE" 0 "SHORTED_CELL_TEST_MODE_DISABLED" 1 "SHORTED_CELL_TEST_MODE_SHADOW" ;
VAL_ 947 UI_summonState 3 "ACTIVE" 1 "IDLE" 2 "PRE_PRIMED" 0 "SNA" ;
VAL_ 947 UI_windowRequest 3 "WINDOW_REQUEST_GOTO_CLOSED" 4 "WINDOW_REQUEST_GOTO_OPEN" 1 "WINDOW_REQUEST_GOTO_PERCENT" 2 "WINDOW_REQUEST_GOTO_VENT" 0 "WINDOW_REQUEST_IDLE" ;
VAL_ 950 DI_odometer 0 "SNA" ;
VAL_ 960 VCRIGHT_matrixIndex 0 "AlertMatrix0" 1 "AlertMatrix1" 2 "AlertMatrix2" 3 "AlertMatrix3" 4 "AlertMatrix4" 5 "AlertMatrix5" ;
VAL_ 962 VCLEFT_switchStatusIndex 0 "0" 1 "1" 2 "INVALID" ;
VAL_ 962 VCLEFT_frontBuckleSwitch 0 "SNA" 1 "OFF" 2 "ON" 3 "FAULT" ;
VAL_ 962 VCLEFT_frontOccupancySwitch 0 "SNA" 1 "OFF" 2 "ON" 3 "FAULT" ;
VAL_ 962 VCLEFT_frontSeatBackrestBack 0 "SNA" 1 "OFF" 2 "ON" 3 "FAULT" ;
VAL_ 962 VCLEFT_frontSeatBackrestForward 0 "SNA" 1 "OFF" 2 "ON" 3 "FAULT" ;
VAL_ 962 VCLEFT_frontSeatLiftDown 0 "SNA" 1 "OFF" 2 "ON" 3 "FAULT" ;
VAL_ 962 VCLEFT_frontSeatLiftUp 0 "SNA" 1 "OFF" 2 "ON" 3 "FAULT" ;
VAL_ 962 VCLEFT_frontSeatLumbarDown 0 "SNA" 1 "OFF" 2 "ON" 3 "FAULT" ;
VAL_ 962 VCLEFT_frontSeatLumbarIn 0 "SNA" 1 "OFF" 2 "ON" 3 "FAULT" ;
VAL_ 962 VCLEFT_frontSeatLumbarOut 0 "SNA" 1 "OFF" 2 "ON" 3 "FAULT" ;
VAL_ 962 VCLEFT_frontSeatLumbarUp 0 "SNA" 1 "OFF" 2 "ON" 3 "FAULT" ;
VAL_ 962 VCLEFT_frontSeatTiltDown 0 "SNA" 1 "OFF" 2 "ON" 3 "FAULT" ;
VAL_ 962 VCLEFT_frontSeatTiltUp 0 "SNA" 1 "OFF" 2 "ON" 3 "FAULT" ;
VAL_ 962 VCLEFT_frontSeatTrackBack 0 "SNA" 1 "OFF" 2 "ON" 3 "FAULT" ;
VAL_ 962 VCLEFT_frontSeatTrackForward 0 "SNA" 1 "OFF" 2 "ON" 3 "FAULT" ;
VAL_ 962 VCLEFT_rearCenterOccupancySwitch 0 "SNA" 1 "OFF" 2 "ON" 3 "FAULT" ;
VAL_ 962 VCLEFT_rearLeftBuckleSwitch 0 "SNA" 1 "OFF" 2 "ON" 3 "FAULT" ;
VAL_ 962 VCLEFT_rearLeftOccupancySwitch 0 "SNA" 1 "OFF" 2 "ON" 3 "FAULT" ;
VAL_ 962 VCLEFT_rearRightOccupancySwitch 0 "SNA" 1 "OFF" 2 "ON" 3 "FAULT" ;
VAL_ 962 VCLEFT_rightMirrorTilt 0 "STOP" 1 "DOWN" 2 "UP" 3 "RIGHT" 4 "LEFT" ;
VAL_ 962 VCLEFT_swcLeftPressed 0 "SNA" 1 "OFF" 2 "ON" 3 "FAULT" ;
VAL_ 962 VCLEFT_swcLeftTiltLeft 0 "SNA" 1 "OFF" 2 "ON" 3 "FAULT" ;
VAL_ 962 VCLEFT_swcLeftTiltRight 0 "SNA" 1 "OFF" 2 "ON" 3 "FAULT" ;
VAL_ 962 VCLEFT_swcRightPressed 0 "SNA" 1 "OFF" 2 "ON" 3 "FAULT" ;
VAL_ 962 VCLEFT_swcRightTiltLeft 0 "SNA" 1 "OFF" 2 "ON" 3 "FAULT" ;
VAL_ 962 VCLEFT_swcRightTiltRight 0 "SNA" 1 "OFF" 2 "ON" 3 "FAULT" ;
VAL_ 963 VCRIGHT_frontBuckleSwitch 3 "SWITCH_FAULT" 1 "SWITCH_OFF" 2 "SWITCH_ON" 0 "SWITCH_SNA" ;
VAL_ 963 VCRIGHT_frontBuckleSwitch 3 "SWITCH_FAULT" 1 "SWITCH_OFF" 2 "SWITCH_ON" 0 "SWITCH_SNA" ;
VAL_ 963 VCRIGHT_frontOccupancySwitch 3 "SWITCH_FAULT" 1 "SWITCH_OFF" 2 "SWITCH_ON" 0 "SWITCH_SNA" ;
VAL_ 963 VCRIGHT_frontSeatBackrestBack 3 "SWITCH_FAULT" 1 "SWITCH_OFF" 2 "SWITCH_ON" 0 "SWITCH_SNA" ;
VAL_ 963 VCRIGHT_frontSeatBackrestForward 3 "SWITCH_FAULT" 1 "SWITCH_OFF" 2 "SWITCH_ON" 0 "SWITCH_SNA" ;
VAL_ 963 VCRIGHT_frontSeatLiftDown 3 "SWITCH_FAULT" 1 "SWITCH_OFF" 2 "SWITCH_ON" 0 "SWITCH_SNA" ;
VAL_ 963 VCRIGHT_frontSeatLiftUp 3 "SWITCH_FAULT" 1 "SWITCH_OFF" 2 "SWITCH_ON" 0 "SWITCH_SNA" ;
VAL_ 963 VCRIGHT_frontSeatLumbarDown 3 "SWITCH_FAULT" 1 "SWITCH_OFF" 2 "SWITCH_ON" 0 "SWITCH_SNA" ;
VAL_ 963 VCRIGHT_frontSeatLumbarIn 3 "SWITCH_FAULT" 1 "SWITCH_OFF" 2 "SWITCH_ON" 0 "SWITCH_SNA" ;
VAL_ 963 VCRIGHT_frontSeatLumbarOut 3 "SWITCH_FAULT" 1 "SWITCH_OFF" 2 "SWITCH_ON" 0 "SWITCH_SNA" ;
VAL_ 963 VCRIGHT_frontSeatLumbarUp 3 "SWITCH_FAULT" 1 "SWITCH_OFF" 2 "SWITCH_ON" 0 "SWITCH_SNA" ;
VAL_ 963 VCRIGHT_frontSeatTiltDown 3 "SWITCH_FAULT" 1 "SWITCH_OFF" 2 "SWITCH_ON" 0 "SWITCH_SNA" ;
VAL_ 963 VCRIGHT_frontSeatTiltUp 3 "SWITCH_FAULT" 1 "SWITCH_OFF" 2 "SWITCH_ON" 0 "SWITCH_SNA" ;
VAL_ 963 VCRIGHT_frontSeatTrackBack 3 "SWITCH_FAULT" 1 "SWITCH_OFF" 2 "SWITCH_ON" 0 "SWITCH_SNA" ;
VAL_ 963 VCRIGHT_frontSeatTrackForward 3 "SWITCH_FAULT" 1 "SWITCH_OFF" 2 "SWITCH_ON" 0 "SWITCH_SNA" ;
VAL_ 963 VCRIGHT_rearCenterBuckleSwitch 3 "SWITCH_FAULT" 1 "SWITCH_OFF" 2 "SWITCH_ON" 0 "SWITCH_SNA" ;
VAL_ 963 VCRIGHT_rearRightBuckleSwitch 3 "SWITCH_FAULT" 1 "SWITCH_OFF" 2 "SWITCH_ON" 0 "SWITCH_SNA" ;
VAL_ 964 PCS_infoIndex 0 "DEPRECATED_0" 1 "DEPRECATED_1" 2 "DEPRECATED_2" 3 "DEPRECATED_3" 4 "DEPRECATED_4" 5 "DEPRECATED_5" 6 "DEPRECATED_6" 7 "DEPRECATED_7" 8 "DEPRECATED_8" 9 "DEPRECATED_9" 10 "BUILD_HWID_COMPONENTID" 11 "PCBAID_ASSYID_USAGEID" 13 "APP_CRC" 14 "BOOTLOADER_SVN" 15 "BOOTLOADER_CRC" 16 "SUBCOMPONENT" 17 "APP_GITHASH" 18 "BOOTLOADER_GITHASH" 19 "VERSION_DEPRECATED" 20 "UDS_PROTOCOL_BOOTCRC" 22 "VARIANTCRC" 25 "PACKAGE_PN_1_7" 26 "PACKAGE_PN_8_14" 27 "PACKAGE_PN_15_20" 29 "PACKAGE_SN_1_7" 30 "PACKAGE_SN_8_14" 31 "SUBCOMPONENT_GITHASH" 255 "END" ;
VAL_ 964 PCS_buildType 0 "UNKNOWN_BUILD" 1 "PLATFORM_BUILD" 2 "LOCAL_BUILD" 3 "TRACEABLE_CI_BUILD" 4 "MFG_BUILD" ;
VAL_ 968 EPBL_matrixIndex 0 "AlertMatrix0" 1 "AlertMatrix1" 2 "AlertMatrix2" 3 "AlertMatrix3" 4 "AlertMatrix4" ;
VAL_ 969 VCSEC_BLEEndpointInfoIndex 0 "LEFT_INFO" 1 "RIGHT_INFO" 2 "REAR_INFO" 3 "CENTER_INFO" 4 "LEFT_APP_GITHASH" 5 "RIGHT_APP_GITHASH" 6 "REAR_APP_GITHASH" 7 "CENTER_APP_GITHASH" ;
VAL_ 970 APS_apbGpioState 0 "PWR_DOWN_REBOOT" 1 "DISABLED" 2 "CRITICAL" 3 "HEALTHY" ;
VAL_ 970 APS_apbStatusMonitorState 0 "STATE_UNKNOWN" 1 "STATE_PWR_OFF" 2 "STATE_INIT" 3 "STATE_NOMINAL" 4 "STATE_CRITICAL" 5 "STATE_SHUTTING_DOWN" 6 "STATE_RECOVERY" 7 "NUM_STATES" ;
VAL_ 970 APS_appGpioState 0 "PWR_DOWN_REBOOT" 1 "DISABLED" 2 "CRITICAL" 3 "HEALTHY" ;
VAL_ 970 APS_appStatusMonitorState 0 "STATE_UNKNOWN" 1 "STATE_PWR_OFF" 2 "STATE_INIT" 3 "STATE_NOMINAL" 4 "STATE_CRITICAL" 5 "STATE_SHUTTING_DOWN" 6 "STATE_RECOVERY" 7 "NUM_STATES" ;
VAL_ 970 APS_canMaster 0 "APS" 1 "APP" 2 "APB" 3 "SNA" ;
VAL_ 970 APS_eacInternalState 0 "STATE_INIT" 1 "STATE_MOMENTARY" 2 "STATE_CONTINUOUS" 3 "STATE_AUTOPARK" 4 "STATE_INHIBIT" 5 "STATE_OVERRIDE" 6 "STATE_LSS" 7 "NUM_STATES" ;
VAL_ 970 APS_vehBehaviorState 0 "STATE_UNKNOWN" 1 "STATE_APS_AVAILABLE" 2 "STATE_APS_CONTROL" 3 "STATE_APS_BRIDGE_APP" 4 "STATE_APS_BRIDGE_APB" 5 "STATE_APS_FAIL_SAFE" 6 "STATE_APS_OVERRIDE" 7 "NUM_STATES" ;
VAL_ 979 UI_airbagCutoffSwState 0 "PASSENGER_AIRBAG_ON" 1 "PASSENGER_AIRBAG_OFF" 2 "SNA" ;
VAL_ 979 UI_warningIndicatorStatus 0 "WARNING_LAMP_OFF" 1 "WARNING_LAMP_ON" 3 "SNA" ;
VAL_ 981 ESP_matrixIndex 0 "AlertMatrix0" 1 "AlertMatrix1" 2 "AlertMatrix2" 3 "AlertMatrix3" 4 "AlertMatrix4" ;
VAL_ 984 UI_elevation 65535 "SNA" ;
VAL_ 985 UI_mapSpeedLimitUnits 0 "MPH" 1 "KPH" ;
VAL_ 985 UI_userSpeedOffsetUnits 0 "MPH" 1 "KPH" ;
VAL_ 986 DAS_TE_multiplexer 0 "START" 1 "LEFT_LANE" 2 "RIGHT_LANE" 3 "HPP" 4 "NAV" 5 "VL" 6 "ACC" 7 "FCM" 8 "IPSO" 9 "END" ;
VAL_ 986 DAS_TE_eventType 0 "NONE" 1 "DRIVER_INTERVENTION" 2 "AUTOSTEER_ABORT" 3 "ANGLE_SATURATION" 4 "ANGLE_RATE_SATURATION" 5 "LDW_LEFT" 6 "LDW_RIGHT" 7 "ALC_ABORT_LEFT" 8 "ALC_ABORT_RIGHT" 9 "SCA_LEFT" 10 "SCA_RIGHT" 11 "TM_EVENT_IPSO" 12 "TM_EVENT_CRASH" 13 "TM_EVENT_AEB" 14 "TM_EVENT_ROB" ;
VAL_ 986 DAS_TE_lcAbortReason 0 "HM_LANE_VIEW_RANGE" 1 "HM_VIRTUAL_LANE_NO_INPUTS" 16 "CAM_MSG_MIA" 17 "CAM_WATCHDOG" 18 "TRAILER_MODE" 19 "SIDE_COLLISION_IMMINENT" 20 "EPAS_EAC_DENIED" 21 "COMPONENT_MIA" 22 "CRUISE_FAULT" 23 "CID_SWITCH_DISABLED" 24 "DRIVING_OFF_NAV" 25 "VEHICLE_SPEED_ABOVE_MAX" 26 "FOLLOWER_OUTPUT_INVALID" 27 "PLANNER_OUTPUT_INVALID" 28 "EPAS_ERROR_CODE" 29 "ACC_CANCEL" 30 "CAMERA_FAILSAFES" 31 "NO_ABORT" ;
VAL_ 994 VCLEFT_FLMapLightStatus 0 "OFF" 1 "ON" 2 "FAULT" 3 "SNA" ;
VAL_ 994 VCLEFT_FRMapLightStatus 0 "OFF" 1 "ON" 2 "FAULT" 3 "SNA" ;
VAL_ 994 VCLEFT_RLMapLightStatus 0 "OFF" 1 "ON" 2 "FAULT" 3 "SNA" ;
VAL_ 994 VCLEFT_RRMapLightStatus 0 "OFF" 1 "ON" 2 "FAULT" 3 "SNA" ;
VAL_ 994 VCLEFT_brakeLightStatus 0 "OFF" 1 "ON" 2 "FAULT" 3 "SNA" ;
VAL_ 994 VCLEFT_dynamicBrakeLightStatus 2 "DYNAMIC_BRAKE_LIGHT_ACTIVE_HIGH" 1 "DYNAMIC_BRAKE_LIGHT_ACTIVE_LOW" 0 "DYNAMIC_BRAKE_LIGHT_OFF" ;
VAL_ 994 VCLEFT_brakeTrailerLightStatus 0 "OFF" 1 "ON" 2 "FAULT" 3 "SNA" ;
VAL_ 994 VCLEFT_frontRideHeight 128 "SNA" ;
VAL_ 994 VCLEFT_leftTurnTrailerLightStatu 2 "LIGHT_FAULT" 0 "LIGHT_OFF" 1 "LIGHT_ON" 3 "LIGHT_SNA" ;
VAL_ 994 VCLEFT_rearRideHeight 128 "SNA" ;
VAL_ 994 VCLEFT_reverseTrailerLightStatus 2 "LIGHT_FAULT" 0 "LIGHT_OFF" 1 "LIGHT_ON" 3 "LIGHT_SNA" ;
VAL_ 994 VCLEFT_rightTrnTrailerLightStatu 2 "LIGHT_FAULT" 0 "LIGHT_OFF" 1 "LIGHT_ON" 3 "LIGHT_SNA" ;
VAL_ 994 VCLEFT_fogTrailerLightStatus 0 "OFF" 1 "ON" 2 "FAULT" 3 "SNA" ;
VAL_ 994 VCLEFT_tailLightStatus 0 "OFF" 1 "ON" 2 "FAULT" 3 "SNA" ;
VAL_ 994 VCLEFT_tailTrailerLightStatus 0 "OFF" 1 "ON" 2 "FAULT" 3 "SNA" ;
VAL_ 994 VCLEFT_turnSignalStatus 0 "OFF" 1 "ON" 2 "FAULT" 3 "SNA" ;
VAL_ 995 VCRIGHT_brakeLightStatus 0 "OFF" 1 "ON" 2 "FAULT" 3 "SNA" ;
VAL_ 995 VCRIGHT_interiorTrunkLightStatus 2 "LIGHT_FAULT" 0 "LIGHT_OFF" 1 "LIGHT_ON" 3 "LIGHT_SNA" ;
VAL_ 995 VCRIGHT_rearFogLightStatus 0 "OFF" 1 "ON" 2 "FAULT" 3 "SNA" ;
VAL_ 995 VCRIGHT_reverseLightStatus 0 "OFF" 1 "ON" 2 "FAULT" 3 "SNA" ;
VAL_ 995 VCRIGHT_tailLightStatus 0 "OFF" 1 "ON" 2 "FAULT" 3 "SNA" ;
VAL_ 995 VCRIGHT_turnSignalStatus 0 "OFF" 1 "ON" 2 "FAULT" 3 "SNA" ;
VAL_ 1000 EPBR_matrixIndex 0 "AlertMatrix0" 1 "AlertMatrix1" 2 "AlertMatrix2" 3 "AlertMatrix3" 4 "AlertMatrix4" ;
VAL_ 1001 DAS_hazardLightRequest 0 "OFF" 1 "ON" 2 "UNUSED" 3 "SNA" ;
VAL_ 1001 DAS_headlightRequest 0 "OFF" 1 "ON" 3 "INVALID" ;
VAL_ 1001 DAS_heaterRequest 0 "SNA" 1 "OFF" 2 "ON" ;
VAL_ 1001 DAS_highLowBeamDecision 0 "UNDECIDED" 1 "OFF" 2 "ON" 3 "SNA" ;
VAL_ 1001 DAS_highLowBeamOffReason 0 "ON" 1 "OFF_REASON_MOVING_VISION_TARGET" 2 "OFF_REASON_MOVING_RADAR_TARGET" 3 "OFF_REASON_AMBIENT_LIGHT" 4 "OFF_REASON_HEAD_LIGHT" 5 "OFF_REASON_SNA" ;
VAL_ 1001 DAS_turnIndicatorRequest 0 "NONE" 1 "LEFT" 2 "RIGHT" 3 "CANCEL" ;
VAL_ 1001 DAS_turnIndicatorRequestReason 0 "NONE" 1 "ACTIVE_NAV_LANE_CHANGE" 2 "ACTIVE_SPEED_LANE_CHANGE" 3 "ACTIVE_FORK" 4 "CANCEL_LANE_CHANGE" 5 "CANCEL_FORK" ;
VAL_ 1001 DAS_wiperSpeed 0 "OFF" 1 "1" 2 "2" 3 "3" 4 "4" 5 "5" 6 "6" 7 "7" 8 "8" 9 "9" 10 "10" 11 "11" 12 "12" 13 "13" 14 "14" 15 "INVALID" ;
VAL_ 1009 VCFRONT_DRLLeftStatus 0 "OFF" 1 "ON" 2 "FAULT" 3 "SNA" ;
VAL_ 1009 VCFRONT_DRLRightStatus 0 "OFF" 1 "ON" 2 "FAULT" 3 "SNA" ;
VAL_ 1009 VCFRONT_ambientLightingBrightnes 255 "SNA" ;
VAL_ 1009 VCFRONT_fogLeftStatus 0 "OFF" 1 "ON" 2 "FAULT" 3 "SNA" ;
VAL_ 1009 VCFRONT_fogRightStatus 0 "OFF" 1 "ON" 2 "FAULT" 3 "SNA" ;
VAL_ 1009 VCFRONT_hazardLightRequest 0 "NONE" 1 "BUTTON" 2 "LOCK" 3 "UNLOCK" 4 "MISLOCK" 5 "CRASH" 6 "CAR_ALARM" 7 "DAS" ;
VAL_ 1009 VCFRONT_highBeamLeftStatus 0 "OFF" 1 "ON" 2 "FAULT" 3 "SNA" ;
VAL_ 1009 VCFRONT_highBeamRightStatus 0 "OFF" 1 "ON" 2 "FAULT" 3 "SNA" ;
VAL_ 1009 VCFRONT_indicatorLeftRequest 0 "OFF" 1 "ACTIVE_LOW" 2 "ACTIVE_HIGH" ;
VAL_ 1009 VCFRONT_indicatorRightRequest 0 "OFF" 1 "ACTIVE_LOW" 2 "ACTIVE_HIGH" ;
VAL_ 1009 VCFRONT_lowBeamLeftStatus 0 "OFF" 1 "ON" 2 "FAULT" 3 "SNA" ;
VAL_ 1009 VCFRONT_lowBeamRightStatus 0 "OFF" 1 "ON" 2 "FAULT" 3 "SNA" ;
VAL_ 1009 VCFRONT_parkLeftStatus 0 "OFF" 1 "ON" 2 "FAULT" 3 "SNA" ;
VAL_ 1009 VCFRONT_parkRightStatus 0 "OFF" 1 "ON" 2 "FAULT" 3 "SNA" ;
VAL_ 1009 VCFRONT_sideMarkersStatus 0 "OFF" 1 "ON" 2 "FAULT" 3 "SNA" ;
VAL_ 1009 VCFRONT_sideRepeaterLeftStatus 0 "OFF" 1 "ON" 2 "FAULT" 3 "SNA" ;
VAL_ 1009 VCFRONT_sideRepeaterRightStatus 0 "OFF" 1 "ON" 2 "FAULT" 3 "SNA" ;
VAL_ 1009 VCFRONT_simLatchingStalk 0 "IDLE" 1 "LEFT" 2 "RIGHT" 3 "SNA" ;
VAL_ 1009 VCFRONT_switchLightingBrightness 255 "SNA" ;
VAL_ 1009 VCFRONT_turnSignalLeftStatus 0 "OFF" 1 "ON" 2 "FAULT" 3 "SNA" ;
VAL_ 1009 VCFRONT_turnSignalRightStatus 0 "OFF" 1 "ON" 2 "FAULT" 3 "SNA" ;
VAL_ 1010 BMS_kwhCounter_Id 0 "MUX0" 1 "MUX1" 2 "MUX2" 3 "MUX3" 4 "END" ;
VAL_ 1011 UI_odometer 16777215 "SNA" ;
VAL_ 1012 APP_cameraPosition 0 "INVALID" 1 "MAIN" 2 "NARROW" 3 "FISHEYE" 4 "L_PILLAR" 5 "R_PILLAR" 6 "L_REPEATER" 7 "R_REPEATER" 8 "BACKUP" ;
VAL_ 1012 APP_mainCamExtPitchCal 511 "SNA" ;
VAL_ 1012 APP_mainCamExtYawCal 511 "SNA" ;
VAL_ 1012 APP_mainCalibTime 127 "SNA" ;
VAL_ 1012 APP_mainCalibProgress 127 "SNA" ;
VAL_ 1012 APP_narrowCamExtPitchCal 511 "SNA" ;
VAL_ 1012 APP_narrowCamExtYawCal 511 "SNA" ;
VAL_ 1012 APP_narrowCalibTime 127 "SNA" ;
VAL_ 1012 APP_narrowCalibProgress 127 "SNA" ;
VAL_ 1012 APP_fisheyeCamExtPitchCal 511 "SNA" ;
VAL_ 1012 APP_fisheyeCamExtYawCal 511 "SNA" ;
VAL_ 1012 APP_fisheyeCalibTime 127 "SNA" ;
VAL_ 1012 APP_fisheyeCalibProgress 127 "SNA" ;
VAL_ 1012 APP_lPillarCamExtPitchCal 511 "SNA" ;
VAL_ 1012 APP_lPillarCamExtYawCal 511 "SNA" ;
VAL_ 1012 APP_lPillarCalibTime 127 "SNA" ;
VAL_ 1012 APP_lPillarCalibProgress 127 "SNA" ;
VAL_ 1012 APP_rPillarCamExtPitchCal 511 "SNA" ;
VAL_ 1012 APP_rPillarCamExtYawCal 511 "SNA" ;
VAL_ 1012 APP_rPillarCalibTime 127 "SNA" ;
VAL_ 1012 APP_rPillarCalibProgress 127 "SNA" ;
VAL_ 1012 APP_lRepeatCamExtPitchCal 511 "SNA" ;
VAL_ 1012 APP_lRepeatCamExtYawCal 511 "SNA" ;
VAL_ 1012 APP_lRepeatCalibTime 127 "SNA" ;
VAL_ 1012 APP_lRepeatCalibProgress 127 "SNA" ;
VAL_ 1012 APP_rRepeatCamExtPitchCal 511 "SNA" ;
VAL_ 1012 APP_rRepeatCamExtYawCal 511 "SNA" ;
VAL_ 1012 APP_rRepeatCalibTime 127 "SNA" ;
VAL_ 1012 APP_rRepeatCalibProgress 127 "SNA" ;
VAL_ 1012 APP_backupCamExtPitchCal 511 "SNA" ;
VAL_ 1012 APP_backupCamExtYawCal 511 "SNA" ;
VAL_ 1012 APP_backupCalibTime 127 "SNA" ;
VAL_ 1012 APP_backupCalibProgress 127 "SNA" ;
VAL_ 1013 VCFRONT_DRLLeftStatus 2 "LIGHT_FAULT" 0 "LIGHT_OFF" 1 "LIGHT_ON" 3 "LIGHT_SNA" ;
VAL_ 1013 VCFRONT_DRLLeftStatus 2 "LIGHT_FAULT" 0 "LIGHT_OFF" 1 "LIGHT_ON" 3 "LIGHT_SNA" ;
VAL_ 1013 VCFRONT_DRLRightStatus 2 "LIGHT_FAULT" 0 "LIGHT_OFF" 1 "LIGHT_ON" 3 "LIGHT_SNA" ;
VAL_ 1013 VCFRONT_ambientLightingBrightnes 255 "SNA" ;
VAL_ 1013 VCFRONT_fogLeftStatus 2 "LIGHT_FAULT" 0 "LIGHT_OFF" 1 "LIGHT_ON" 3 "LIGHT_SNA" ;
VAL_ 1013 VCFRONT_fogRightStatus 2 "LIGHT_FAULT" 0 "LIGHT_OFF" 1 "LIGHT_ON" 3 "LIGHT_SNA" ;
VAL_ 1013 VCFRONT_hazardLightRequest 1 "HAZARD_REQUEST_BUTTON" 6 "HAZARD_REQUEST_CAR_ALARM" 5 "HAZARD_REQUEST_CRASH" 7 "HAZARD_REQUEST_DAS" 2 "HAZARD_REQUEST_LOCK" 4 "HAZARD_REQUEST_MISLOCK" 0 "HAZARD_REQUEST_NONE" 8 "HAZARD_REQUEST_UDS" 3 "HAZARD_REQUEST_UNLOCK" ;
VAL_ 1013 VCFRONT_highBeamLeftStatus 2 "LIGHT_FAULT" 0 "LIGHT_OFF" 1 "LIGHT_ON" 3 "LIGHT_SNA" ;
VAL_ 1013 VCFRONT_highBeamRightStatus 2 "LIGHT_FAULT" 0 "LIGHT_OFF" 1 "LIGHT_ON" 3 "LIGHT_SNA" ;
VAL_ 1013 VCFRONT_indicatorLeftRequest 2 "TURN_SIGNAL_ACTIVE_HIGH" 1 "TURN_SIGNAL_ACTIVE_LOW" 0 "TURN_SIGNAL_OFF" ;
VAL_ 1013 VCFRONT_indicatorRightRequest 2 "TURN_SIGNAL_ACTIVE_HIGH" 1 "TURN_SIGNAL_ACTIVE_LOW" 0 "TURN_SIGNAL_OFF" ;
VAL_ 1013 VCFRONT_lowBeamLeftStatus 2 "LIGHT_FAULT" 0 "LIGHT_OFF" 1 "LIGHT_ON" 3 "LIGHT_SNA" ;
VAL_ 1013 VCFRONT_lowBeamRightStatus 2 "LIGHT_FAULT" 0 "LIGHT_OFF" 1 "LIGHT_ON" 3 "LIGHT_SNA" ;
VAL_ 1013 VCFRONT_parkLeftStatus 2 "LIGHT_FAULT" 0 "LIGHT_OFF" 1 "LIGHT_ON" 3 "LIGHT_SNA" ;
VAL_ 1013 VCFRONT_parkRightStatus 2 "LIGHT_FAULT" 0 "LIGHT_OFF" 1 "LIGHT_ON" 3 "LIGHT_SNA" ;
VAL_ 1013 VCFRONT_sideMarkersStatus 2 "LIGHT_FAULT" 0 "LIGHT_OFF" 1 "LIGHT_ON" 3 "LIGHT_SNA" ;
VAL_ 1013 VCFRONT_sideRepeaterLeftStatus 2 "LIGHT_FAULT" 0 "LIGHT_OFF" 1 "LIGHT_ON" 3 "LIGHT_SNA" ;
VAL_ 1013 VCFRONT_sideRepeaterRightStatus 2 "LIGHT_FAULT" 0 "LIGHT_OFF" 1 "LIGHT_ON" 3 "LIGHT_SNA" ;
VAL_ 1013 VCFRONT_simLatchingStalk 0 "SIMULATED_LATCHING_STALK_IDLE" 1 "SIMULATED_LATCHING_STALK_LEFT" 2 "SIMULATED_LATCHING_STALK_RIGHT" 3 "SIMULATED_LATCHING_STALK_SNA" ;
VAL_ 1013 VCFRONT_switchLightingBrightness 255 "SNA" ;
VAL_ 1013 VCFRONT_turnSignalLeftStatus 2 "LIGHT_FAULT" 0 "LIGHT_OFF" 1 "LIGHT_ON" 3 "LIGHT_SNA" ;
VAL_ 1013 VCFRONT_turnSignalRightStatus 2 "LIGHT_FAULT" 0 "LIGHT_OFF" 1 "LIGHT_ON" 3 "LIGHT_SNA" ;
VAL_ 1016 UI_accFollowDistanceSetting 0 "1" 1 "2" 2 "3" 3 "4" 4 "5" 5 "6" 6 "7" 7 "SNA" ;
VAL_ 1016 UI_autopilotControlRequest 0 "LEGACY_LAT_CTRL" 1 "NEXT_GEN_CTRL" ;
VAL_ 1016 UI_curvSpeedAdaptDisable 0 "ON" 1 "OFF" ;
VAL_ 1016 UI_curvatureDatabaseOnly 0 "OFF" 1 "ON" ;
VAL_ 1016 UI_driveOnMapsEnable 0 "OFF" 1 "ON" ;
VAL_ 1016 UI_drivingSide 0 "LEFT" 1 "RIGHT" 2 "UNKNOWN" ;
VAL_ 1016 UI_exceptionListEnable 0 "OFF" 1 "ON" ;
VAL_ 1016 UI_followNavRouteEnable 0 "OFF" 1 "ON" ;
VAL_ 1016 UI_forksEnable 0 "OFF" 1 "ON" ;
VAL_ 1016 UI_fuseHPPDisable 0 "ON" 1 "OFF" ;
VAL_ 1016 UI_fuseLanesDisable 0 "ON" 1 "OFF" ;
VAL_ 1016 UI_fuseVehiclesDisable 0 "ON" 1 "OFF" ;
VAL_ 1016 UI_handsOnRequirementDisable 0 "ON" 1 "OFF" ;
VAL_ 1016 UI_lssElkEnabled 0 "OFF" 1 "ON" ;
VAL_ 1016 UI_lssLdwEnabled 0 "OFF" 1 "ON" ;
VAL_ 1016 UI_lssLkaEnabled 0 "OFF" 1 "ON" ;
VAL_ 1016 UI_roadCheckDisable 0 "ON" 1 "OFF" ;
VAL_ 1016 UI_selfParkRequest 0 "NONE" 1 "SELF_PARK_FORWARD" 2 "SELF_PARK_REVERSE" 3 "ABORT" 4 "PRIME" 5 "PAUSE" 6 "RESUME" 7 "AUTO_SUMMON_FORWARD" 8 "AUTO_SUMMON_REVERSE" 9 "AUTO_SUMMON_CANCEL" 10 "AUTO_SUMMON_PRIMED" 15 "SNA" ;
VAL_ 1016 UI_source3D 0 "Z_FROM_MAP" 1 "Z_FROM_PATH_PREDICTION" 2 "XYZ_PREDICTION" ;
VAL_ 1016 UI_summonEntryType 0 "STRAIGHT" 1 "TURN_RIGHT" 2 "TURN_LEFT" 3 "SNA" ;
VAL_ 1016 UI_summonExitType 0 "STRAIGHT" 1 "TURN_RIGHT" 2 "TURN_LEFT" 3 "SNA" ;
VAL_ 1016 UI_summonReverseDist 63 "SNA" ;
VAL_ 1016 UI_ulcBlindSpotConfig 0 "STANDARD" 1 "AGGRESSIVE" 2 "MAD_MAX" ;
VAL_ 1016 UI_ulcSpeedConfig 0 "7MPH" 1 "10MPH" 2 "15MPH" ;
VAL_ 1016 UI_visionSpeedType 0 "DISABLED" 1 "ONE_SECOND" 2 "TWO_SECOND" 3 "OPTIMIZED" ;
VAL_ 1017 VCSEC_matrixIndex 0 "AlertMatrix0" 1 "AlertMatrix1" 2 "AlertMatrix2" 3 "AlertMatrix3" ;
VAL_ 1018 APP_backupCameraLUX 254 "SATURATED" 255 "SNA" ;
VAL_ 1018 APP_fisheyeCameraLUX 254 "SATURATED" 255 "SNA" ;
VAL_ 1018 APP_lPillarCameraLUX 254 "SATURATED" 255 "SNA" ;
VAL_ 1018 APP_lRepeatCameraLUX 254 "SATURATED" 255 "SNA" ;
VAL_ 1018 APP_mainCameraLUX 254 "SATURATED" 255 "SNA" ;
VAL_ 1018 APP_narrowCameraLUX 254 "SATURATED" 255 "SNA" ;
VAL_ 1018 APP_rPillarCameraLUX 254 "SATURATED" 255 "SNA" ;
VAL_ 1018 APP_rRepeatCameraLUX 254 "SATURATED" 255 "SNA" ;
VAL_ 1020 APP_decisionTemperature 0 "UNKNOWN" ;
VAL_ 1020 APP_parkerATemperature 0 "UNKNOWN" ;
VAL_ 1020 APP_parkerBTemperature 0 "UNKNOWN" ;
VAL_ 1020 APP_parkerExtTemperature 0 "UNKNOWN" ;
VAL_ 1020 APP_pascalExtTemperature 0 "UNKNOWN" ;
VAL_ 1020 APP_pascalHeaterDecision 0 "OFF" 1 "ON" ;
VAL_ 1020 APP_pascalTemperature 0 "UNKNOWN" ;
VAL_ 1021 UI_autopilotControlIndex 0 "0" 1 "1" 2 "2" 3 "3" 4 "4" 5 "5" 6 "6" 7 "7" ;
VAL_ 1021 UI_blindspotDistance 0 "DEFAULT" 1 "0P5_M" 2 "1_M" 3 "2_M" 4 "4_M" 5 "OFF" ;
VAL_ 1021 UI_blindspotMinSpeed 0 "DEFAULT" 1 "5_KPH" 2 "10_KPH" 3 "15_KPH" 4 "20_KPH" 5 "25_KPH" 6 "30_KPH" 7 "35_KPH" 8 "40_KPH" 9 "45_KPH" 10 "OFF" ;
VAL_ 1021 UI_blindspotTTC 0 "DEFAULT" 1 "0P5_S" 2 "1_S" 3 "2_S" 4 "4_S" 5 "3_S" 6 "5_S" 7 "OFF" ;
VAL_ 1021 UI_donAlcProgGoreAbortThres 0 "DEFAULT" 1 "0P00" 2 "0P05" 3 "0P10" 4 "0P15" 5 "0P20" 6 "0P25" 7 "0P30" 8 "0P35" 9 "0P40" ;
VAL_ 1021 UI_donDisableAutoWiperDuration 0 "DEFAULT" 1 "5_S" 2 "15_S" 3 "30_S" 4 "60_S" 5 "120_S" 6 "OFF" ;
VAL_ 1021 UI_donDisableCutin 0 "OFF" 1 "ON" ;
VAL_ 1021 UI_donDisableOnAutoWiperSpeed 0 "OFF" 1 "1" 2 "2" 3 "3" 4 "4" 5 "5" 6 "6" 7 "7" 8 "8" 9 "9" 10 "10" 11 "11" 12 "12" 13 "13" 14 "14" 15 "INVALID" ;
VAL_ 1021 UI_donMinGoreWidthForAbortMap 0 "DEFAULT" 1 "0_M" 2 "0P5_M" 3 "1_M" 4 "1P5_M" 5 "2_M" 6 "2P5_M" 7 "3_M" 8 "3P5_M" 9 "4_M" 10 "4P5_M" 11 "5_M" ;
VAL_ 1021 UI_donMinGoreWidthForAbortNotMap 0 "DEFAULT" 1 "0_M" 2 "0P5_M" 3 "1_M" 4 "1P5_M" 5 "2_M" 6 "2P5_M" 7 "3_M" 8 "3P5_M" 9 "4_M" 10 "4P5_M" 11 "5_M" ;
VAL_ 1021 UI_donStopEndOfRampBuffer 0 "DEFAULT" 1 "15_M" 2 "30_M" 3 "45_M" 4 "OFF" ;
VAL_ 1021 UI_hovEnabled 0 "OFF" 1 "ON" ;
VAL_ 1022 DI_brakeFLTemp 1023 "SNA" ;
VAL_ 1022 DI_brakeFRTemp 1023 "SNA" ;
VAL_ 1022 DI_brakeRLTemp 1023 "SNA" ;
VAL_ 1022 DI_brakeRRTemp 1023 "SNA" ;
